// *************************************************************************** *
// *                                                                           *
// * Description:         CANDB File                                           *
// * Generated at:        2025-10-17 10:36                                     *
// * System:              SPA8410_Final2                                       *
// * Variant:             ConfigurationsSPA3d2                                 *
// * Network:             ASDM2CANFD                                           *
// *                                                                           *
// *************************************************************************** *
VERSION "ASDM2CANFD"

NS_ :

BS_ :

BU_ :  ASDM FSRL FSRR
VAL_TABLE_ ElevAlignment_States_FR 2 "MBASC_ELEV_MISALIGNED" 1 "MBASC_ELEV_ALIGNED" 0 "MBASC_ELEV_CALIBRATING" ;
VAL_TABLE_ ElevAlignment_States_FL 2 "MBASC_ELEV_MISALIGNED" 1 "MBASC_ELEV_ALIGNED" 0 "MBASC_ELEV_CALIBRATING" ;

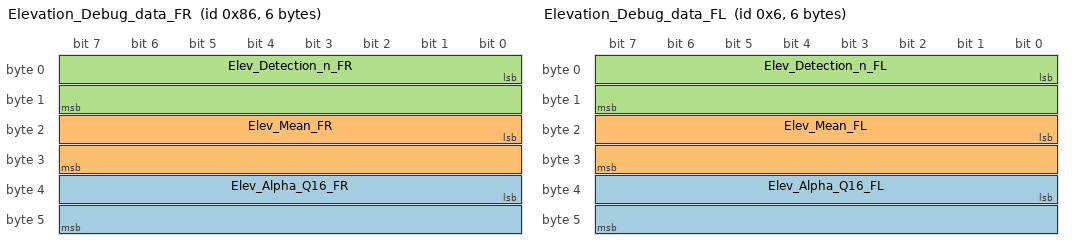
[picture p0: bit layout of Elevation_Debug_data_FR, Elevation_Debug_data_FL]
BO_ 134 Elevation_Debug_data_FR: 6 FSRR
 SG_ Elev_Alpha_Q16_FR : 32|16@1+ (1,0) [0|65535] ""  ASDM
 SG_ Elev_Mean_FR : 16|16@1- (1,0) [-32768|32767] ""  ASDM
 SG_ Elev_Detection_n_FR : 0|16@1+ (1,0) [0|65535] ""  ASDM

BO_ 6 Elevation_Debug_data_FL: 6 FSRL
 SG_ Elev_Alpha_Q16_FL : 32|16@1+ (1,0) [0|65535] ""  ASDM
 SG_ Elev_Mean_FL : 16|16@1- (1,0) [-32768|32767] ""  ASDM
 SG_ Elev_Detection_n_FL : 0|16@1+ (1,0) [0|65535] ""  ASDM

BO_ 917 MB79_PARAMETERS_FR: 24 FSRR
 SG_ Sensor_Serial_Number_FR : 0|192@1+ (1,0) [0|16777215] ""  ASDM

BO_ 789 MB79_PARAMETERS_FL: 24 FSRL
 SG_ Sensor_Serial_Number_FL : 0|192@1+ (1,0) [0|16777215] ""  ASDM

BO_ 898 MB79_SYSTEM_STATUS_FR: 8 FSRR
 SG_ Reserved_2bits_FR : 29|2@1+ (1,0) [0|3] "" Vector__XXX
 SG_ Sensor_Error_Synchronization_Err : 25|1@1+ (1,0) [0|1] "" Vector__XXX
 SG_ Sensor_Error_Supply_Error_FR : 24|1@1+ (1,0) [0|1] "" Vector__XXX
 SG_ Sensor_Error_Software_Incompatib : 27|1@1+ (1,0) [0|1] "" Vector__XXX
 SG_ Sensor_Error_Security_Breach_FR : 28|1@1+ (1,0) [0|1] "" Vector__XXX
 SG_ Sensor_Error_Position_Error_FR : 19|1@1+ (1,0) [0|1] "" Vector__XXX
 SG_ Sensor_Error_Misaligned_FR : 20|1@1+ (1,0) [0|1] "" Vector__XXX
 SG_ Sensor_Error_Internal_Failure_FR : 17|1@1+ (1,0) [0|1] "" Vector__XXX
 SG_ Sensor_Error_Interference_FR : 22|1@1+ (1,0) [0|1] "" Vector__XXX
 SG_ Sensor_Error_Initialization_FR : 23|1@1+ (1,0) [0|1] "" Vector__XXX
 SG_ Sensor_Error_HW_Error_FR : 26|1@1+ (1,0) [0|1] "" Vector__XXX
 SG_ Sensor_Error_Communication_FR : 16|1@1+ (1,0) [0|1] "" Vector__XXX
 SG_ Sensor_Error_Calibration_Error_F : 18|1@1+ (1,0) [0|1] "" Vector__XXX
 SG_ Sensor_Error_Blocked_FR : 21|1@1+ (1,0) [0|1] "" Vector__XXX
 SG_ Heater_Trigger_FR : 31|1@1+ (1,0) [0|1] "" Vector__XXX
 SG_ Sensor_Operation_Mode_FR : 12|4@1+ (1,0) [0|15] ""  ASDM
 SG_ Clock_SystemStatus_FR : 8|4@1+ (1,0) [0|15] ""  ASDM
 SG_ CRC_SystemStatus_FR : 0|8@1+ (1,0) [0|255] ""  ASDM

BO_ 770 MB79_SYSTEM_STATUS_FL: 8 FSRL
 SG_ Reserved_2bits_FL : 29|2@1+ (1,0) [0|3] "" Vector__XXX
 SG_ Sensor_Error_Synchronizatio_0000 : 25|1@1+ (1,0) [0|1] "" Vector__XXX
 SG_ Sensor_Error_Supply_Error_FL : 24|1@1+ (1,0) [0|1] "" Vector__XXX
 SG_ Sensor_Error_Software_Incom_0000 : 27|1@1+ (1,0) [0|1] "" Vector__XXX
 SG_ Sensor_Error_Security_Breach_FL : 28|1@1+ (1,0) [0|1] "" Vector__XXX
 SG_ Sensor_Error_Position_Error_FL : 19|1@1+ (1,0) [0|1] "" Vector__XXX
 SG_ Sensor_Error_Misaligned_FL : 20|1@1+ (1,0) [0|1] "" Vector__XXX
 SG_ Sensor_Error_Internal_Failure_FL : 17|1@1+ (1,0) [0|1] "" Vector__XXX
 SG_ Sensor_Error_Interference_FL : 22|1@1+ (1,0) [0|1] "" Vector__XXX
 SG_ Sensor_Error_Initialization_FL : 23|1@1+ (1,0) [0|1] "" Vector__XXX
 SG_ Sensor_Error_HW_Error_FL : 26|1@1+ (1,0) [0|1] "" Vector__XXX
 SG_ Sensor_Error_Communication_FL : 16|1@1+ (1,0) [0|1] "" Vector__XXX
 SG_ Sensor_Error_Calibration_Er_0000 : 18|1@1+ (1,0) [0|1] "" Vector__XXX
 SG_ Sensor_Error_Blocked_FL : 21|1@1+ (1,0) [0|1] "" Vector__XXX
 SG_ Heater_Trigger_FL : 31|1@1+ (1,0) [0|1] "" Vector__XXX
 SG_ Sensor_Operation_Mode_FL : 12|4@1+ (1,0) [0|15] ""  ASDM
 SG_ Clock_SystemStatus_FL : 8|4@1+ (1,0) [0|15] ""  ASDM
 SG_ CRC_SystemStatus_FL : 0|8@1+ (1,0) [0|255] ""  ASDM

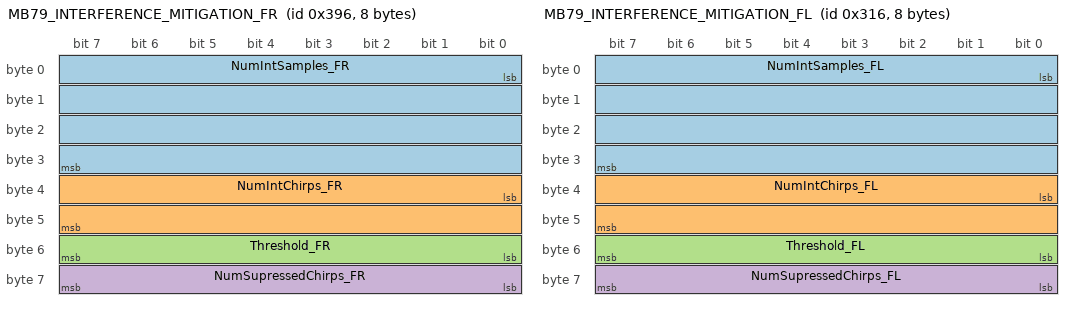
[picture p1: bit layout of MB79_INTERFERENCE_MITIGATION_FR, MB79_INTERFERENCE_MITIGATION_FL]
BO_ 918 MB79_INTERFERENCE_MITIGATION_FR: 8 FSRR
 SG_ NumIntSamples_FR : 0|32@1+ (1,0) [0|16777215] ""  ASDM
 SG_ NumIntChirps_FR : 32|16@1+ (1,0) [0|255] ""  ASDM
 SG_ Threshold_FR : 48|8@1+ (1,0) [0|65535] ""  ASDM
 SG_ NumSupressedChirps_FR : 56|8@1+ (1,0) [0|255] ""  ASDM

BO_ 790 MB79_INTERFERENCE_MITIGATION_FL: 8 FSRL
 SG_ NumIntSamples_FL : 0|32@1+ (1,0) [0|16777215] ""  ASDM
 SG_ NumIntChirps_FL : 32|16@1+ (1,0) [0|255] ""  ASDM
 SG_ Threshold_FL : 48|8@1+ (1,0) [0|65535] ""  ASDM
 SG_ NumSupressedChirps_FL : 56|8@1+ (1,0) [0|255] ""  ASDM

BO_ 2047 AsdmToAllFuncAsdm2CanDiagReqFrame : 64 ASDM
 SG_ AsdmToAllFuncAsdm2CanDiagReqNpdu : 7|512@0+ (1,0) [0|0] "" FSRL, FSRR

BO_ 1937 AsdmToFsrlAsdm2CanDiagReqFrame : 64 ASDM
 SG_ AsdmToFsrlAsdm2CanDiagReqNpdu : 7|512@0+ (1,0) [0|0] "" FSRL

BO_ 1938 AsdmToFsrrAsdm2CanDiagReqFrame : 64 ASDM
 SG_ AsdmToFsrrAsdm2CanDiagReqNpdu : 7|512@0+ (1,0) [0|0] "" FSRR

BO_ 1681 FsrlToAsdmAsdm2CanDiagResFrame : 64 FSRL
 SG_ FsrlToAsdmAsdm2CanDiagResNpdu : 7|512@0+ (1,0) [0|0] "" ASDM

BO_ 1682 FsrrToAsdmAsdm2CanDiagResFrame : 64 FSRR
 SG_ FsrrToAsdmAsdm2CanDiagResNpdu : 7|512@0+ (1,0) [0|0] "" ASDM

BO_ 288 ASDMtoRADAR: 20 ASDM
 SG_ Vehicle_Type : 123|8@0+ (1,0) [0|255] ""  FSRL,FSRR
 SG_ EmblmHeatrOutSts : 117|2@0+ (1,0) [0|0] ""  FSRL,FSRR
 SG_ WshngCycActv : 115|8@0+ (1,0) [0|1] ""  FSRL,FSRR
 SG_ isUsgModSts : 105|4@0+ (1,0) [0|15] ""  FSRL,FSRR
 SG_ PwrLvlElecSubtyp : 3|4@0+ (1,0) [0|15] ""  FSRL,FSRR
 SG_ PwrLvlElecMai : 7|4@0+ (1,0) [0|15] ""  FSRL,FSRR
 SG_ AmbTRawVal : 47|11@0+ (0.1,-70) [-70|134.7] "degC"  FSRL,FSRR
 SG_ AmbTRawQly : 52|2@0+ (1,0) [0|3] ""  FSRL,FSRR
 SG_ BkpOfDstTrvld : 50|21@0+ (1,0) [0|2000000] "km"  FSRL,FSRR
 SG_ CarTiGlb : 15|32@0+ (0.1,0) [0|429496729.5] "s"  FSRL,FSRR
 SG_ CarModSts1 : 81|3@0+ (1,0) [0|7] "N/A"  FSRL,FSRR
 SG_ DrvModReq : 85|4@0+ (1,0) [0|15] ""  FSRL,FSRR
 SG_ VehBattUSysU : 77|8@0+ (0.1,0) [0|25] "Volt"  FSRL,FSRR
 SG_ VehBattUSysUQf : 91|2@0+ (1,0) [0|3] ""  FSRL,FSRR
 SG_ WipgInfoWipgSpdInfo : 94|3@0+ (1,0) [0|7] ""  FSRL,FSRR
 SG_ WipgInfoWiprActv : 97|8@0+ (1,0) [0|255] ""  FSRL,FSRR
 SG_ WipgInfoWiprInWipgAr : 89|8@0+ (1,0) [0|255] ""  FSRL,FSRR

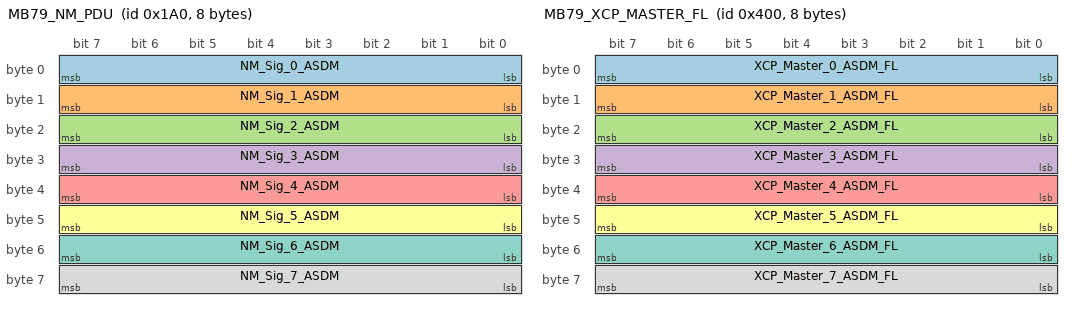
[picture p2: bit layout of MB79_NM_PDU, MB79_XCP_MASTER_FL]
BO_ 416 MB79_NM_PDU: 8 ASDM
 SG_ NM_Sig_0_ASDM : 7|8@0+ (1,0) [0|255] "N/A"  FSRL,FSRR
 SG_ NM_Sig_1_ASDM : 15|8@0+ (1,0) [0|255] "N/A"  FSRL,FSRR
 SG_ NM_Sig_2_ASDM : 23|8@0+ (1,0) [0|255] "N/A"  FSRL,FSRR
 SG_ NM_Sig_3_ASDM : 31|8@0+ (1,0) [0|255] "N/A"  FSRL,FSRR
 SG_ NM_Sig_4_ASDM : 39|8@0+ (1,0) [0|255] "N/A"  FSRL,FSRR
 SG_ NM_Sig_5_ASDM : 47|8@0+ (1,0) [0|255] "N/A"  FSRL,FSRR
 SG_ NM_Sig_6_ASDM : 55|8@0+ (1,0) [0|255] "N/A"  FSRL,FSRR
 SG_ NM_Sig_7_ASDM : 63|8@0+ (1,0) [0|255] "N/A"  FSRL,FSRR

BO_ 1024 MB79_XCP_MASTER_FL: 8 ASDM
 SG_ XCP_Master_0_ASDM_FL : 7|8@0+ (1,0) [0|255] "N/A"  FSRL
 SG_ XCP_Master_1_ASDM_FL : 15|8@0+ (1,0) [0|255] "N/A"  FSRL
 SG_ XCP_Master_2_ASDM_FL : 23|8@0+ (1,0) [0|255] "N/A"  FSRL
 SG_ XCP_Master_3_ASDM_FL : 31|8@0+ (1,0) [0|255] "N/A"  FSRL
 SG_ XCP_Master_4_ASDM_FL : 39|8@0+ (1,0) [0|255] "N/A"  FSRL
 SG_ XCP_Master_5_ASDM_FL : 47|8@0+ (1,0) [0|255] "N/A"  FSRL
 SG_ XCP_Master_6_ASDM_FL : 55|8@0+ (1,0) [0|255] "N/A"  FSRL
 SG_ XCP_Master_7_ASDM_FL : 63|8@0+ (1,0) [0|255] "N/A"  FSRL

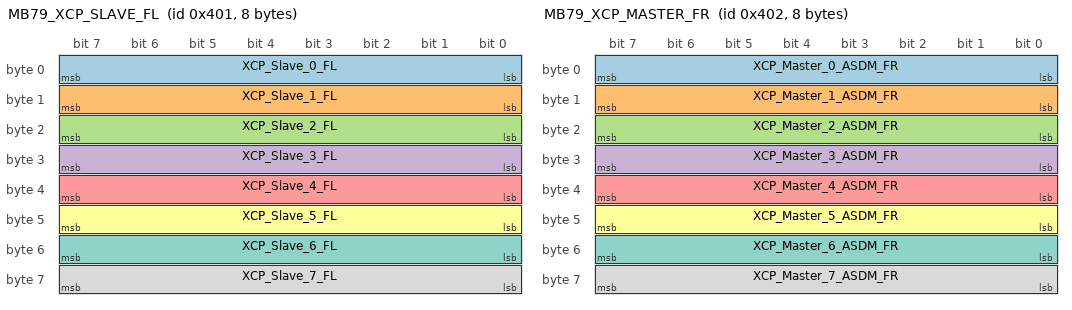
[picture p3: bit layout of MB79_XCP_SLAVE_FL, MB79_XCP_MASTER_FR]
BO_ 1025 MB79_XCP_SLAVE_FL: 8 FSRL
 SG_ XCP_Slave_0_FL : 7|8@0+ (1,0) [0|255] "N/A"  ASDM
 SG_ XCP_Slave_1_FL : 15|8@0+ (1,0) [0|255] "N/A"  ASDM
 SG_ XCP_Slave_2_FL : 23|8@0+ (1,0) [0|255] "N/A"  ASDM
 SG_ XCP_Slave_3_FL : 31|8@0+ (1,0) [0|255] "N/A"  ASDM
 SG_ XCP_Slave_4_FL : 39|8@0+ (1,0) [0|255] "N/A"  ASDM
 SG_ XCP_Slave_5_FL : 47|8@0+ (1,0) [0|255] "N/A"  ASDM
 SG_ XCP_Slave_6_FL : 55|8@0+ (1,0) [0|255] "N/A"  ASDM
 SG_ XCP_Slave_7_FL : 63|8@0+ (1,0) [0|255] "N/A"  ASDM

BO_ 1026 MB79_XCP_MASTER_FR: 8 ASDM
 SG_ XCP_Master_0_ASDM_FR : 7|8@0+ (1,0) [0|255] "N/A"  FSRR
 SG_ XCP_Master_1_ASDM_FR : 15|8@0+ (1,0) [0|255] "N/A"  FSRR
 SG_ XCP_Master_2_ASDM_FR : 23|8@0+ (1,0) [0|255] "N/A"  FSRR
 SG_ XCP_Master_3_ASDM_FR : 31|8@0+ (1,0) [0|255] "N/A"  FSRR
 SG_ XCP_Master_4_ASDM_FR : 39|8@0+ (1,0) [0|255] "N/A"  FSRR
 SG_ XCP_Master_5_ASDM_FR : 47|8@0+ (1,0) [0|255] "N/A"  FSRR
 SG_ XCP_Master_6_ASDM_FR : 55|8@0+ (1,0) [0|255] "N/A"  FSRR
 SG_ XCP_Master_7_ASDM_FR : 63|8@0+ (1,0) [0|255] "N/A"  FSRR

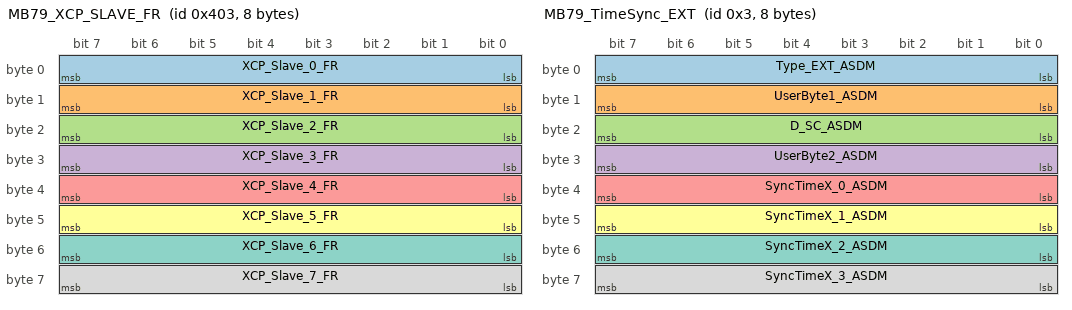
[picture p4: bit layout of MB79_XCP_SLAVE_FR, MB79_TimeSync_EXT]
BO_ 1027 MB79_XCP_SLAVE_FR: 8 FSRR
 SG_ XCP_Slave_0_FR : 7|8@0+ (1,0) [0|255] "N/A"  ASDM
 SG_ XCP_Slave_1_FR : 15|8@0+ (1,0) [0|255] "N/A"  ASDM
 SG_ XCP_Slave_2_FR : 23|8@0+ (1,0) [0|255] "N/A"  ASDM
 SG_ XCP_Slave_3_FR : 31|8@0+ (1,0) [0|255] "N/A"  ASDM
 SG_ XCP_Slave_4_FR : 39|8@0+ (1,0) [0|255] "N/A"  ASDM
 SG_ XCP_Slave_5_FR : 47|8@0+ (1,0) [0|255] "N/A"  ASDM
 SG_ XCP_Slave_6_FR : 55|8@0+ (1,0) [0|255] "N/A"  ASDM
 SG_ XCP_Slave_7_FR : 63|8@0+ (1,0) [0|255] "N/A"  ASDM

BO_ 3 MB79_TimeSync_EXT: 8 ASDM
 SG_ Type_EXT_ASDM : 7|8@0+ (1,0) [0|255] "N/A"  FSRL,FSRR
 SG_ UserByte1_ASDM : 15|8@0+ (1,0) [0|255] "N/A"  FSRL,FSRR
 SG_ D_SC_ASDM : 23|8@0+ (1,0) [0|255] "N/A"  FSRL,FSRR
 SG_ UserByte2_ASDM : 31|8@0+ (1,0) [0|255] "N/A"  FSRL,FSRR
 SG_ SyncTimeX_0_ASDM : 39|8@0+ (1,0) [0|255] "N/A"  FSRL,FSRR
 SG_ SyncTimeX_1_ASDM : 47|8@0+ (1,0) [0|255] "N/A"  FSRL,FSRR
 SG_ SyncTimeX_2_ASDM : 55|8@0+ (1,0) [0|255] "N/A"  FSRL,FSRR
 SG_ SyncTimeX_3_ASDM : 63|8@0+ (1,0) [0|255] "N/A"  FSRL,FSRR

BO_ 257 MB79_DETECTION_HEADER_FL: 64 FSRL
 SG_ CRC_DetectionList_FL : 0|32@1+ (1,0) [0|4294967295] "N/A"  ASDM
 SG_ CycleNumber_FL : 32|32@1+ (1,0) [0|4294967295] "cycle"  ASDM
 SG_ TimeStamp_FL : 64|32@1+ (1,0) [0|4294967295] "us"  ASDM
 SG_ HostVelEst_FL : 96|16@1- (1,0) [-2000|14000] "cm/s"  ASDM
 SG_ HostYawEst_FL : 112|16@1- (0.000977,0) [-2|2] "rad/s"  ASDM
 SG_ HostAccelLatEst_FL : 128|16@1- (1,0) [-2000|2000] "cm/s.s"  ASDM
 SG_ HostAccelLongEst_FL : 144|16@1- (1,0) [-2000|2000] "cm/s.s"  ASDM
 SG_ Sensor_Elev_Angle_corr_FL : 160|16@1- (0.1,0) [-180|655.35] "degree"  ASDM
 SG_ Alignment_update_cycle_FL : 176|8@1+ (1,0) [0|255] "N/A"  ASDM
 SG_ Velocity_Correction_FL : 184|16@1- (0.0196,0) [-5|5] "%"  ASDM
 SG_ Sensor_Pos_X_FL : 200|16@1- (0.001,0) [-20|65.535] "m"  ASDM
 SG_ Sensor_Pos_Y_FL : 216|16@1- (0.001,0) [-20|65.535] "m"  ASDM
 SG_ Orientation_Angle_FL : 232|16@1- (0.1,0) [-180|180] "degree"  ASDM
 SG_ Calibrated_Angle_Az_FL : 248|16@1- (0.01,0) [-180|180] "degree"  ASDM
 SG_ Sensor_Pos_Z_FL : 264|8@1+ (0.01,0) [0|2.55] "m"  ASDM
 SG_ Sensor_FoV_Max_FL : 272|8@1+ (1,0) [0|255] "degree"  ASDM
 SG_ Sensor_FoV_Min_FL : 280|8@1+ (1,0) [0|255] "degree"  ASDM
 SG_ BW100KHz1_FL : 288|16@1+ (100,0) [0|6553500] "N/A"  ASDM
 SG_ UnambiguousVelMeas1_FL : 304|8@1+ (1,0) [0|255] "N/A"  ASDM
 SG_ Radar_Sensor_type_FL : 312|8@1+ (1,0) [0|255] "N/A"  ASDM
 SG_ Sensor_Position_ID_FL : 320|4@1+ (1,0) [0|15] "N/A"  ASDM
 SG_ DetectionListVersion_FL : 324|4@1+ (1,0) [0|15] "N/A"  ASDM
 SG_ Detection_Header_Version_FL : 328|4@1+ (1,0) [0|15] "N/A"  ASDM
 SG_ numInfrastructureDetected_FL : 332|10@1+ (1,0) [0|1023] "detection"  ASDM
 SG_ numNonInfraDetected_FL : 342|10@1+ (1,0) [0|1023] "detection"  ASDM
 SG_ numFreespaceDetections_FL : 352|2@1+ (1,0) [0|3] "detection"  ASDM
 SG_ interferenceDetected_FL : 354|2@1+ (1,0) [0|3] "N/A"  ASDM
 SG_ Blockage_Confidence_FL : 356|8@1+ (0.5,0) [0|200] "%"  ASDM
 SG_ Blockage_Level_FL : 364|8@1+ (0.5,0) [0|200] "%"  ASDM
 SG_ Blockage_Status_FL : 372|3@1+ (1,0) [0|7] "N/A"  ASDM
 SG_ max_instrumented_range_2m_FL : 375|8@1+ (2,0) [0|510] "m"  ASDM
 SG_ Sensor_Operation_Mode_FL : 383|4@1+ (1,0) [0|15] "Mode"  ASDM
 SG_ AutoAlignment_Status_FL : 387|4@1+ (1,0) [0|15] "N/A"  ASDM
 SG_ Testing_Mode_FL : 391|4@1+ (1,0) [0|15] "N/A"  ASDM
 SG_ NearZoneDetectionsCount_FL : 395|10@1+ (1,0) [0|512] "detection" Vector__XXX
 SG_ HorizonZoneDetectionsCount_FL : 405|10@1+ (1,0) [0|512] "detection" Vector__XXX
 SG_ Reserved_1byte_FL : 415|8@1- (1,0) [0|0] "" Vector__XXX
 SG_ Detection_Data_Mode_FL : 423|1@1+ (1,0) [0|1] "" Vector__XXX
 SG_ Reserved_3bits_FL : 424|3@1- (1,0) [0|0] "" Vector__XXX
 SG_ AR_Counter_DetectionList_FL : 427|32@1+ (1,0) [0|4294967295] "N/A"  ASDM
 SG_ MAC_DetectionList_FL : 459|24@1+ (1,0) [0|16777215] "N/A"  ASDM
 SG_ Sensor_Topology_FL : 483|1@1+ (1,0) [0|1] "N/A"  ASDM
 SG_ AASC_Calibration_flag_FL : 484|1@1+ (1,0) [0|1] "N/A"  ASDM
 SG_ selected_chirp_config_FL : 485|3@1+ (1,0) [0|7] "N/A"  ASDM
 SG_ FC1MHz1_FL : 488|16@1+ (10,0) [0|65535] "MHz"  ASDM
 SG_ ElevAlignment_Status_FL : 504|2@1+ (1,0) [0|3] "" Vector__XXX

BO_ 304 MB79_DETECTIONS_0_FL: 64 FSRL
 SG_ zipy_serialized_data_0_FL : 0|32@1- (0.1,0) [-102.4|429496729.5] "degree"  ASDM
 SG_ zipy_serialized_data_1_FL : 32|32@1- (0.1,0) [-102.4|429496729.5] "degree"  ASDM
 SG_ zipy_serialized_data_2_FL : 64|32@1- (0.1,0) [-102.4|429496729.5] "degree"  ASDM
 SG_ zipy_serialized_data_3_FL : 96|32@1- (0.1,0) [-102.4|429496729.5] "degree"  ASDM
 SG_ zipy_serialized_data_4_FL : 128|32@1- (0.1,0) [-102.4|429496729.5] "degree"  ASDM
 SG_ zipy_serialized_data_5_FL : 160|32@1- (0.1,0) [-102.4|429496729.5] "degree"  ASDM
 SG_ zipy_serialized_data_6_FL : 192|32@1- (0.1,0) [-102.4|429496729.5] "degree"  ASDM
 SG_ zipy_serialized_data_7_FL : 224|32@1- (0.1,0) [-102.4|429496729.5] "degree"  ASDM
 SG_ zipy_serialized_data_8_FL : 256|32@1- (0.1,0) [-102.4|429496729.5] "degree"  ASDM
 SG_ zipy_serialized_data_9_FL : 288|32@1- (0.1,0) [-102.4|429496729.5] "degree"  ASDM
 SG_ zipy_serialized_data_10_FL : 320|32@1- (0.1,0) [-102.4|429496729.5] "degree"  ASDM
 SG_ zipy_serialized_data_11_FL : 352|32@1- (0.1,0) [-102.4|429496729.5] "degree"  ASDM
 SG_ zipy_serialized_data_12_FL : 384|32@1- (0.1,0) [-102.4|429496729.5] "degree"  ASDM
 SG_ zipy_serialized_data_13_FL : 416|32@1- (0.1,0) [-102.4|429496729.5] "degree"  ASDM
 SG_ zipy_serialized_data_14_FL : 448|32@1- (0.1,0) [-102.4|429496729.5] "degree"  ASDM
 SG_ zipy_serialized_data_15_FL : 480|32@1- (0.1,0) [-102.4|429496729.5] "degree"  ASDM

BO_ 305 MB79_DETECTIONS_1_FL: 64 FSRL
 SG_ zipy_serialized_data_16_FL : 0|32@1- (0.1,0) [-102.4|429496729.5] "degree"  ASDM
 SG_ zipy_serialized_data_17_FL : 32|32@1- (0.1,0) [-102.4|429496729.5] "degree"  ASDM
 SG_ zipy_serialized_data_18_FL : 64|32@1- (0.1,0) [-102.4|429496729.5] "degree"  ASDM
 SG_ zipy_serialized_data_19_FL : 96|32@1- (0.1,0) [-102.4|429496729.5] "degree"  ASDM
 SG_ zipy_serialized_data_20_FL : 128|32@1- (0.1,0) [-102.4|429496729.5] "degree"  ASDM
 SG_ zipy_serialized_data_21_FL : 160|32@1- (0.1,0) [-102.4|429496729.5] "degree"  ASDM
 SG_ zipy_serialized_data_22_FL : 192|32@1- (0.1,0) [-102.4|429496729.5] "degree"  ASDM
 SG_ zipy_serialized_data_23_FL : 224|32@1- (0.1,0) [-102.4|429496729.5] "degree"  ASDM
 SG_ zipy_serialized_data_24_FL : 256|32@1- (0.1,0) [-102.4|429496729.5] "degree"  ASDM
 SG_ zipy_serialized_data_25_FL : 288|32@1- (0.1,0) [-102.4|429496729.5] "degree"  ASDM
 SG_ zipy_serialized_data_26_FL : 320|32@1- (0.1,0) [-102.4|429496729.5] "degree"  ASDM
 SG_ zipy_serialized_data_27_FL : 352|32@1- (0.1,0) [-102.4|429496729.5] "degree"  ASDM
 SG_ zipy_serialized_data_28_FL : 384|32@1- (0.1,0) [-102.4|429496729.5] "degree"  ASDM
 SG_ zipy_serialized_data_29_FL : 416|32@1- (0.1,0) [-102.4|429496729.5] "degree"  ASDM
 SG_ zipy_serialized_data_30_FL : 448|32@1- (0.1,0) [-102.4|429496729.5] "degree"  ASDM
 SG_ zipy_serialized_data_31_FL : 480|32@1- (0.1,0) [-102.4|429496729.5] "degree"  ASDM

BO_ 306 MB79_DETECTIONS_2_FL: 64 FSRL
 SG_ zipy_serialized_data_32_FL : 0|32@1- (0.1,0) [-102.4|429496729.5] "degree"  ASDM
 SG_ zipy_serialized_data_33_FL : 32|32@1- (0.1,0) [-102.4|429496729.5] "degree"  ASDM
 SG_ zipy_serialized_data_34_FL : 64|32@1- (0.1,0) [-102.4|429496729.5] "degree"  ASDM
 SG_ zipy_serialized_data_35_FL : 96|32@1- (0.1,0) [-102.4|429496729.5] "degree"  ASDM
 SG_ zipy_serialized_data_36_FL : 128|32@1- (0.1,0) [-102.4|429496729.5] "degree"  ASDM
 SG_ zipy_serialized_data_37_FL : 160|32@1- (0.1,0) [-102.4|429496729.5] "degree"  ASDM
 SG_ zipy_serialized_data_38_FL : 192|32@1- (0.1,0) [-102.4|429496729.5] "degree"  ASDM
 SG_ zipy_serialized_data_39_FL : 224|32@1- (0.1,0) [-102.4|429496729.5] "degree"  ASDM
 SG_ zipy_serialized_data_40_FL : 256|32@1- (0.1,0) [-102.4|429496729.5] "degree"  ASDM
 SG_ zipy_serialized_data_41_FL : 288|32@1- (0.1,0) [-102.4|429496729.5] "degree"  ASDM
 SG_ zipy_serialized_data_42_FL : 320|32@1- (0.1,0) [-102.4|429496729.5] "degree"  ASDM
 SG_ zipy_serialized_data_43_FL : 352|32@1- (0.1,0) [-102.4|429496729.5] "degree"  ASDM
 SG_ zipy_serialized_data_44_FL : 384|32@1- (0.1,0) [-102.4|429496729.5] "degree"  ASDM
 SG_ zipy_serialized_data_45_FL : 416|32@1- (0.1,0) [-102.4|429496729.5] "degree"  ASDM
 SG_ zipy_serialized_data_46_FL : 448|32@1- (0.1,0) [-102.4|429496729.5] "degree"  ASDM
 SG_ zipy_serialized_data_47_FL : 480|32@1- (0.1,0) [-102.4|429496729.5] "degree"  ASDM

BO_ 307 MB79_DETECTIONS_3_FL: 64 FSRL
 SG_ zipy_serialized_data_48_FL : 0|32@1- (0.1,0) [-102.4|429496729.5] "degree"  ASDM
 SG_ zipy_serialized_data_49_FL : 32|32@1- (0.1,0) [-102.4|429496729.5] "degree"  ASDM
 SG_ zipy_serialized_data_50_FL : 64|32@1- (0.1,0) [-102.4|429496729.5] "degree"  ASDM
 SG_ zipy_serialized_data_51_FL : 96|32@1- (0.1,0) [-102.4|429496729.5] "degree"  ASDM
 SG_ zipy_serialized_data_52_FL : 128|32@1- (0.1,0) [-102.4|429496729.5] "degree"  ASDM
 SG_ zipy_serialized_data_53_FL : 160|32@1- (0.1,0) [-102.4|429496729.5] "degree"  ASDM
 SG_ zipy_serialized_data_54_FL : 192|32@1- (0.1,0) [-102.4|429496729.5] "degree"  ASDM
 SG_ zipy_serialized_data_55_FL : 224|32@1- (0.1,0) [-102.4|429496729.5] "degree"  ASDM
 SG_ zipy_serialized_data_56_FL : 256|32@1- (0.1,0) [-102.4|429496729.5] "degree"  ASDM
 SG_ zipy_serialized_data_57_FL : 288|32@1- (0.1,0) [-102.4|429496729.5] "degree"  ASDM
 SG_ zipy_serialized_data_58_FL : 320|32@1- (0.1,0) [-102.4|429496729.5] "degree"  ASDM
 SG_ zipy_serialized_data_59_FL : 352|32@1- (0.1,0) [-102.4|429496729.5] "degree"  ASDM
 SG_ zipy_serialized_data_60_FL : 384|32@1- (0.1,0) [-102.4|429496729.5] "degree"  ASDM
 SG_ zipy_serialized_data_61_FL : 416|32@1- (0.1,0) [-102.4|429496729.5] "degree"  ASDM
 SG_ zipy_serialized_data_62_FL : 448|32@1- (0.1,0) [-102.4|429496729.5] "degree"  ASDM
 SG_ zipy_serialized_data_63_FL : 480|32@1- (0.1,0) [-102.4|429496729.5] "degree"  ASDM

BO_ 308 MB79_DETECTIONS_4_FL: 64 FSRL
 SG_ zipy_serialized_data_64_FL : 0|32@1- (0.1,0) [-102.4|429496729.5] "degree"  ASDM
 SG_ zipy_serialized_data_65_FL : 32|32@1- (0.1,0) [-102.4|429496729.5] "degree"  ASDM
 SG_ zipy_serialized_data_66_FL : 64|32@1- (0.1,0) [-102.4|429496729.5] "degree"  ASDM
 SG_ zipy_serialized_data_67_FL : 96|32@1- (0.1,0) [-102.4|429496729.5] "degree"  ASDM
 SG_ zipy_serialized_data_68_FL : 128|32@1- (0.1,0) [-102.4|429496729.5] "degree"  ASDM
 SG_ zipy_serialized_data_69_FL : 160|32@1- (0.1,0) [-102.4|429496729.5] "degree"  ASDM
 SG_ zipy_serialized_data_70_FL : 192|32@1- (0.1,0) [-102.4|429496729.5] "degree"  ASDM
 SG_ zipy_serialized_data_71_FL : 224|32@1- (0.1,0) [-102.4|429496729.5] "degree"  ASDM
 SG_ zipy_serialized_data_72_FL : 256|32@1- (0.1,0) [-102.4|429496729.5] "degree"  ASDM
 SG_ zipy_serialized_data_73_FL : 288|32@1- (0.1,0) [-102.4|429496729.5] "degree"  ASDM
 SG_ zipy_serialized_data_74_FL : 320|32@1- (0.1,0) [-102.4|429496729.5] "degree"  ASDM
 SG_ zipy_serialized_data_75_FL : 352|32@1- (0.1,0) [-102.4|429496729.5] "degree"  ASDM
 SG_ zipy_serialized_data_76_FL : 384|32@1- (0.1,0) [-102.4|429496729.5] "degree"  ASDM
 SG_ zipy_serialized_data_77_FL : 416|32@1- (0.1,0) [-102.4|429496729.5] "degree"  ASDM
 SG_ zipy_serialized_data_78_FL : 448|32@1- (0.1,0) [-102.4|429496729.5] "degree"  ASDM
 SG_ zipy_serialized_data_79_FL : 480|32@1- (0.1,0) [-102.4|429496729.5] "degree"  ASDM

BO_ 309 MB79_DETECTIONS_5_FL: 64 FSRL
 SG_ zipy_serialized_data_80_FL : 0|32@1- (0.1,0) [-102.4|429496729.5] "degree"  ASDM
 SG_ zipy_serialized_data_81_FL : 32|32@1- (0.1,0) [-102.4|429496729.5] "degree"  ASDM
 SG_ zipy_serialized_data_82_FL : 64|32@1- (0.1,0) [-102.4|429496729.5] "degree"  ASDM
 SG_ zipy_serialized_data_83_FL : 96|32@1- (0.1,0) [-102.4|429496729.5] "degree"  ASDM
 SG_ zipy_serialized_data_84_FL : 128|32@1- (0.1,0) [-102.4|429496729.5] "degree"  ASDM
 SG_ zipy_serialized_data_85_FL : 160|32@1- (0.1,0) [-102.4|429496729.5] "degree"  ASDM
 SG_ zipy_serialized_data_86_FL : 192|32@1- (0.1,0) [-102.4|429496729.5] "degree"  ASDM
 SG_ zipy_serialized_data_87_FL : 224|32@1- (0.1,0) [-102.4|429496729.5] "degree"  ASDM
 SG_ zipy_serialized_data_88_FL : 256|32@1- (0.1,0) [-102.4|429496729.5] "degree"  ASDM
 SG_ zipy_serialized_data_89_FL : 288|32@1- (0.1,0) [-102.4|429496729.5] "degree"  ASDM
 SG_ zipy_serialized_data_90_FL : 320|32@1- (0.1,0) [-102.4|429496729.5] "degree"  ASDM
 SG_ zipy_serialized_data_91_FL : 352|32@1- (0.1,0) [-102.4|429496729.5] "degree"  ASDM
 SG_ zipy_serialized_data_92_FL : 384|32@1- (0.1,0) [-102.4|429496729.5] "degree"  ASDM
 SG_ zipy_serialized_data_93_FL : 416|32@1- (0.1,0) [-102.4|429496729.5] "degree"  ASDM
 SG_ zipy_serialized_data_94_FL : 448|32@1- (0.1,0) [-102.4|429496729.5] "degree"  ASDM
 SG_ zipy_serialized_data_95_FL : 480|32@1- (0.1,0) [-102.4|429496729.5] "degree"  ASDM

BO_ 310 MB79_DETECTIONS_6_FL: 64 FSRL
 SG_ zipy_serialized_data_96_FL : 0|32@1- (0.1,0) [-102.4|429496729.5] "degree"  ASDM
 SG_ zipy_serialized_data_97_FL : 32|32@1- (0.1,0) [-102.4|429496729.5] "degree"  ASDM
 SG_ zipy_serialized_data_98_FL : 64|32@1- (0.1,0) [-102.4|429496729.5] "degree"  ASDM
 SG_ zipy_serialized_data_99_FL : 96|32@1- (0.1,0) [-102.4|429496729.5] "degree"  ASDM
 SG_ zipy_serialized_data_100_FL : 128|32@1- (0.1,0) [-102.4|429496729.5] "degree"  ASDM
 SG_ zipy_serialized_data_101_FL : 160|32@1- (0.1,0) [-102.4|429496729.5] "degree"  ASDM
 SG_ zipy_serialized_data_102_FL : 192|32@1- (0.1,0) [-102.4|429496729.5] "degree"  ASDM
 SG_ zipy_serialized_data_103_FL : 224|32@1- (0.1,0) [-102.4|429496729.5] "degree"  ASDM
 SG_ zipy_serialized_data_104_FL : 256|32@1- (0.1,0) [-102.4|429496729.5] "degree"  ASDM
 SG_ zipy_serialized_data_105_FL : 288|32@1- (0.1,0) [-102.4|429496729.5] "degree"  ASDM
 SG_ zipy_serialized_data_106_FL : 320|32@1- (0.1,0) [-102.4|429496729.5] "degree"  ASDM
 SG_ zipy_serialized_data_107_FL : 352|32@1- (0.1,0) [-102.4|429496729.5] "degree"  ASDM
 SG_ zipy_serialized_data_108_FL : 384|32@1- (0.1,0) [-102.4|429496729.5] "degree"  ASDM
 SG_ zipy_serialized_data_109_FL : 416|32@1- (0.1,0) [-102.4|429496729.5] "degree"  ASDM
 SG_ zipy_serialized_data_110_FL : 448|32@1- (0.1,0) [-102.4|429496729.5] "degree"  ASDM
 SG_ zipy_serialized_data_111_FL : 480|32@1- (0.1,0) [-102.4|429496729.5] "degree"  ASDM

BO_ 311 MB79_DETECTIONS_7_FL: 64 FSRL
 SG_ zipy_serialized_data_112_FL : 0|32@1- (0.1,0) [-102.4|429496729.5] "degree"  ASDM
 SG_ zipy_serialized_data_113_FL : 32|32@1- (0.1,0) [-102.4|429496729.5] "degree"  ASDM
 SG_ zipy_serialized_data_114_FL : 64|32@1- (0.1,0) [-102.4|429496729.5] "degree"  ASDM
 SG_ zipy_serialized_data_115_FL : 96|32@1- (0.1,0) [-102.4|429496729.5] "degree"  ASDM
 SG_ zipy_serialized_data_116_FL : 128|32@1- (0.1,0) [-102.4|429496729.5] "degree"  ASDM
 SG_ zipy_serialized_data_117_FL : 160|32@1- (0.1,0) [-102.4|429496729.5] "degree"  ASDM
 SG_ zipy_serialized_data_118_FL : 192|32@1- (0.1,0) [-102.4|429496729.5] "degree"  ASDM
 SG_ zipy_serialized_data_119_FL : 224|32@1- (0.1,0) [-102.4|429496729.5] "degree"  ASDM
 SG_ zipy_serialized_data_120_FL : 256|32@1- (0.1,0) [-102.4|429496729.5] "degree"  ASDM
 SG_ zipy_serialized_data_121_FL : 288|32@1- (0.1,0) [-102.4|429496729.5] "degree"  ASDM
 SG_ zipy_serialized_data_122_FL : 320|32@1- (0.1,0) [-102.4|429496729.5] "degree"  ASDM
 SG_ zipy_serialized_data_123_FL : 352|32@1- (0.1,0) [-102.4|429496729.5] "degree"  ASDM
 SG_ zipy_serialized_data_124_FL : 384|32@1- (0.1,0) [-102.4|429496729.5] "degree"  ASDM
 SG_ zipy_serialized_data_125_FL : 416|32@1- (0.1,0) [-102.4|429496729.5] "degree"  ASDM
 SG_ zipy_serialized_data_126_FL : 448|32@1- (0.1,0) [-102.4|429496729.5] "degree"  ASDM
 SG_ zipy_serialized_data_127_FL : 480|32@1- (0.1,0) [-102.4|429496729.5] "degree"  ASDM

BO_ 312 MB79_DETECTIONS_8_FL: 64 FSRL
 SG_ zipy_serialized_data_128_FL : 0|32@1- (0.1,0) [-102.4|429496729.5] "degree"  ASDM
 SG_ zipy_serialized_data_129_FL : 32|32@1- (0.1,0) [-102.4|429496729.5] "degree"  ASDM
 SG_ zipy_serialized_data_130_FL : 64|32@1- (0.1,0) [-102.4|429496729.5] "degree"  ASDM
 SG_ zipy_serialized_data_131_FL : 96|32@1- (0.1,0) [-102.4|429496729.5] "degree"  ASDM
 SG_ zipy_serialized_data_132_FL : 128|32@1- (0.1,0) [-102.4|429496729.5] "degree"  ASDM
 SG_ zipy_serialized_data_133_FL : 160|32@1- (0.1,0) [-102.4|429496729.5] "degree"  ASDM
 SG_ zipy_serialized_data_134_FL : 192|32@1- (0.1,0) [-102.4|429496729.5] "degree"  ASDM
 SG_ zipy_serialized_data_135_FL : 224|32@1- (0.1,0) [-102.4|429496729.5] "degree"  ASDM
 SG_ zipy_serialized_data_136_FL : 256|32@1- (0.1,0) [-102.4|429496729.5] "degree"  ASDM
 SG_ zipy_serialized_data_137_FL : 288|32@1- (0.1,0) [-102.4|429496729.5] "degree"  ASDM
 SG_ zipy_serialized_data_138_FL : 320|32@1- (0.1,0) [-102.4|429496729.5] "degree"  ASDM
 SG_ zipy_serialized_data_139_FL : 352|32@1- (0.1,0) [-102.4|429496729.5] "degree"  ASDM
 SG_ zipy_serialized_data_140_FL : 384|32@1- (0.1,0) [-102.4|429496729.5] "degree"  ASDM
 SG_ zipy_serialized_data_141_FL : 416|32@1- (0.1,0) [-102.4|429496729.5] "degree"  ASDM
 SG_ zipy_serialized_data_142_FL : 448|32@1- (0.1,0) [-102.4|429496729.5] "degree"  ASDM
 SG_ zipy_serialized_data_143_FL : 480|32@1- (0.1,0) [-102.4|429496729.5] "degree"  ASDM

BO_ 313 MB79_DETECTIONS_9_FL: 64 FSRL
 SG_ zipy_serialized_data_144_FL : 0|32@1- (0.1,0) [-102.4|429496729.5] "degree"  ASDM
 SG_ zipy_serialized_data_145_FL : 32|32@1- (0.1,0) [-102.4|429496729.5] "degree"  ASDM
 SG_ zipy_serialized_data_146_FL : 64|32@1- (0.1,0) [-102.4|429496729.5] "degree"  ASDM
 SG_ zipy_serialized_data_147_FL : 96|32@1- (0.1,0) [-102.4|429496729.5] "degree"  ASDM
 SG_ zipy_serialized_data_148_FL : 128|32@1- (0.1,0) [-102.4|429496729.5] "degree"  ASDM
 SG_ zipy_serialized_data_149_FL : 160|32@1- (0.1,0) [-102.4|429496729.5] "degree"  ASDM
 SG_ zipy_serialized_data_150_FL : 192|32@1- (0.1,0) [-102.4|429496729.5] "degree"  ASDM
 SG_ zipy_serialized_data_151_FL : 224|32@1- (0.1,0) [-102.4|429496729.5] "degree"  ASDM
 SG_ zipy_serialized_data_152_FL : 256|32@1- (0.1,0) [-102.4|429496729.5] "degree"  ASDM
 SG_ zipy_serialized_data_153_FL : 288|32@1- (0.1,0) [-102.4|429496729.5] "degree"  ASDM
 SG_ zipy_serialized_data_154_FL : 320|32@1- (0.1,0) [-102.4|429496729.5] "degree"  ASDM
 SG_ zipy_serialized_data_155_FL : 352|32@1- (0.1,0) [-102.4|429496729.5] "degree"  ASDM
 SG_ zipy_serialized_data_156_FL : 384|32@1- (0.1,0) [-102.4|429496729.5] "degree"  ASDM
 SG_ zipy_serialized_data_157_FL : 416|32@1- (0.1,0) [-102.4|429496729.5] "degree"  ASDM
 SG_ zipy_serialized_data_158_FL : 448|32@1- (0.1,0) [-102.4|429496729.5] "degree"  ASDM
 SG_ zipy_serialized_data_159_FL : 480|32@1- (0.1,0) [-102.4|429496729.5] "degree"  ASDM

BO_ 314 MB79_DETECTIONS_10_FL: 64 FSRL
 SG_ zipy_serialized_data_160_FL : 0|32@1- (0.1,0) [-102.4|429496729.5] "degree"  ASDM
 SG_ zipy_serialized_data_161_FL : 32|32@1- (0.1,0) [-102.4|429496729.5] "degree"  ASDM
 SG_ zipy_serialized_data_162_FL : 64|32@1- (0.1,0) [-102.4|429496729.5] "degree"  ASDM
 SG_ zipy_serialized_data_163_FL : 96|32@1- (0.1,0) [-102.4|429496729.5] "degree"  ASDM
 SG_ zipy_serialized_data_164_FL : 128|32@1- (0.1,0) [-102.4|429496729.5] "degree"  ASDM
 SG_ zipy_serialized_data_165_FL : 160|32@1- (0.1,0) [-102.4|429496729.5] "degree"  ASDM
 SG_ zipy_serialized_data_166_FL : 192|32@1- (0.1,0) [-102.4|429496729.5] "degree"  ASDM
 SG_ zipy_serialized_data_167_FL : 224|32@1- (0.1,0) [-102.4|429496729.5] "degree"  ASDM
 SG_ zipy_serialized_data_168_FL : 256|32@1- (0.1,0) [-102.4|429496729.5] "degree"  ASDM
 SG_ zipy_serialized_data_169_FL : 288|32@1- (0.1,0) [-102.4|429496729.5] "degree"  ASDM
 SG_ zipy_serialized_data_170_FL : 320|32@1- (0.1,0) [-102.4|429496729.5] "degree"  ASDM
 SG_ zipy_serialized_data_171_FL : 352|32@1- (0.1,0) [-102.4|429496729.5] "degree"  ASDM
 SG_ zipy_serialized_data_172_FL : 384|32@1- (0.1,0) [-102.4|429496729.5] "degree"  ASDM
 SG_ zipy_serialized_data_173_FL : 416|32@1- (0.1,0) [-102.4|429496729.5] "degree"  ASDM
 SG_ zipy_serialized_data_174_FL : 448|32@1- (0.1,0) [-102.4|429496729.5] "degree"  ASDM
 SG_ zipy_serialized_data_175_FL : 480|32@1- (0.1,0) [-102.4|429496729.5] "degree"  ASDM

BO_ 315 MB79_DETECTIONS_11_FL: 64 FSRL
 SG_ zipy_serialized_data_176_FL : 0|32@1- (0.1,0) [-102.4|429496729.5] "degree"  ASDM
 SG_ zipy_serialized_data_177_FL : 32|32@1- (0.1,0) [-102.4|429496729.5] "degree"  ASDM
 SG_ zipy_serialized_data_178_FL : 64|32@1- (0.1,0) [-102.4|429496729.5] "degree"  ASDM
 SG_ zipy_serialized_data_179_FL : 96|32@1- (0.1,0) [-102.4|429496729.5] "degree"  ASDM
 SG_ zipy_serialized_data_180_FL : 128|32@1- (0.1,0) [-102.4|429496729.5] "degree"  ASDM
 SG_ zipy_serialized_data_181_FL : 160|32@1- (0.1,0) [-102.4|429496729.5] "degree"  ASDM
 SG_ zipy_serialized_data_182_FL : 192|32@1- (0.1,0) [-102.4|429496729.5] "degree"  ASDM
 SG_ zipy_serialized_data_183_FL : 224|32@1- (0.1,0) [-102.4|429496729.5] "degree"  ASDM
 SG_ zipy_serialized_data_184_FL : 256|32@1- (0.1,0) [-102.4|429496729.5] "degree"  ASDM
 SG_ zipy_serialized_data_185_FL : 288|32@1- (0.1,0) [-102.4|429496729.5] "degree"  ASDM
 SG_ zipy_serialized_data_186_FL : 320|32@1- (0.1,0) [-102.4|429496729.5] "degree"  ASDM
 SG_ zipy_serialized_data_187_FL : 352|32@1- (0.1,0) [-102.4|429496729.5] "degree"  ASDM
 SG_ zipy_serialized_data_188_FL : 384|32@1- (0.1,0) [-102.4|429496729.5] "degree"  ASDM
 SG_ zipy_serialized_data_189_FL : 416|32@1- (0.1,0) [-102.4|429496729.5] "degree"  ASDM
 SG_ zipy_serialized_data_190_FL : 448|32@1- (0.1,0) [-102.4|429496729.5] "degree"  ASDM
 SG_ zipy_serialized_data_191_FL : 480|32@1- (0.1,0) [-102.4|429496729.5] "degree"  ASDM

BO_ 316 MB79_DETECTIONS_12_FL: 64 FSRL
 SG_ zipy_serialized_data_192_FL : 0|32@1- (0.1,0) [-102.4|429496729.5] "degree"  ASDM
 SG_ zipy_serialized_data_193_FL : 32|32@1- (0.1,0) [-102.4|429496729.5] "degree"  ASDM
 SG_ zipy_serialized_data_194_FL : 64|32@1- (0.1,0) [-102.4|429496729.5] "degree"  ASDM
 SG_ zipy_serialized_data_195_FL : 96|32@1- (0.1,0) [-102.4|429496729.5] "degree"  ASDM
 SG_ zipy_serialized_data_196_FL : 128|32@1- (0.1,0) [-102.4|429496729.5] "degree"  ASDM
 SG_ zipy_serialized_data_197_FL : 160|32@1- (0.1,0) [-102.4|429496729.5] "degree"  ASDM
 SG_ zipy_serialized_data_198_FL : 192|32@1- (0.1,0) [-102.4|429496729.5] "degree"  ASDM
 SG_ zipy_serialized_data_199_FL : 224|32@1- (0.1,0) [-102.4|429496729.5] "degree"  ASDM
 SG_ zipy_serialized_data_200_FL : 256|32@1- (0.1,0) [-102.4|429496729.5] "degree"  ASDM
 SG_ zipy_serialized_data_201_FL : 288|32@1- (0.1,0) [-102.4|429496729.5] "degree"  ASDM
 SG_ zipy_serialized_data_202_FL : 320|32@1- (0.1,0) [-102.4|429496729.5] "degree"  ASDM
 SG_ zipy_serialized_data_203_FL : 352|32@1- (0.1,0) [-102.4|429496729.5] "degree"  ASDM
 SG_ zipy_serialized_data_204_FL : 384|32@1- (0.1,0) [-102.4|429496729.5] "degree"  ASDM
 SG_ zipy_serialized_data_205_FL : 416|32@1- (0.1,0) [-102.4|429496729.5] "degree"  ASDM
 SG_ zipy_serialized_data_206_FL : 448|32@1- (0.1,0) [-102.4|429496729.5] "degree"  ASDM
 SG_ zipy_serialized_data_207_FL : 480|32@1- (0.1,0) [-102.4|429496729.5] "degree"  ASDM

BO_ 317 MB79_DETECTIONS_13_FL: 64 FSRL
 SG_ zipy_serialized_data_208_FL : 0|32@1- (0.1,0) [-102.4|429496729.5] "degree"  ASDM
 SG_ zipy_serialized_data_209_FL : 32|32@1- (0.1,0) [-102.4|429496729.5] "degree"  ASDM
 SG_ zipy_serialized_data_210_FL : 64|32@1- (0.1,0) [-102.4|429496729.5] "degree"  ASDM
 SG_ zipy_serialized_data_211_FL : 96|32@1- (0.1,0) [-102.4|429496729.5] "degree"  ASDM
 SG_ zipy_serialized_data_212_FL : 128|32@1- (0.1,0) [-102.4|429496729.5] "degree"  ASDM
 SG_ zipy_serialized_data_213_FL : 160|32@1- (0.1,0) [-102.4|429496729.5] "degree"  ASDM
 SG_ zipy_serialized_data_214_FL : 192|32@1- (0.1,0) [-102.4|429496729.5] "degree"  ASDM
 SG_ zipy_serialized_data_215_FL : 224|32@1- (0.1,0) [-102.4|429496729.5] "degree"  ASDM
 SG_ zipy_serialized_data_216_FL : 256|32@1- (0.1,0) [-102.4|429496729.5] "degree"  ASDM
 SG_ zipy_serialized_data_217_FL : 288|32@1- (0.1,0) [-102.4|429496729.5] "degree"  ASDM
 SG_ zipy_serialized_data_218_FL : 320|32@1- (0.1,0) [-102.4|429496729.5] "degree"  ASDM
 SG_ zipy_serialized_data_219_FL : 352|32@1- (0.1,0) [-102.4|429496729.5] "degree"  ASDM
 SG_ zipy_serialized_data_220_FL : 384|32@1- (0.1,0) [-102.4|429496729.5] "degree"  ASDM
 SG_ zipy_serialized_data_221_FL : 416|32@1- (0.1,0) [-102.4|429496729.5] "degree"  ASDM
 SG_ zipy_serialized_data_222_FL : 448|32@1- (0.1,0) [-102.4|429496729.5] "degree"  ASDM
 SG_ zipy_serialized_data_223_FL : 480|32@1- (0.1,0) [-102.4|429496729.5] "degree"  ASDM

BO_ 318 MB79_DETECTIONS_14_FL: 64 FSRL
 SG_ zipy_serialized_data_224_FL : 0|32@1- (0.1,0) [-102.4|429496729.5] "degree"  ASDM
 SG_ zipy_serialized_data_225_FL : 32|32@1- (0.1,0) [-102.4|429496729.5] "degree"  ASDM
 SG_ zipy_serialized_data_226_FL : 64|32@1- (0.1,0) [-102.4|429496729.5] "degree"  ASDM
 SG_ zipy_serialized_data_227_FL : 96|32@1- (0.1,0) [-102.4|429496729.5] "degree"  ASDM
 SG_ zipy_serialized_data_228_FL : 128|32@1- (0.1,0) [-102.4|429496729.5] "degree"  ASDM
 SG_ zipy_serialized_data_229_FL : 160|32@1- (0.1,0) [-102.4|429496729.5] "degree"  ASDM
 SG_ zipy_serialized_data_230_FL : 192|32@1- (0.1,0) [-102.4|429496729.5] "degree"  ASDM
 SG_ zipy_serialized_data_231_FL : 224|32@1- (0.1,0) [-102.4|429496729.5] "degree"  ASDM
 SG_ zipy_serialized_data_232_FL : 256|32@1- (0.1,0) [-102.4|429496729.5] "degree"  ASDM
 SG_ zipy_serialized_data_233_FL : 288|32@1- (0.1,0) [-102.4|429496729.5] "degree"  ASDM
 SG_ zipy_serialized_data_234_FL : 320|32@1- (0.1,0) [-102.4|429496729.5] "degree"  ASDM
 SG_ zipy_serialized_data_235_FL : 352|32@1- (0.1,0) [-102.4|429496729.5] "degree"  ASDM
 SG_ zipy_serialized_data_236_FL : 384|32@1- (0.1,0) [-102.4|429496729.5] "degree"  ASDM
 SG_ zipy_serialized_data_237_FL : 416|32@1- (0.1,0) [-102.4|429496729.5] "degree"  ASDM
 SG_ zipy_serialized_data_238_FL : 448|32@1- (0.1,0) [-102.4|429496729.5] "degree"  ASDM
 SG_ zipy_serialized_data_239_FL : 480|32@1- (0.1,0) [-102.4|429496729.5] "degree"  ASDM

BO_ 319 MB79_DETECTIONS_15_FL: 64 FSRL
 SG_ zipy_serialized_data_240_FL : 0|32@1- (0.1,0) [-102.4|429496729.5] "degree"  ASDM
 SG_ zipy_serialized_data_241_FL : 32|32@1- (0.1,0) [-102.4|429496729.5] "degree"  ASDM
 SG_ zipy_serialized_data_242_FL : 64|32@1- (0.1,0) [-102.4|429496729.5] "degree"  ASDM
 SG_ zipy_serialized_data_243_FL : 96|32@1- (0.1,0) [-102.4|429496729.5] "degree"  ASDM
 SG_ zipy_serialized_data_244_FL : 128|32@1- (0.1,0) [-102.4|429496729.5] "degree"  ASDM
 SG_ zipy_serialized_data_245_FL : 160|32@1- (0.1,0) [-102.4|429496729.5] "degree"  ASDM
 SG_ zipy_serialized_data_246_FL : 192|32@1- (0.1,0) [-102.4|429496729.5] "degree"  ASDM
 SG_ zipy_serialized_data_247_FL : 224|32@1- (0.1,0) [-102.4|429496729.5] "degree"  ASDM
 SG_ zipy_serialized_data_248_FL : 256|32@1- (0.1,0) [-102.4|429496729.5] "degree"  ASDM
 SG_ zipy_serialized_data_249_FL : 288|32@1- (0.1,0) [-102.4|429496729.5] "degree"  ASDM
 SG_ zipy_serialized_data_250_FL : 320|32@1- (0.1,0) [-102.4|429496729.5] "degree"  ASDM
 SG_ zipy_serialized_data_251_FL : 352|32@1- (0.1,0) [-102.4|429496729.5] "degree"  ASDM
 SG_ zipy_serialized_data_252_FL : 384|32@1- (0.1,0) [-102.4|429496729.5] "degree"  ASDM
 SG_ zipy_serialized_data_253_FL : 416|32@1- (0.1,0) [-102.4|429496729.5] "degree"  ASDM
 SG_ zipy_serialized_data_254_FL : 448|32@1- (0.1,0) [-102.4|429496729.5] "degree"  ASDM
 SG_ zipy_serialized_data_255_FL : 480|32@1- (0.1,0) [-102.4|429496729.5] "degree"  ASDM

BO_ 320 MB79_DETECTIONS_16_FL: 64 FSRL
 SG_ zipy_serialized_data_256_FL : 0|32@1- (0.1,0) [-102.4|429496729.5] "degree"  ASDM
 SG_ zipy_serialized_data_257_FL : 32|32@1- (0.1,0) [-102.4|429496729.5] "degree"  ASDM
 SG_ zipy_serialized_data_258_FL : 64|32@1- (0.1,0) [-102.4|429496729.5] "degree"  ASDM
 SG_ zipy_serialized_data_259_FL : 96|32@1- (0.1,0) [-102.4|429496729.5] "degree"  ASDM
 SG_ zipy_serialized_data_260_FL : 128|32@1- (0.1,0) [-102.4|429496729.5] "degree"  ASDM
 SG_ zipy_serialized_data_261_FL : 160|32@1- (0.1,0) [-102.4|429496729.5] "degree"  ASDM
 SG_ zipy_serialized_data_262_FL : 192|32@1- (0.1,0) [-102.4|429496729.5] "degree"  ASDM
 SG_ zipy_serialized_data_263_FL : 224|32@1- (0.1,0) [-102.4|429496729.5] "degree"  ASDM
 SG_ zipy_serialized_data_264_FL : 256|32@1- (0.1,0) [-102.4|429496729.5] "degree"  ASDM
 SG_ zipy_serialized_data_265_FL : 288|32@1- (0.1,0) [-102.4|429496729.5] "degree"  ASDM
 SG_ zipy_serialized_data_266_FL : 320|32@1- (0.1,0) [-102.4|429496729.5] "degree"  ASDM
 SG_ zipy_serialized_data_267_FL : 352|32@1- (0.1,0) [-102.4|429496729.5] "degree"  ASDM
 SG_ zipy_serialized_data_268_FL : 384|32@1- (0.1,0) [-102.4|429496729.5] "degree"  ASDM
 SG_ zipy_serialized_data_269_FL : 416|32@1- (0.1,0) [-102.4|429496729.5] "degree"  ASDM
 SG_ zipy_serialized_data_270_FL : 448|32@1- (0.1,0) [-102.4|429496729.5] "degree"  ASDM
 SG_ zipy_serialized_data_271_FL : 480|32@1- (0.1,0) [-102.4|429496729.5] "degree"  ASDM

BO_ 321 MB79_DETECTIONS_17_FL: 64 FSRL
 SG_ zipy_serialized_data_272_FL : 0|32@1- (0.1,0) [-102.4|429496729.5] "degree"  ASDM
 SG_ zipy_serialized_data_273_FL : 32|32@1- (0.1,0) [-102.4|429496729.5] "degree"  ASDM
 SG_ zipy_serialized_data_274_FL : 64|32@1- (0.1,0) [-102.4|429496729.5] "degree"  ASDM
 SG_ zipy_serialized_data_275_FL : 96|32@1- (0.1,0) [-102.4|429496729.5] "degree"  ASDM
 SG_ zipy_serialized_data_276_FL : 128|32@1- (0.1,0) [-102.4|429496729.5] "degree"  ASDM
 SG_ zipy_serialized_data_277_FL : 160|32@1- (0.1,0) [-102.4|429496729.5] "degree"  ASDM
 SG_ zipy_serialized_data_278_FL : 192|32@1- (0.1,0) [-102.4|429496729.5] "degree"  ASDM
 SG_ zipy_serialized_data_279_FL : 224|32@1- (0.1,0) [-102.4|429496729.5] "degree"  ASDM
 SG_ zipy_serialized_data_280_FL : 256|32@1- (0.1,0) [-102.4|429496729.5] "degree"  ASDM
 SG_ zipy_serialized_data_281_FL : 288|32@1- (0.1,0) [-102.4|429496729.5] "degree"  ASDM
 SG_ zipy_serialized_data_282_FL : 320|32@1- (0.1,0) [-102.4|429496729.5] "degree"  ASDM
 SG_ zipy_serialized_data_283_FL : 352|32@1- (0.1,0) [-102.4|429496729.5] "degree"  ASDM
 SG_ zipy_serialized_data_284_FL : 384|32@1- (0.1,0) [-102.4|429496729.5] "degree"  ASDM
 SG_ zipy_serialized_data_285_FL : 416|32@1- (0.1,0) [-102.4|429496729.5] "degree"  ASDM
 SG_ zipy_serialized_data_286_FL : 448|32@1- (0.1,0) [-102.4|429496729.5] "degree"  ASDM
 SG_ zipy_serialized_data_287_FL : 480|32@1- (0.1,0) [-102.4|429496729.5] "degree"  ASDM

BO_ 322 MB79_DETECTIONS_18_FL: 64 FSRL
 SG_ zipy_serialized_data_288_FL : 0|32@1- (0.1,0) [-102.4|429496729.5] "degree"  ASDM
 SG_ zipy_serialized_data_289_FL : 32|32@1- (0.1,0) [-102.4|429496729.5] "degree"  ASDM
 SG_ zipy_serialized_data_290_FL : 64|32@1- (0.1,0) [-102.4|429496729.5] "degree"  ASDM
 SG_ zipy_serialized_data_291_FL : 96|32@1- (0.1,0) [-102.4|429496729.5] "degree"  ASDM
 SG_ zipy_serialized_data_292_FL : 128|32@1- (0.1,0) [-102.4|429496729.5] "degree"  ASDM
 SG_ zipy_serialized_data_293_FL : 160|32@1- (0.1,0) [-102.4|429496729.5] "degree"  ASDM
 SG_ zipy_serialized_data_294_FL : 192|32@1- (0.1,0) [-102.4|429496729.5] "degree"  ASDM
 SG_ zipy_serialized_data_295_FL : 224|32@1- (0.1,0) [-102.4|429496729.5] "degree"  ASDM
 SG_ zipy_serialized_data_296_FL : 256|32@1- (0.1,0) [-102.4|429496729.5] "degree"  ASDM
 SG_ zipy_serialized_data_297_FL : 288|32@1- (0.1,0) [-102.4|429496729.5] "degree"  ASDM
 SG_ zipy_serialized_data_298_FL : 320|32@1- (0.1,0) [-102.4|429496729.5] "degree"  ASDM
 SG_ zipy_serialized_data_299_FL : 352|32@1- (0.1,0) [-102.4|429496729.5] "degree"  ASDM
 SG_ zipy_serialized_data_300_FL : 384|32@1- (0.1,0) [-102.4|429496729.5] "degree"  ASDM
 SG_ zipy_serialized_data_301_FL : 416|32@1- (0.1,0) [-102.4|429496729.5] "degree"  ASDM
 SG_ zipy_serialized_data_302_FL : 448|32@1- (0.1,0) [-102.4|429496729.5] "degree"  ASDM
 SG_ zipy_serialized_data_303_FL : 480|32@1- (0.1,0) [-102.4|429496729.5] "degree"  ASDM

BO_ 323 MB79_DETECTIONS_19_FL: 64 FSRL
 SG_ zipy_serialized_data_304_FL : 0|32@1- (0.1,0) [-102.4|429496729.5] "degree"  ASDM
 SG_ zipy_serialized_data_305_FL : 32|32@1- (0.1,0) [-102.4|429496729.5] "degree"  ASDM
 SG_ zipy_serialized_data_306_FL : 64|32@1- (0.1,0) [-102.4|429496729.5] "degree"  ASDM
 SG_ zipy_serialized_data_307_FL : 96|32@1- (0.1,0) [-102.4|429496729.5] "degree"  ASDM
 SG_ zipy_serialized_data_308_FL : 128|32@1- (0.1,0) [-102.4|429496729.5] "degree"  ASDM
 SG_ zipy_serialized_data_309_FL : 160|32@1- (0.1,0) [-102.4|429496729.5] "degree"  ASDM
 SG_ zipy_serialized_data_310_FL : 192|32@1- (0.1,0) [-102.4|429496729.5] "degree"  ASDM
 SG_ zipy_serialized_data_311_FL : 224|32@1- (0.1,0) [-102.4|429496729.5] "degree"  ASDM
 SG_ zipy_serialized_data_312_FL : 256|32@1- (0.1,0) [-102.4|429496729.5] "degree"  ASDM
 SG_ zipy_serialized_data_313_FL : 288|32@1- (0.1,0) [-102.4|429496729.5] "degree"  ASDM
 SG_ zipy_serialized_data_314_FL : 320|32@1- (0.1,0) [-102.4|429496729.5] "degree"  ASDM
 SG_ zipy_serialized_data_315_FL : 352|32@1- (0.1,0) [-102.4|429496729.5] "degree"  ASDM
 SG_ zipy_serialized_data_316_FL : 384|32@1- (0.1,0) [-102.4|429496729.5] "degree"  ASDM
 SG_ zipy_serialized_data_317_FL : 416|32@1- (0.1,0) [-102.4|429496729.5] "degree"  ASDM
 SG_ zipy_serialized_data_318_FL : 448|32@1- (0.1,0) [-102.4|429496729.5] "degree"  ASDM
 SG_ zipy_serialized_data_319_FL : 480|32@1- (0.1,0) [-102.4|429496729.5] "degree"  ASDM

BO_ 324 MB79_DETECTIONS_20_FL: 64 FSRL
 SG_ zipy_serialized_data_320_FL : 0|32@1- (0.1,0) [-102.4|429496729.5] "degree"  ASDM
 SG_ zipy_serialized_data_321_FL : 32|32@1- (0.1,0) [-102.4|429496729.5] "degree"  ASDM
 SG_ zipy_serialized_data_322_FL : 64|32@1- (0.1,0) [-102.4|429496729.5] "degree"  ASDM
 SG_ zipy_serialized_data_323_FL : 96|32@1- (0.1,0) [-102.4|429496729.5] "degree"  ASDM
 SG_ zipy_serialized_data_324_FL : 128|32@1- (0.1,0) [-102.4|429496729.5] "degree"  ASDM
 SG_ zipy_serialized_data_325_FL : 160|32@1- (0.1,0) [-102.4|429496729.5] "degree"  ASDM
 SG_ zipy_serialized_data_326_FL : 192|32@1- (0.1,0) [-102.4|429496729.5] "degree"  ASDM
 SG_ zipy_serialized_data_327_FL : 224|32@1- (0.1,0) [-102.4|429496729.5] "degree"  ASDM
 SG_ zipy_serialized_data_328_FL : 256|32@1- (0.1,0) [-102.4|429496729.5] "degree"  ASDM
 SG_ zipy_serialized_data_329_FL : 288|32@1- (0.1,0) [-102.4|429496729.5] "degree"  ASDM
 SG_ zipy_serialized_data_330_FL : 320|32@1- (0.1,0) [-102.4|429496729.5] "degree"  ASDM
 SG_ zipy_serialized_data_331_FL : 352|32@1- (0.1,0) [-102.4|429496729.5] "degree"  ASDM
 SG_ zipy_serialized_data_332_FL : 384|32@1- (0.1,0) [-102.4|429496729.5] "degree"  ASDM
 SG_ zipy_serialized_data_333_FL : 416|32@1- (0.1,0) [-102.4|429496729.5] "degree"  ASDM
 SG_ zipy_serialized_data_334_FL : 448|32@1- (0.1,0) [-102.4|429496729.5] "degree"  ASDM
 SG_ zipy_serialized_data_335_FL : 480|32@1- (0.1,0) [-102.4|429496729.5] "degree"  ASDM

BO_ 325 MB79_DETECTIONS_21_FL: 64 FSRL
 SG_ zipy_serialized_data_336_FL : 0|32@1- (0.1,0) [-102.4|429496729.5] "degree"  ASDM
 SG_ zipy_serialized_data_337_FL : 32|32@1- (0.1,0) [-102.4|429496729.5] "degree"  ASDM
 SG_ zipy_serialized_data_338_FL : 64|32@1- (0.1,0) [-102.4|429496729.5] "degree"  ASDM
 SG_ zipy_serialized_data_339_FL : 96|32@1- (0.1,0) [-102.4|429496729.5] "degree"  ASDM
 SG_ zipy_serialized_data_340_FL : 128|32@1- (0.1,0) [-102.4|429496729.5] "degree"  ASDM
 SG_ zipy_serialized_data_341_FL : 160|32@1- (0.1,0) [-102.4|429496729.5] "degree"  ASDM
 SG_ zipy_serialized_data_342_FL : 192|32@1- (0.1,0) [-102.4|429496729.5] "degree"  ASDM
 SG_ zipy_serialized_data_343_FL : 224|32@1- (0.1,0) [-102.4|429496729.5] "degree"  ASDM
 SG_ zipy_serialized_data_344_FL : 256|32@1- (0.1,0) [-102.4|429496729.5] "degree"  ASDM
 SG_ zipy_serialized_data_345_FL : 288|32@1- (0.1,0) [-102.4|429496729.5] "degree"  ASDM
 SG_ zipy_serialized_data_346_FL : 320|32@1- (0.1,0) [-102.4|429496729.5] "degree"  ASDM
 SG_ zipy_serialized_data_347_FL : 352|32@1- (0.1,0) [-102.4|429496729.5] "degree"  ASDM
 SG_ zipy_serialized_data_348_FL : 384|32@1- (0.1,0) [-102.4|429496729.5] "degree"  ASDM
 SG_ zipy_serialized_data_349_FL : 416|32@1- (0.1,0) [-102.4|429496729.5] "degree"  ASDM
 SG_ zipy_serialized_data_350_FL : 448|32@1- (0.1,0) [-102.4|429496729.5] "degree"  ASDM
 SG_ zipy_serialized_data_351_FL : 480|32@1- (0.1,0) [-102.4|429496729.5] "degree"  ASDM

BO_ 326 MB79_DETECTIONS_22_FL: 64 FSRL
 SG_ zipy_serialized_data_352_FL : 0|32@1- (0.1,0) [-102.4|429496729.5] "degree"  ASDM
 SG_ zipy_serialized_data_353_FL : 32|32@1- (0.1,0) [-102.4|429496729.5] "degree"  ASDM
 SG_ zipy_serialized_data_354_FL : 64|32@1- (0.1,0) [-102.4|429496729.5] "degree"  ASDM
 SG_ zipy_serialized_data_355_FL : 96|32@1- (0.1,0) [-102.4|429496729.5] "degree"  ASDM
 SG_ zipy_serialized_data_356_FL : 128|32@1- (0.1,0) [-102.4|429496729.5] "degree"  ASDM
 SG_ zipy_serialized_data_357_FL : 160|32@1- (0.1,0) [-102.4|429496729.5] "degree"  ASDM
 SG_ zipy_serialized_data_358_FL : 192|32@1- (0.1,0) [-102.4|429496729.5] "degree"  ASDM
 SG_ zipy_serialized_data_359_FL : 224|32@1- (0.1,0) [-102.4|429496729.5] "degree"  ASDM
 SG_ zipy_serialized_data_360_FL : 256|32@1- (0.1,0) [-102.4|429496729.5] "degree"  ASDM
 SG_ zipy_serialized_data_361_FL : 288|32@1- (0.1,0) [-102.4|429496729.5] "degree"  ASDM
 SG_ zipy_serialized_data_362_FL : 320|32@1- (0.1,0) [-102.4|429496729.5] "degree"  ASDM
 SG_ zipy_serialized_data_363_FL : 352|32@1- (0.1,0) [-102.4|429496729.5] "degree"  ASDM
 SG_ zipy_serialized_data_364_FL : 384|32@1- (0.1,0) [-102.4|429496729.5] "degree"  ASDM
 SG_ zipy_serialized_data_365_FL : 416|32@1- (0.1,0) [-102.4|429496729.5] "degree"  ASDM
 SG_ zipy_serialized_data_366_FL : 448|32@1- (0.1,0) [-102.4|429496729.5] "degree"  ASDM
 SG_ zipy_serialized_data_367_FL : 480|32@1- (0.1,0) [-102.4|429496729.5] "degree"  ASDM

BO_ 327 MB79_DETECTIONS_23_FL: 64 FSRL
 SG_ zipy_serialized_data_368_FL : 0|32@1- (0.1,0) [-102.4|429496729.5] "degree"  ASDM
 SG_ zipy_serialized_data_369_FL : 32|32@1- (0.1,0) [-102.4|429496729.5] "degree"  ASDM
 SG_ zipy_serialized_data_370_FL : 64|32@1- (0.1,0) [-102.4|429496729.5] "degree"  ASDM
 SG_ zipy_serialized_data_371_FL : 96|32@1- (0.1,0) [-102.4|429496729.5] "degree"  ASDM
 SG_ zipy_serialized_data_372_FL : 128|32@1- (0.1,0) [-102.4|429496729.5] "degree"  ASDM
 SG_ zipy_serialized_data_373_FL : 160|32@1- (0.1,0) [-102.4|429496729.5] "degree"  ASDM
 SG_ zipy_serialized_data_374_FL : 192|32@1- (0.1,0) [-102.4|429496729.5] "degree"  ASDM
 SG_ zipy_serialized_data_375_FL : 224|32@1- (0.1,0) [-102.4|429496729.5] "degree"  ASDM
 SG_ zipy_serialized_data_376_FL : 256|32@1- (0.1,0) [-102.4|429496729.5] "degree"  ASDM
 SG_ zipy_serialized_data_377_FL : 288|32@1- (0.1,0) [-102.4|429496729.5] "degree"  ASDM
 SG_ zipy_serialized_data_378_FL : 320|32@1- (0.1,0) [-102.4|429496729.5] "degree"  ASDM
 SG_ zipy_serialized_data_379_FL : 352|32@1- (0.1,0) [-102.4|429496729.5] "degree"  ASDM
 SG_ zipy_serialized_data_380_FL : 384|32@1- (0.1,0) [-102.4|429496729.5] "degree"  ASDM
 SG_ zipy_serialized_data_381_FL : 416|32@1- (0.1,0) [-102.4|429496729.5] "degree"  ASDM
 SG_ zipy_serialized_data_382_FL : 448|32@1- (0.1,0) [-102.4|429496729.5] "degree"  ASDM
 SG_ zipy_serialized_data_383_FL : 480|32@1- (0.1,0) [-102.4|429496729.5] "degree"  ASDM

BO_ 328 MB79_DETECTIONS_24_FL: 64 FSRL
 SG_ zipy_serialized_data_384_FL : 0|32@1- (0.1,0) [-102.4|429496729.5] "degree"  ASDM
 SG_ zipy_serialized_data_385_FL : 32|32@1- (0.1,0) [-102.4|429496729.5] "degree"  ASDM
 SG_ zipy_serialized_data_386_FL : 64|32@1- (0.1,0) [-102.4|429496729.5] "degree"  ASDM
 SG_ zipy_serialized_data_387_FL : 96|32@1- (0.1,0) [-102.4|429496729.5] "degree"  ASDM
 SG_ zipy_serialized_data_388_FL : 128|32@1- (0.1,0) [-102.4|429496729.5] "degree"  ASDM
 SG_ zipy_serialized_data_389_FL : 160|32@1- (0.1,0) [-102.4|429496729.5] "degree"  ASDM
 SG_ zipy_serialized_data_390_FL : 192|32@1- (0.1,0) [-102.4|429496729.5] "degree"  ASDM
 SG_ zipy_serialized_data_391_FL : 224|32@1- (0.1,0) [-102.4|429496729.5] "degree"  ASDM
 SG_ zipy_serialized_data_392_FL : 256|32@1- (0.1,0) [-102.4|429496729.5] "degree"  ASDM
 SG_ zipy_serialized_data_393_FL : 288|32@1- (0.1,0) [-102.4|429496729.5] "degree"  ASDM
 SG_ zipy_serialized_data_394_FL : 320|32@1- (0.1,0) [-102.4|429496729.5] "degree"  ASDM
 SG_ zipy_serialized_data_395_FL : 352|32@1- (0.1,0) [-102.4|429496729.5] "degree"  ASDM
 SG_ zipy_serialized_data_396_FL : 384|32@1- (0.1,0) [-102.4|429496729.5] "degree"  ASDM
 SG_ zipy_serialized_data_397_FL : 416|32@1- (0.1,0) [-102.4|429496729.5] "degree"  ASDM
 SG_ zipy_serialized_data_398_FL : 448|32@1- (0.1,0) [-102.4|429496729.5] "degree"  ASDM
 SG_ zipy_serialized_data_399_FL : 480|32@1- (0.1,0) [-102.4|429496729.5] "degree"  ASDM

BO_ 329 MB79_DETECTIONS_25_FL: 64 FSRL
 SG_ zipy_serialized_data_400_FL : 0|32@1- (0.1,0) [-102.4|429496729.5] "degree"  ASDM
 SG_ zipy_serialized_data_401_FL : 32|32@1- (0.1,0) [-102.4|429496729.5] "degree"  ASDM
 SG_ zipy_serialized_data_402_FL : 64|32@1- (0.1,0) [-102.4|429496729.5] "degree"  ASDM
 SG_ zipy_serialized_data_403_FL : 96|32@1- (0.1,0) [-102.4|429496729.5] "degree"  ASDM
 SG_ zipy_serialized_data_404_FL : 128|32@1- (0.1,0) [-102.4|429496729.5] "degree"  ASDM
 SG_ zipy_serialized_data_405_FL : 160|32@1- (0.1,0) [-102.4|429496729.5] "degree"  ASDM
 SG_ zipy_serialized_data_406_FL : 192|32@1- (0.1,0) [-102.4|429496729.5] "degree"  ASDM
 SG_ zipy_serialized_data_407_FL : 224|32@1- (0.1,0) [-102.4|429496729.5] "degree"  ASDM
 SG_ zipy_serialized_data_408_FL : 256|32@1- (0.1,0) [-102.4|429496729.5] "degree"  ASDM
 SG_ zipy_serialized_data_409_FL : 288|32@1- (0.1,0) [-102.4|429496729.5] "degree"  ASDM
 SG_ zipy_serialized_data_410_FL : 320|32@1- (0.1,0) [-102.4|429496729.5] "degree"  ASDM
 SG_ zipy_serialized_data_411_FL : 352|32@1- (0.1,0) [-102.4|429496729.5] "degree"  ASDM
 SG_ zipy_serialized_data_412_FL : 384|32@1- (0.1,0) [-102.4|429496729.5] "degree"  ASDM
 SG_ zipy_serialized_data_413_FL : 416|32@1- (0.1,0) [-102.4|429496729.5] "degree"  ASDM
 SG_ zipy_serialized_data_414_FL : 448|32@1- (0.1,0) [-102.4|429496729.5] "degree"  ASDM
 SG_ zipy_serialized_data_415_FL : 480|32@1- (0.1,0) [-102.4|429496729.5] "degree"  ASDM

BO_ 330 MB79_DETECTIONS_26_FL: 64 FSRL
 SG_ zipy_serialized_data_416_FL : 0|32@1- (0.1,0) [-102.4|429496729.5] "degree"  ASDM
 SG_ zipy_serialized_data_417_FL : 32|32@1- (0.1,0) [-102.4|429496729.5] "degree"  ASDM
 SG_ zipy_serialized_data_418_FL : 64|32@1- (0.1,0) [-102.4|429496729.5] "degree"  ASDM
 SG_ zipy_serialized_data_419_FL : 96|32@1- (0.1,0) [-102.4|429496729.5] "degree"  ASDM
 SG_ zipy_serialized_data_420_FL : 128|32@1- (0.1,0) [-102.4|429496729.5] "degree"  ASDM
 SG_ zipy_serialized_data_421_FL : 160|32@1- (0.1,0) [-102.4|429496729.5] "degree"  ASDM
 SG_ zipy_serialized_data_422_FL : 192|32@1- (0.1,0) [-102.4|429496729.5] "degree"  ASDM
 SG_ zipy_serialized_data_423_FL : 224|32@1- (0.1,0) [-102.4|429496729.5] "degree"  ASDM
 SG_ zipy_serialized_data_424_FL : 256|32@1- (0.1,0) [-102.4|429496729.5] "degree"  ASDM
 SG_ zipy_serialized_data_425_FL : 288|32@1- (0.1,0) [-102.4|429496729.5] "degree"  ASDM
 SG_ zipy_serialized_data_426_FL : 320|32@1- (0.1,0) [-102.4|429496729.5] "degree"  ASDM
 SG_ zipy_serialized_data_427_FL : 352|32@1- (0.1,0) [-102.4|429496729.5] "degree"  ASDM
 SG_ zipy_serialized_data_428_FL : 384|32@1- (0.1,0) [-102.4|429496729.5] "degree"  ASDM
 SG_ zipy_serialized_data_429_FL : 416|32@1- (0.1,0) [-102.4|429496729.5] "degree"  ASDM
 SG_ zipy_serialized_data_430_FL : 448|32@1- (0.1,0) [-102.4|429496729.5] "degree"  ASDM
 SG_ zipy_serialized_data_431_FL : 480|32@1- (0.1,0) [-102.4|429496729.5] "degree"  ASDM

BO_ 331 MB79_DETECTIONS_27_FL: 64 FSRL
 SG_ zipy_serialized_data_432_FL : 0|32@1- (0.1,0) [-102.4|429496729.5] "degree"  ASDM
 SG_ zipy_serialized_data_433_FL : 32|32@1- (0.1,0) [-102.4|429496729.5] "degree"  ASDM
 SG_ zipy_serialized_data_434_FL : 64|32@1- (0.1,0) [-102.4|429496729.5] "degree"  ASDM
 SG_ zipy_serialized_data_435_FL : 96|32@1- (0.1,0) [-102.4|429496729.5] "degree"  ASDM
 SG_ zipy_serialized_data_436_FL : 128|32@1- (0.1,0) [-102.4|429496729.5] "degree"  ASDM
 SG_ zipy_serialized_data_437_FL : 160|32@1- (0.1,0) [-102.4|429496729.5] "degree"  ASDM
 SG_ zipy_serialized_data_438_FL : 192|32@1- (0.1,0) [-102.4|429496729.5] "degree"  ASDM
 SG_ zipy_serialized_data_439_FL : 224|32@1- (0.1,0) [-102.4|429496729.5] "degree"  ASDM
 SG_ zipy_serialized_data_440_FL : 256|32@1- (0.1,0) [-102.4|429496729.5] "degree"  ASDM
 SG_ zipy_serialized_data_441_FL : 288|32@1- (0.1,0) [-102.4|429496729.5] "degree"  ASDM
 SG_ zipy_serialized_data_442_FL : 320|32@1- (0.1,0) [-102.4|429496729.5] "degree"  ASDM
 SG_ zipy_serialized_data_443_FL : 352|32@1- (0.1,0) [-102.4|429496729.5] "degree"  ASDM
 SG_ zipy_serialized_data_444_FL : 384|32@1- (0.1,0) [-102.4|429496729.5] "degree"  ASDM
 SG_ zipy_serialized_data_445_FL : 416|32@1- (0.1,0) [-102.4|429496729.5] "degree"  ASDM
 SG_ zipy_serialized_data_446_FL : 448|32@1- (0.1,0) [-102.4|429496729.5] "degree"  ASDM
 SG_ zipy_serialized_data_447_FL : 480|32@1- (0.1,0) [-102.4|429496729.5] "degree"  ASDM

BO_ 332 MB79_DETECTIONS_28_FL: 64 FSRL
 SG_ zipy_serialized_data_448_FL : 0|32@1- (0.1,0) [-102.4|429496729.5] "degree"  ASDM
 SG_ zipy_serialized_data_449_FL : 32|32@1- (0.1,0) [-102.4|429496729.5] "degree"  ASDM
 SG_ zipy_serialized_data_450_FL : 64|32@1- (0.1,0) [-102.4|429496729.5] "degree"  ASDM
 SG_ zipy_serialized_data_451_FL : 96|32@1- (0.1,0) [-102.4|429496729.5] "degree"  ASDM
 SG_ zipy_serialized_data_452_FL : 128|32@1- (0.1,0) [-102.4|429496729.5] "degree"  ASDM
 SG_ zipy_serialized_data_453_FL : 160|32@1- (0.1,0) [-102.4|429496729.5] "degree"  ASDM
 SG_ zipy_serialized_data_454_FL : 192|32@1- (0.1,0) [-102.4|429496729.5] "degree"  ASDM
 SG_ zipy_serialized_data_455_FL : 224|32@1- (0.1,0) [-102.4|429496729.5] "degree"  ASDM
 SG_ zipy_serialized_data_456_FL : 256|32@1- (0.1,0) [-102.4|429496729.5] "degree"  ASDM
 SG_ zipy_serialized_data_457_FL : 288|32@1- (0.1,0) [-102.4|429496729.5] "degree"  ASDM
 SG_ zipy_serialized_data_458_FL : 320|32@1- (0.1,0) [-102.4|429496729.5] "degree"  ASDM
 SG_ zipy_serialized_data_459_FL : 352|32@1- (0.1,0) [-102.4|429496729.5] "degree"  ASDM
 SG_ zipy_serialized_data_460_FL : 384|32@1- (0.1,0) [-102.4|429496729.5] "degree"  ASDM
 SG_ zipy_serialized_data_461_FL : 416|32@1- (0.1,0) [-102.4|429496729.5] "degree"  ASDM
 SG_ zipy_serialized_data_462_FL : 448|32@1- (0.1,0) [-102.4|429496729.5] "degree"  ASDM
 SG_ zipy_serialized_data_463_FL : 480|32@1- (0.1,0) [-102.4|429496729.5] "degree"  ASDM

BO_ 333 MB79_DETECTIONS_29_FL: 64 FSRL
 SG_ zipy_serialized_data_464_FL : 0|32@1- (0.1,0) [-102.4|429496729.5] "degree"  ASDM
 SG_ zipy_serialized_data_465_FL : 32|32@1- (0.1,0) [-102.4|429496729.5] "degree"  ASDM
 SG_ zipy_serialized_data_466_FL : 64|32@1- (0.1,0) [-102.4|429496729.5] "degree"  ASDM
 SG_ zipy_serialized_data_467_FL : 96|32@1- (0.1,0) [-102.4|429496729.5] "degree"  ASDM
 SG_ zipy_serialized_data_468_FL : 128|32@1- (0.1,0) [-102.4|429496729.5] "degree"  ASDM
 SG_ zipy_serialized_data_469_FL : 160|32@1- (0.1,0) [-102.4|429496729.5] "degree"  ASDM
 SG_ zipy_serialized_data_470_FL : 192|32@1- (0.1,0) [-102.4|429496729.5] "degree"  ASDM
 SG_ zipy_serialized_data_471_FL : 224|32@1- (0.1,0) [-102.4|429496729.5] "degree"  ASDM
 SG_ zipy_serialized_data_472_FL : 256|32@1- (0.1,0) [-102.4|429496729.5] "degree"  ASDM
 SG_ zipy_serialized_data_473_FL : 288|32@1- (0.1,0) [-102.4|429496729.5] "degree"  ASDM
 SG_ zipy_serialized_data_474_FL : 320|32@1- (0.1,0) [-102.4|429496729.5] "degree"  ASDM
 SG_ zipy_serialized_data_475_FL : 352|32@1- (0.1,0) [-102.4|429496729.5] "degree"  ASDM
 SG_ zipy_serialized_data_476_FL : 384|32@1- (0.1,0) [-102.4|429496729.5] "degree"  ASDM
 SG_ zipy_serialized_data_477_FL : 416|32@1- (0.1,0) [-102.4|429496729.5] "degree"  ASDM
 SG_ zipy_serialized_data_478_FL : 448|32@1- (0.1,0) [-102.4|429496729.5] "degree"  ASDM
 SG_ zipy_serialized_data_479_FL : 480|32@1- (0.1,0) [-102.4|429496729.5] "degree"  ASDM

BO_ 334 MB79_DETECTIONS_30_FL: 64 FSRL
 SG_ zipy_serialized_data_480_FL : 0|32@1- (0.1,0) [-102.4|429496729.5] "degree"  ASDM
 SG_ zipy_serialized_data_481_FL : 32|32@1- (0.1,0) [-102.4|429496729.5] "degree"  ASDM
 SG_ zipy_serialized_data_482_FL : 64|32@1- (0.1,0) [-102.4|429496729.5] "degree"  ASDM
 SG_ zipy_serialized_data_483_FL : 96|32@1- (0.1,0) [-102.4|429496729.5] "degree"  ASDM
 SG_ zipy_serialized_data_484_FL : 128|32@1- (0.1,0) [-102.4|429496729.5] "degree"  ASDM
 SG_ zipy_serialized_data_485_FL : 160|32@1- (0.1,0) [-102.4|429496729.5] "degree"  ASDM
 SG_ zipy_serialized_data_486_FL : 192|32@1- (0.1,0) [-102.4|429496729.5] "degree"  ASDM
 SG_ zipy_serialized_data_487_FL : 224|32@1- (0.1,0) [-102.4|429496729.5] "degree"  ASDM
 SG_ zipy_serialized_data_488_FL : 256|32@1- (0.1,0) [-102.4|429496729.5] "degree"  ASDM
 SG_ zipy_serialized_data_489_FL : 288|32@1- (0.1,0) [-102.4|429496729.5] "degree"  ASDM
 SG_ zipy_serialized_data_490_FL : 320|32@1- (0.1,0) [-102.4|429496729.5] "degree"  ASDM
 SG_ zipy_serialized_data_491_FL : 352|32@1- (0.1,0) [-102.4|429496729.5] "degree"  ASDM
 SG_ zipy_serialized_data_492_FL : 384|32@1- (0.1,0) [-102.4|429496729.5] "degree"  ASDM
 SG_ zipy_serialized_data_493_FL : 416|32@1- (0.1,0) [-102.4|429496729.5] "degree"  ASDM
 SG_ zipy_serialized_data_494_FL : 448|32@1- (0.1,0) [-102.4|429496729.5] "degree"  ASDM
 SG_ zipy_serialized_data_495_FL : 480|32@1- (0.1,0) [-102.4|429496729.5] "degree"  ASDM

BO_ 335 MB79_DETECTIONS_31_FL: 64 FSRL
 SG_ zipy_serialized_data_496_FL : 0|32@1- (0.1,0) [-102.4|429496729.5] "degree"  ASDM
 SG_ zipy_serialized_data_497_FL : 32|32@1- (0.1,0) [-102.4|429496729.5] "degree"  ASDM
 SG_ zipy_serialized_data_498_FL : 64|32@1- (0.1,0) [-102.4|429496729.5] "degree"  ASDM
 SG_ zipy_serialized_data_499_FL : 96|32@1- (0.1,0) [-102.4|429496729.5] "degree"  ASDM
 SG_ zipy_serialized_data_500_FL : 128|32@1- (0.1,0) [-102.4|429496729.5] "degree"  ASDM
 SG_ zipy_serialized_data_501_FL : 160|32@1- (0.1,0) [-102.4|429496729.5] "degree"  ASDM
 SG_ zipy_serialized_data_502_FL : 192|32@1- (0.1,0) [-102.4|429496729.5] "degree"  ASDM
 SG_ zipy_serialized_data_503_FL : 224|32@1- (0.1,0) [-102.4|429496729.5] "degree"  ASDM
 SG_ zipy_serialized_data_504_FL : 256|32@1- (0.1,0) [-102.4|429496729.5] "degree"  ASDM
 SG_ zipy_serialized_data_505_FL : 288|32@1- (0.1,0) [-102.4|429496729.5] "degree"  ASDM
 SG_ zipy_serialized_data_506_FL : 320|32@1- (0.1,0) [-102.4|429496729.5] "degree"  ASDM
 SG_ zipy_serialized_data_507_FL : 352|32@1- (0.1,0) [-102.4|429496729.5] "degree"  ASDM
 SG_ zipy_serialized_data_508_FL : 384|32@1- (0.1,0) [-102.4|429496729.5] "degree"  ASDM
 SG_ zipy_serialized_data_509_FL : 416|32@1- (0.1,0) [-102.4|429496729.5] "degree"  ASDM
 SG_ zipy_serialized_data_510_FL : 448|32@1- (0.1,0) [-102.4|429496729.5] "degree"  ASDM
 SG_ zipy_serialized_data_511_FL : 480|32@1- (0.1,0) [-102.4|429496729.5] "degree"  ASDM

BO_ 336 MB79_DETECTIONS_32_FL: 64 FSRL
 SG_ zipy_serialized_data_512_FL : 0|32@1- (0.1,0) [-102.4|429496729.5] "degree"  ASDM
 SG_ zipy_serialized_data_513_FL : 32|32@1- (0.1,0) [-102.4|429496729.5] "degree"  ASDM
 SG_ zipy_serialized_data_514_FL : 64|32@1- (0.1,0) [-102.4|429496729.5] "degree"  ASDM
 SG_ zipy_serialized_data_515_FL : 96|32@1- (0.1,0) [-102.4|429496729.5] "degree"  ASDM
 SG_ zipy_serialized_data_516_FL : 128|32@1- (0.1,0) [-102.4|429496729.5] "degree"  ASDM
 SG_ zipy_serialized_data_517_FL : 160|32@1- (0.1,0) [-102.4|429496729.5] "degree"  ASDM
 SG_ zipy_serialized_data_518_FL : 192|32@1- (0.1,0) [-102.4|429496729.5] "degree"  ASDM
 SG_ zipy_serialized_data_519_FL : 224|32@1- (0.1,0) [-102.4|429496729.5] "degree"  ASDM
 SG_ zipy_serialized_data_520_FL : 256|32@1- (0.1,0) [-102.4|429496729.5] "degree"  ASDM
 SG_ zipy_serialized_data_521_FL : 288|32@1- (0.1,0) [-102.4|429496729.5] "degree"  ASDM
 SG_ zipy_serialized_data_522_FL : 320|32@1- (0.1,0) [-102.4|429496729.5] "degree"  ASDM
 SG_ zipy_serialized_data_523_FL : 352|32@1- (0.1,0) [-102.4|429496729.5] "degree"  ASDM
 SG_ zipy_serialized_data_524_FL : 384|32@1- (0.1,0) [-102.4|429496729.5] "degree"  ASDM
 SG_ zipy_serialized_data_525_FL : 416|32@1- (0.1,0) [-102.4|429496729.5] "degree"  ASDM
 SG_ zipy_serialized_data_526_FL : 448|32@1- (0.1,0) [-102.4|429496729.5] "degree"  ASDM
 SG_ zipy_serialized_data_527_FL : 480|32@1- (0.1,0) [-102.4|429496729.5] "degree"  ASDM

BO_ 337 MB79_DETECTIONS_33_FL: 64 FSRL
 SG_ zipy_serialized_data_528_FL : 0|32@1- (0.1,0) [-102.4|429496729.5] "degree"  ASDM
 SG_ zipy_serialized_data_529_FL : 32|32@1- (0.1,0) [-102.4|429496729.5] "degree"  ASDM
 SG_ zipy_serialized_data_530_FL : 64|32@1- (0.1,0) [-102.4|429496729.5] "degree"  ASDM
 SG_ zipy_serialized_data_531_FL : 96|32@1- (0.1,0) [-102.4|429496729.5] "degree"  ASDM
 SG_ zipy_serialized_data_532_FL : 128|32@1- (0.1,0) [-102.4|429496729.5] "degree"  ASDM
 SG_ zipy_serialized_data_533_FL : 160|32@1- (0.1,0) [-102.4|429496729.5] "degree"  ASDM
 SG_ zipy_serialized_data_534_FL : 192|32@1- (0.1,0) [-102.4|429496729.5] "degree"  ASDM
 SG_ zipy_serialized_data_535_FL : 224|32@1- (0.1,0) [-102.4|429496729.5] "degree"  ASDM
 SG_ zipy_serialized_data_536_FL : 256|32@1- (0.1,0) [-102.4|429496729.5] "degree"  ASDM
 SG_ zipy_serialized_data_537_FL : 288|32@1- (0.1,0) [-102.4|429496729.5] "degree"  ASDM
 SG_ zipy_serialized_data_538_FL : 320|32@1- (0.1,0) [-102.4|429496729.5] "degree"  ASDM
 SG_ zipy_serialized_data_539_FL : 352|32@1- (0.1,0) [-102.4|429496729.5] "degree"  ASDM
 SG_ zipy_serialized_data_540_FL : 384|32@1- (0.1,0) [-102.4|429496729.5] "degree"  ASDM
 SG_ zipy_serialized_data_541_FL : 416|32@1- (0.1,0) [-102.4|429496729.5] "degree"  ASDM
 SG_ zipy_serialized_data_542_FL : 448|32@1- (0.1,0) [-102.4|429496729.5] "degree"  ASDM
 SG_ zipy_serialized_data_543_FL : 480|32@1- (0.1,0) [-102.4|429496729.5] "degree"  ASDM

BO_ 338 MB79_DETECTIONS_34_FL: 64 FSRL
 SG_ zipy_serialized_data_544_FL : 0|32@1- (0.1,0) [-102.4|429496729.5] "degree"  ASDM
 SG_ zipy_serialized_data_545_FL : 32|32@1- (0.1,0) [-102.4|429496729.5] "degree"  ASDM
 SG_ zipy_serialized_data_546_FL : 64|32@1- (0.1,0) [-102.4|429496729.5] "degree"  ASDM
 SG_ zipy_serialized_data_547_FL : 96|32@1- (0.1,0) [-102.4|429496729.5] "degree"  ASDM
 SG_ zipy_serialized_data_548_FL : 128|32@1- (0.1,0) [-102.4|429496729.5] "degree"  ASDM
 SG_ zipy_serialized_data_549_FL : 160|32@1- (0.1,0) [-102.4|429496729.5] "degree"  ASDM
 SG_ zipy_serialized_data_550_FL : 192|32@1- (0.1,0) [-102.4|429496729.5] "degree"  ASDM
 SG_ zipy_serialized_data_551_FL : 224|32@1- (0.1,0) [-102.4|429496729.5] "degree"  ASDM
 SG_ zipy_serialized_data_552_FL : 256|32@1- (0.1,0) [-102.4|429496729.5] "degree"  ASDM
 SG_ zipy_serialized_data_553_FL : 288|32@1- (0.1,0) [-102.4|429496729.5] "degree"  ASDM
 SG_ zipy_serialized_data_554_FL : 320|32@1- (0.1,0) [-102.4|429496729.5] "degree"  ASDM
 SG_ zipy_serialized_data_555_FL : 352|32@1- (0.1,0) [-102.4|429496729.5] "degree"  ASDM
 SG_ zipy_serialized_data_556_FL : 384|32@1- (0.1,0) [-102.4|429496729.5] "degree"  ASDM
 SG_ zipy_serialized_data_557_FL : 416|32@1- (0.1,0) [-102.4|429496729.5] "degree"  ASDM
 SG_ zipy_serialized_data_558_FL : 448|32@1- (0.1,0) [-102.4|429496729.5] "degree"  ASDM
 SG_ zipy_serialized_data_559_FL : 480|32@1- (0.1,0) [-102.4|429496729.5] "degree"  ASDM

BO_ 339 MB79_DETECTIONS_35_FL: 64 FSRL
 SG_ zipy_serialized_data_560_FL : 0|32@1- (0.1,0) [-102.4|429496729.5] "degree"  ASDM
 SG_ zipy_serialized_data_561_FL : 32|32@1- (0.1,0) [-102.4|429496729.5] "degree"  ASDM
 SG_ zipy_serialized_data_562_FL : 64|32@1- (0.1,0) [-102.4|429496729.5] "degree"  ASDM
 SG_ zipy_serialized_data_563_FL : 96|32@1- (0.1,0) [-102.4|429496729.5] "degree"  ASDM
 SG_ zipy_serialized_data_564_FL : 128|32@1- (0.1,0) [-102.4|429496729.5] "degree"  ASDM
 SG_ zipy_serialized_data_565_FL : 160|32@1- (0.1,0) [-102.4|429496729.5] "degree"  ASDM
 SG_ zipy_serialized_data_566_FL : 192|32@1- (0.1,0) [-102.4|429496729.5] "degree"  ASDM
 SG_ zipy_serialized_data_567_FL : 224|32@1- (0.1,0) [-102.4|429496729.5] "degree"  ASDM
 SG_ zipy_serialized_data_568_FL : 256|32@1- (0.1,0) [-102.4|429496729.5] "degree"  ASDM
 SG_ zipy_serialized_data_569_FL : 288|32@1- (0.1,0) [-102.4|429496729.5] "degree"  ASDM
 SG_ zipy_serialized_data_570_FL : 320|32@1- (0.1,0) [-102.4|429496729.5] "degree"  ASDM
 SG_ zipy_serialized_data_571_FL : 352|32@1- (0.1,0) [-102.4|429496729.5] "degree"  ASDM
 SG_ zipy_serialized_data_572_FL : 384|32@1- (0.1,0) [-102.4|429496729.5] "degree"  ASDM
 SG_ zipy_serialized_data_573_FL : 416|32@1- (0.1,0) [-102.4|429496729.5] "degree"  ASDM
 SG_ zipy_serialized_data_574_FL : 448|32@1- (0.1,0) [-102.4|429496729.5] "degree"  ASDM
 SG_ zipy_serialized_data_575_FL : 480|32@1- (0.1,0) [-102.4|429496729.5] "degree"  ASDM

BO_ 340 MB79_DETECTIONS_36_FL: 64 FSRL
 SG_ zipy_serialized_data_576_FL : 0|32@1- (0.1,0) [-102.4|429496729.5] "degree"  ASDM
 SG_ zipy_serialized_data_577_FL : 32|32@1- (0.1,0) [-102.4|429496729.5] "degree"  ASDM
 SG_ zipy_serialized_data_578_FL : 64|32@1- (0.1,0) [-102.4|429496729.5] "degree"  ASDM
 SG_ zipy_serialized_data_579_FL : 96|32@1- (0.1,0) [-102.4|429496729.5] "degree"  ASDM
 SG_ zipy_serialized_data_580_FL : 128|32@1- (0.1,0) [-102.4|429496729.5] "degree"  ASDM
 SG_ zipy_serialized_data_581_FL : 160|32@1- (0.1,0) [-102.4|429496729.5] "degree"  ASDM
 SG_ zipy_serialized_data_582_FL : 192|32@1- (0.1,0) [-102.4|429496729.5] "degree"  ASDM
 SG_ zipy_serialized_data_583_FL : 224|32@1- (0.1,0) [-102.4|429496729.5] "degree"  ASDM
 SG_ zipy_serialized_data_584_FL : 256|32@1- (0.1,0) [-102.4|429496729.5] "degree"  ASDM
 SG_ zipy_serialized_data_585_FL : 288|32@1- (0.1,0) [-102.4|429496729.5] "degree"  ASDM
 SG_ zipy_serialized_data_586_FL : 320|32@1- (0.1,0) [-102.4|429496729.5] "degree"  ASDM
 SG_ zipy_serialized_data_587_FL : 352|32@1- (0.1,0) [-102.4|429496729.5] "degree"  ASDM
 SG_ zipy_serialized_data_588_FL : 384|32@1- (0.1,0) [-102.4|429496729.5] "degree"  ASDM
 SG_ zipy_serialized_data_589_FL : 416|32@1- (0.1,0) [-102.4|429496729.5] "degree"  ASDM
 SG_ zipy_serialized_data_590_FL : 448|32@1- (0.1,0) [-102.4|429496729.5] "degree"  ASDM
 SG_ zipy_serialized_data_591_FL : 480|32@1- (0.1,0) [-102.4|429496729.5] "degree"  ASDM

BO_ 341 MB79_DETECTIONS_37_FL: 64 FSRL
 SG_ zipy_serialized_data_592_FL : 0|32@1- (0.1,0) [-102.4|429496729.5] "degree"  ASDM
 SG_ zipy_serialized_data_593_FL : 32|32@1- (0.1,0) [-102.4|429496729.5] "degree"  ASDM
 SG_ zipy_serialized_data_594_FL : 64|32@1- (0.1,0) [-102.4|429496729.5] "degree"  ASDM
 SG_ zipy_serialized_data_595_FL : 96|32@1- (0.1,0) [-102.4|429496729.5] "degree"  ASDM
 SG_ zipy_serialized_data_596_FL : 128|32@1- (0.1,0) [-102.4|429496729.5] "degree"  ASDM
 SG_ zipy_serialized_data_597_FL : 160|32@1- (0.1,0) [-102.4|429496729.5] "degree"  ASDM
 SG_ zipy_serialized_data_598_FL : 192|32@1- (0.1,0) [-102.4|429496729.5] "degree"  ASDM
 SG_ zipy_serialized_data_599_FL : 224|32@1- (0.1,0) [-102.4|429496729.5] "degree"  ASDM
 SG_ zipy_serialized_data_600_FL : 256|32@1- (0.1,0) [-102.4|429496729.5] "degree"  ASDM
 SG_ zipy_serialized_data_601_FL : 288|32@1- (0.1,0) [-102.4|429496729.5] "degree"  ASDM
 SG_ zipy_serialized_data_602_FL : 320|32@1- (0.1,0) [-102.4|429496729.5] "degree"  ASDM
 SG_ zipy_serialized_data_603_FL : 352|32@1- (0.1,0) [-102.4|429496729.5] "degree"  ASDM
 SG_ zipy_serialized_data_604_FL : 384|32@1- (0.1,0) [-102.4|429496729.5] "degree"  ASDM
 SG_ zipy_serialized_data_605_FL : 416|32@1- (0.1,0) [-102.4|429496729.5] "degree"  ASDM
 SG_ zipy_serialized_data_606_FL : 448|32@1- (0.1,0) [-102.4|429496729.5] "degree"  ASDM
 SG_ zipy_serialized_data_607_FL : 480|32@1- (0.1,0) [-102.4|429496729.5] "degree"  ASDM

BO_ 342 MB79_DETECTIONS_38_FL: 64 FSRL
 SG_ zipy_serialized_data_608_FL : 0|32@1- (0.1,0) [-102.4|429496729.5] "degree"  ASDM
 SG_ zipy_serialized_data_609_FL : 32|32@1- (0.1,0) [-102.4|429496729.5] "degree"  ASDM
 SG_ zipy_serialized_data_610_FL : 64|32@1- (0.1,0) [-102.4|429496729.5] "degree"  ASDM
 SG_ zipy_serialized_data_611_FL : 96|32@1- (0.1,0) [-102.4|429496729.5] "degree"  ASDM
 SG_ zipy_serialized_data_612_FL : 128|32@1- (0.1,0) [-102.4|429496729.5] "degree"  ASDM
 SG_ zipy_serialized_data_613_FL : 160|32@1- (0.1,0) [-102.4|429496729.5] "degree"  ASDM
 SG_ zipy_serialized_data_614_FL : 192|32@1- (0.1,0) [-102.4|429496729.5] "degree"  ASDM
 SG_ zipy_serialized_data_615_FL : 224|32@1- (0.1,0) [-102.4|429496729.5] "degree"  ASDM
 SG_ zipy_serialized_data_616_FL : 256|32@1- (0.1,0) [-102.4|429496729.5] "degree"  ASDM
 SG_ zipy_serialized_data_617_FL : 288|32@1- (0.1,0) [-102.4|429496729.5] "degree"  ASDM
 SG_ zipy_serialized_data_618_FL : 320|32@1- (0.1,0) [-102.4|429496729.5] "degree"  ASDM
 SG_ zipy_serialized_data_619_FL : 352|32@1- (0.1,0) [-102.4|429496729.5] "degree"  ASDM
 SG_ zipy_serialized_data_620_FL : 384|32@1- (0.1,0) [-102.4|429496729.5] "degree"  ASDM
 SG_ zipy_serialized_data_621_FL : 416|32@1- (0.1,0) [-102.4|429496729.5] "degree"  ASDM
 SG_ zipy_serialized_data_622_FL : 448|32@1- (0.1,0) [-102.4|429496729.5] "degree"  ASDM
 SG_ zipy_serialized_data_623_FL : 480|32@1- (0.1,0) [-102.4|429496729.5] "degree"  ASDM

BO_ 343 MB79_DETECTIONS_39_FL: 64 FSRL
 SG_ zipy_serialized_data_624_FL : 0|32@1- (0.1,0) [-102.4|429496729.5] "degree"  ASDM
 SG_ zipy_serialized_data_625_FL : 32|32@1- (0.1,0) [-102.4|429496729.5] "degree"  ASDM
 SG_ zipy_serialized_data_626_FL : 64|32@1- (0.1,0) [-102.4|429496729.5] "degree"  ASDM
 SG_ zipy_serialized_data_627_FL : 96|32@1- (0.1,0) [-102.4|429496729.5] "degree"  ASDM
 SG_ zipy_serialized_data_628_FL : 128|32@1- (0.1,0) [-102.4|429496729.5] "degree"  ASDM
 SG_ zipy_serialized_data_629_FL : 160|32@1- (0.1,0) [-102.4|429496729.5] "degree"  ASDM
 SG_ zipy_serialized_data_630_FL : 192|32@1- (0.1,0) [-102.4|429496729.5] "degree"  ASDM
 SG_ zipy_serialized_data_631_FL : 224|32@1- (0.1,0) [-102.4|429496729.5] "degree"  ASDM
 SG_ zipy_serialized_data_632_FL : 256|32@1- (0.1,0) [-102.4|429496729.5] "degree"  ASDM
 SG_ zipy_serialized_data_633_FL : 288|32@1- (0.1,0) [-102.4|429496729.5] "degree"  ASDM
 SG_ zipy_serialized_data_634_FL : 320|32@1- (0.1,0) [-102.4|429496729.5] "degree"  ASDM
 SG_ zipy_serialized_data_635_FL : 352|32@1- (0.1,0) [-102.4|429496729.5] "degree"  ASDM
 SG_ zipy_serialized_data_636_FL : 384|32@1- (0.1,0) [-102.4|429496729.5] "degree"  ASDM
 SG_ zipy_serialized_data_637_FL : 416|32@1- (0.1,0) [-102.4|429496729.5] "degree"  ASDM
 SG_ zipy_serialized_data_638_FL : 448|32@1- (0.1,0) [-102.4|429496729.5] "degree"  ASDM
 SG_ zipy_serialized_data_639_FL : 480|32@1- (0.1,0) [-102.4|429496729.5] "degree"  ASDM

BO_ 344 MB79_DETECTIONS_40_FL: 64 FSRL
 SG_ zipy_serialized_data_640_FL : 0|32@1- (0.1,0) [-102.4|429496729.5] "degree"  ASDM
 SG_ zipy_serialized_data_641_FL : 32|32@1- (0.1,0) [-102.4|429496729.5] "degree"  ASDM
 SG_ zipy_serialized_data_642_FL : 64|32@1- (0.1,0) [-102.4|429496729.5] "degree"  ASDM
 SG_ zipy_serialized_data_643_FL : 96|32@1- (0.1,0) [-102.4|429496729.5] "degree"  ASDM
 SG_ zipy_serialized_data_644_FL : 128|32@1- (0.1,0) [-102.4|429496729.5] "degree"  ASDM
 SG_ zipy_serialized_data_645_FL : 160|32@1- (0.1,0) [-102.4|429496729.5] "degree"  ASDM
 SG_ zipy_serialized_data_646_FL : 192|32@1- (0.1,0) [-102.4|429496729.5] "degree"  ASDM
 SG_ zipy_serialized_data_647_FL : 224|32@1- (0.1,0) [-102.4|429496729.5] "degree"  ASDM
 SG_ zipy_serialized_data_648_FL : 256|32@1- (0.1,0) [-102.4|429496729.5] "degree"  ASDM
 SG_ zipy_serialized_data_649_FL : 288|32@1- (0.1,0) [-102.4|429496729.5] "degree"  ASDM
 SG_ zipy_serialized_data_650_FL : 320|32@1- (0.1,0) [-102.4|429496729.5] "degree"  ASDM
 SG_ zipy_serialized_data_651_FL : 352|32@1- (0.1,0) [-102.4|429496729.5] "degree"  ASDM
 SG_ zipy_serialized_data_652_FL : 384|32@1- (0.1,0) [-102.4|429496729.5] "degree"  ASDM
 SG_ zipy_serialized_data_653_FL : 416|32@1- (0.1,0) [-102.4|429496729.5] "degree"  ASDM
 SG_ zipy_serialized_data_654_FL : 448|32@1- (0.1,0) [-102.4|429496729.5] "degree"  ASDM
 SG_ zipy_serialized_data_655_FL : 480|32@1- (0.1,0) [-102.4|429496729.5] "degree"  ASDM

BO_ 345 MB79_DETECTIONS_41_FL: 64 FSRL
 SG_ zipy_serialized_data_656_FL : 0|32@1- (0.1,0) [-102.4|429496729.5] "degree"  ASDM
 SG_ zipy_serialized_data_657_FL : 32|32@1- (0.1,0) [-102.4|429496729.5] "degree"  ASDM
 SG_ zipy_serialized_data_658_FL : 64|32@1- (0.1,0) [-102.4|429496729.5] "degree"  ASDM
 SG_ zipy_serialized_data_659_FL : 96|32@1- (0.1,0) [-102.4|429496729.5] "degree"  ASDM
 SG_ zipy_serialized_data_660_FL : 128|32@1- (0.1,0) [-102.4|429496729.5] "degree"  ASDM
 SG_ zipy_serialized_data_661_FL : 160|32@1- (0.1,0) [-102.4|429496729.5] "degree"  ASDM
 SG_ zipy_serialized_data_662_FL : 192|32@1- (0.1,0) [-102.4|429496729.5] "degree"  ASDM
 SG_ zipy_serialized_data_663_FL : 224|32@1- (0.1,0) [-102.4|429496729.5] "degree"  ASDM
 SG_ zipy_serialized_data_664_FL : 256|32@1- (0.1,0) [-102.4|429496729.5] "degree"  ASDM
 SG_ zipy_serialized_data_665_FL : 288|32@1- (0.1,0) [-102.4|429496729.5] "degree"  ASDM
 SG_ zipy_serialized_data_666_FL : 320|32@1- (0.1,0) [-102.4|429496729.5] "degree"  ASDM
 SG_ zipy_serialized_data_667_FL : 352|32@1- (0.1,0) [-102.4|429496729.5] "degree"  ASDM
 SG_ zipy_serialized_data_668_FL : 384|32@1- (0.1,0) [-102.4|429496729.5] "degree"  ASDM
 SG_ zipy_serialized_data_669_FL : 416|32@1- (0.1,0) [-102.4|429496729.5] "degree"  ASDM
 SG_ zipy_serialized_data_670_FL : 448|32@1- (0.1,0) [-102.4|429496729.5] "degree"  ASDM
 SG_ zipy_serialized_data_671_FL : 480|32@1- (0.1,0) [-102.4|429496729.5] "degree"  ASDM

BO_ 346 MB79_DETECTIONS_42_FL: 64 FSRL
 SG_ zipy_serialized_data_672_FL : 0|32@1- (0.1,0) [-102.4|429496729.5] "degree"  ASDM
 SG_ zipy_serialized_data_673_FL : 32|32@1- (0.1,0) [-102.4|429496729.5] "degree"  ASDM
 SG_ zipy_serialized_data_674_FL : 64|32@1- (0.1,0) [-102.4|429496729.5] "degree"  ASDM
 SG_ zipy_serialized_data_675_FL : 96|32@1- (0.1,0) [-102.4|429496729.5] "degree"  ASDM
 SG_ zipy_serialized_data_676_FL : 128|32@1- (0.1,0) [-102.4|429496729.5] "degree"  ASDM
 SG_ zipy_serialized_data_677_FL : 160|32@1- (0.1,0) [-102.4|429496729.5] "degree"  ASDM
 SG_ zipy_serialized_data_678_FL : 192|32@1- (0.1,0) [-102.4|429496729.5] "degree"  ASDM
 SG_ zipy_serialized_data_679_FL : 224|32@1- (0.1,0) [-102.4|429496729.5] "degree"  ASDM
 SG_ zipy_serialized_data_680_FL : 256|32@1- (0.1,0) [-102.4|429496729.5] "degree"  ASDM
 SG_ zipy_serialized_data_681_FL : 288|32@1- (0.1,0) [-102.4|429496729.5] "degree"  ASDM
 SG_ zipy_serialized_data_682_FL : 320|32@1- (0.1,0) [-102.4|429496729.5] "degree"  ASDM
 SG_ zipy_serialized_data_683_FL : 352|32@1- (0.1,0) [-102.4|429496729.5] "degree"  ASDM
 SG_ zipy_serialized_data_684_FL : 384|32@1- (0.1,0) [-102.4|429496729.5] "degree"  ASDM
 SG_ zipy_serialized_data_685_FL : 416|32@1- (0.1,0) [-102.4|429496729.5] "degree"  ASDM
 SG_ zipy_serialized_data_686_FL : 448|32@1- (0.1,0) [-102.4|429496729.5] "degree"  ASDM
 SG_ zipy_serialized_data_687_FL : 480|32@1- (0.1,0) [-102.4|429496729.5] "degree"  ASDM

BO_ 347 MB79_DETECTIONS_43_FL: 64 FSRL
 SG_ zipy_serialized_data_688_FL : 0|32@1- (0.1,0) [-102.4|429496729.5] "degree"  ASDM
 SG_ zipy_serialized_data_689_FL : 32|32@1- (0.1,0) [-102.4|429496729.5] "degree"  ASDM
 SG_ zipy_serialized_data_690_FL : 64|32@1- (0.1,0) [-102.4|429496729.5] "degree"  ASDM
 SG_ zipy_serialized_data_691_FL : 96|32@1- (0.1,0) [-102.4|429496729.5] "degree"  ASDM
 SG_ zipy_serialized_data_692_FL : 128|32@1- (0.1,0) [-102.4|429496729.5] "degree"  ASDM
 SG_ zipy_serialized_data_693_FL : 160|32@1- (0.1,0) [-102.4|429496729.5] "degree"  ASDM
 SG_ zipy_serialized_data_694_FL : 192|32@1- (0.1,0) [-102.4|429496729.5] "degree"  ASDM
 SG_ zipy_serialized_data_695_FL : 224|32@1- (0.1,0) [-102.4|429496729.5] "degree"  ASDM
 SG_ zipy_serialized_data_696_FL : 256|32@1- (0.1,0) [-102.4|429496729.5] "degree"  ASDM
 SG_ zipy_serialized_data_697_FL : 288|32@1- (0.1,0) [-102.4|429496729.5] "degree"  ASDM
 SG_ zipy_serialized_data_698_FL : 320|32@1- (0.1,0) [-102.4|429496729.5] "degree"  ASDM
 SG_ zipy_serialized_data_699_FL : 352|32@1- (0.1,0) [-102.4|429496729.5] "degree"  ASDM
 SG_ zipy_serialized_data_700_FL : 384|32@1- (0.1,0) [-102.4|429496729.5] "degree"  ASDM
 SG_ zipy_serialized_data_701_FL : 416|32@1- (0.1,0) [-102.4|429496729.5] "degree"  ASDM
 SG_ zipy_serialized_data_702_FL : 448|32@1- (0.1,0) [-102.4|429496729.5] "degree"  ASDM
 SG_ zipy_serialized_data_703_FL : 480|32@1- (0.1,0) [-102.4|429496729.5] "degree"  ASDM

BO_ 348 MB79_DETECTIONS_44_FL: 64 FSRL
 SG_ zipy_serialized_data_704_FL : 0|32@1- (0.1,0) [-102.4|429496729.5] "degree"  ASDM
 SG_ zipy_serialized_data_705_FL : 32|32@1- (0.1,0) [-102.4|429496729.5] "degree"  ASDM
 SG_ zipy_serialized_data_706_FL : 64|32@1- (0.1,0) [-102.4|429496729.5] "degree"  ASDM
 SG_ zipy_serialized_data_707_FL : 96|32@1- (0.1,0) [-102.4|429496729.5] "degree"  ASDM
 SG_ zipy_serialized_data_708_FL : 128|32@1- (0.1,0) [-102.4|429496729.5] "degree"  ASDM
 SG_ zipy_serialized_data_709_FL : 160|32@1- (0.1,0) [-102.4|429496729.5] "degree"  ASDM
 SG_ zipy_serialized_data_710_FL : 192|32@1- (0.1,0) [-102.4|429496729.5] "degree"  ASDM
 SG_ zipy_serialized_data_711_FL : 224|32@1- (0.1,0) [-102.4|429496729.5] "degree"  ASDM
 SG_ zipy_serialized_data_712_FL : 256|32@1- (0.1,0) [-102.4|429496729.5] "degree"  ASDM
 SG_ zipy_serialized_data_713_FL : 288|32@1- (0.1,0) [-102.4|429496729.5] "degree"  ASDM
 SG_ zipy_serialized_data_714_FL : 320|32@1- (0.1,0) [-102.4|429496729.5] "degree"  ASDM
 SG_ zipy_serialized_data_715_FL : 352|32@1- (0.1,0) [-102.4|429496729.5] "degree"  ASDM
 SG_ zipy_serialized_data_716_FL : 384|32@1- (0.1,0) [-102.4|429496729.5] "degree"  ASDM
 SG_ zipy_serialized_data_717_FL : 416|32@1- (0.1,0) [-102.4|429496729.5] "degree"  ASDM
 SG_ zipy_serialized_data_718_FL : 448|32@1- (0.1,0) [-102.4|429496729.5] "degree"  ASDM
 SG_ zipy_serialized_data_719_FL : 480|32@1- (0.1,0) [-102.4|429496729.5] "degree"  ASDM

BO_ 349 MB79_DETECTIONS_45_FL: 64 FSRL
 SG_ zipy_serialized_data_720_FL : 0|32@1- (0.1,0) [-102.4|429496729.5] "degree"  ASDM
 SG_ zipy_serialized_data_721_FL : 32|32@1- (0.1,0) [-102.4|429496729.5] "degree"  ASDM
 SG_ zipy_serialized_data_722_FL : 64|32@1- (0.1,0) [-102.4|429496729.5] "degree"  ASDM
 SG_ zipy_serialized_data_723_FL : 96|32@1- (0.1,0) [-102.4|429496729.5] "degree"  ASDM
 SG_ zipy_serialized_data_724_FL : 128|32@1- (0.1,0) [-102.4|429496729.5] "degree"  ASDM
 SG_ zipy_serialized_data_725_FL : 160|32@1- (0.1,0) [-102.4|429496729.5] "degree"  ASDM
 SG_ zipy_serialized_data_726_FL : 192|32@1- (0.1,0) [-102.4|429496729.5] "degree"  ASDM
 SG_ zipy_serialized_data_727_FL : 224|32@1- (0.1,0) [-102.4|429496729.5] "degree"  ASDM
 SG_ zipy_serialized_data_728_FL : 256|32@1- (0.1,0) [-102.4|429496729.5] "degree"  ASDM
 SG_ zipy_serialized_data_729_FL : 288|32@1- (0.1,0) [-102.4|429496729.5] "degree"  ASDM
 SG_ zipy_serialized_data_730_FL : 320|32@1- (0.1,0) [-102.4|429496729.5] "degree"  ASDM
 SG_ zipy_serialized_data_731_FL : 352|32@1- (0.1,0) [-102.4|429496729.5] "degree"  ASDM
 SG_ zipy_serialized_data_732_FL : 384|32@1- (0.1,0) [-102.4|429496729.5] "degree"  ASDM
 SG_ zipy_serialized_data_733_FL : 416|32@1- (0.1,0) [-102.4|429496729.5] "degree"  ASDM
 SG_ zipy_serialized_data_734_FL : 448|32@1- (0.1,0) [-102.4|429496729.5] "degree"  ASDM
 SG_ zipy_serialized_data_735_FL : 480|32@1- (0.1,0) [-102.4|429496729.5] "degree"  ASDM

BO_ 350 MB79_DETECTIONS_46_FL: 64 FSRL
 SG_ zipy_serialized_data_736_FL : 0|32@1- (0.1,0) [-102.4|429496729.5] "degree"  ASDM
 SG_ zipy_serialized_data_737_FL : 32|32@1- (0.1,0) [-102.4|429496729.5] "degree"  ASDM
 SG_ zipy_serialized_data_738_FL : 64|32@1- (0.1,0) [-102.4|429496729.5] "degree"  ASDM
 SG_ zipy_serialized_data_739_FL : 96|32@1- (0.1,0) [-102.4|429496729.5] "degree"  ASDM
 SG_ zipy_serialized_data_740_FL : 128|32@1- (0.1,0) [-102.4|429496729.5] "degree"  ASDM
 SG_ zipy_serialized_data_741_FL : 160|32@1- (0.1,0) [-102.4|429496729.5] "degree"  ASDM
 SG_ zipy_serialized_data_742_FL : 192|32@1- (0.1,0) [-102.4|429496729.5] "degree"  ASDM
 SG_ zipy_serialized_data_743_FL : 224|32@1- (0.1,0) [-102.4|429496729.5] "degree"  ASDM
 SG_ zipy_serialized_data_744_FL : 256|32@1- (0.1,0) [-102.4|429496729.5] "degree"  ASDM
 SG_ zipy_serialized_data_745_FL : 288|32@1- (0.1,0) [-102.4|429496729.5] "degree"  ASDM
 SG_ zipy_serialized_data_746_FL : 320|32@1- (0.1,0) [-102.4|429496729.5] "degree"  ASDM
 SG_ zipy_serialized_data_747_FL : 352|32@1- (0.1,0) [-102.4|429496729.5] "degree"  ASDM
 SG_ zipy_serialized_data_748_FL : 384|32@1- (0.1,0) [-102.4|429496729.5] "degree"  ASDM
 SG_ zipy_serialized_data_749_FL : 416|32@1- (0.1,0) [-102.4|429496729.5] "degree"  ASDM
 SG_ zipy_serialized_data_750_FL : 448|32@1- (0.1,0) [-102.4|429496729.5] "degree"  ASDM
 SG_ zipy_serialized_data_751_FL : 480|32@1- (0.1,0) [-102.4|429496729.5] "degree"  ASDM

BO_ 351 MB79_DETECTIONS_47_FL: 64 FSRL
 SG_ zipy_serialized_data_752_FL : 0|32@1- (0.1,0) [-102.4|429496729.5] "degree"  ASDM
 SG_ zipy_serialized_data_753_FL : 32|32@1- (0.1,0) [-102.4|429496729.5] "degree"  ASDM
 SG_ zipy_serialized_data_754_FL : 64|32@1- (0.1,0) [-102.4|429496729.5] "degree"  ASDM
 SG_ zipy_serialized_data_755_FL : 96|32@1- (0.1,0) [-102.4|429496729.5] "degree"  ASDM
 SG_ zipy_serialized_data_756_FL : 128|32@1- (0.1,0) [-102.4|429496729.5] "degree"  ASDM
 SG_ zipy_serialized_data_757_FL : 160|32@1- (0.1,0) [-102.4|429496729.5] "degree"  ASDM
 SG_ zipy_serialized_data_758_FL : 192|32@1- (0.1,0) [-102.4|429496729.5] "degree"  ASDM
 SG_ zipy_serialized_data_759_FL : 224|32@1- (0.1,0) [-102.4|429496729.5] "degree"  ASDM
 SG_ zipy_serialized_data_760_FL : 256|32@1- (0.1,0) [-102.4|429496729.5] "degree"  ASDM
 SG_ zipy_serialized_data_761_FL : 288|32@1- (0.1,0) [-102.4|429496729.5] "degree"  ASDM
 SG_ zipy_serialized_data_762_FL : 320|32@1- (0.1,0) [-102.4|429496729.5] "degree"  ASDM
 SG_ zipy_serialized_data_763_FL : 352|32@1- (0.1,0) [-102.4|429496729.5] "degree"  ASDM
 SG_ zipy_serialized_data_764_FL : 384|32@1- (0.1,0) [-102.4|429496729.5] "degree"  ASDM
 SG_ zipy_serialized_data_765_FL : 416|32@1- (0.1,0) [-102.4|429496729.5] "degree"  ASDM
 SG_ zipy_serialized_data_766_FL : 448|32@1- (0.1,0) [-102.4|429496729.5] "degree"  ASDM
 SG_ zipy_serialized_data_767_FL : 480|32@1- (0.1,0) [-102.4|429496729.5] "degree"  ASDM

BO_ 352 MB79_DETECTIONS_48_FL: 64 FSRL
 SG_ zipy_serialized_data_768_FL : 0|32@1- (0.1,0) [-102.4|429496729.5] "degree"  ASDM
 SG_ zipy_serialized_data_769_FL : 32|32@1- (0.1,0) [-102.4|429496729.5] "degree"  ASDM
 SG_ zipy_serialized_data_770_FL : 64|32@1- (0.1,0) [-102.4|429496729.5] "degree"  ASDM
 SG_ zipy_serialized_data_771_FL : 96|32@1- (0.1,0) [-102.4|429496729.5] "degree"  ASDM
 SG_ zipy_serialized_data_772_FL : 128|32@1- (0.1,0) [-102.4|429496729.5] "degree"  ASDM
 SG_ zipy_serialized_data_773_FL : 160|32@1- (0.1,0) [-102.4|429496729.5] "degree"  ASDM
 SG_ zipy_serialized_data_774_FL : 192|32@1- (0.1,0) [-102.4|429496729.5] "degree"  ASDM
 SG_ zipy_serialized_data_775_FL : 224|32@1- (0.1,0) [-102.4|429496729.5] "degree"  ASDM
 SG_ zipy_serialized_data_776_FL : 256|32@1- (0.1,0) [-102.4|429496729.5] "degree"  ASDM
 SG_ zipy_serialized_data_777_FL : 288|32@1- (0.1,0) [-102.4|429496729.5] "degree"  ASDM
 SG_ zipy_serialized_data_778_FL : 320|32@1- (0.1,0) [-102.4|429496729.5] "degree"  ASDM
 SG_ zipy_serialized_data_779_FL : 352|32@1- (0.1,0) [-102.4|429496729.5] "degree"  ASDM
 SG_ zipy_serialized_data_780_FL : 384|32@1- (0.1,0) [-102.4|429496729.5] "degree"  ASDM
 SG_ zipy_serialized_data_781_FL : 416|32@1- (0.1,0) [-102.4|429496729.5] "degree"  ASDM
 SG_ zipy_serialized_data_782_FL : 448|32@1- (0.1,0) [-102.4|429496729.5] "degree"  ASDM
 SG_ zipy_serialized_data_783_FL : 480|32@1- (0.1,0) [-102.4|429496729.5] "degree"  ASDM

BO_ 353 MB79_DETECTIONS_49_FL: 64 FSRL
 SG_ zipy_serialized_data_784_FL : 0|32@1- (0.1,0) [-102.4|429496729.5] "degree"  ASDM
 SG_ zipy_serialized_data_785_FL : 32|32@1- (0.1,0) [-102.4|429496729.5] "degree"  ASDM
 SG_ zipy_serialized_data_786_FL : 64|32@1- (0.1,0) [-102.4|429496729.5] "degree"  ASDM
 SG_ zipy_serialized_data_787_FL : 96|32@1- (0.1,0) [-102.4|429496729.5] "degree"  ASDM
 SG_ zipy_serialized_data_788_FL : 128|32@1- (0.1,0) [-102.4|429496729.5] "degree"  ASDM
 SG_ zipy_serialized_data_789_FL : 160|32@1- (0.1,0) [-102.4|429496729.5] "degree"  ASDM
 SG_ zipy_serialized_data_790_FL : 192|32@1- (0.1,0) [-102.4|429496729.5] "degree"  ASDM
 SG_ zipy_serialized_data_791_FL : 224|32@1- (0.1,0) [-102.4|429496729.5] "degree"  ASDM
 SG_ zipy_serialized_data_792_FL : 256|32@1- (0.1,0) [-102.4|429496729.5] "degree"  ASDM
 SG_ zipy_serialized_data_793_FL : 288|32@1- (0.1,0) [-102.4|429496729.5] "degree"  ASDM
 SG_ zipy_serialized_data_794_FL : 320|32@1- (0.1,0) [-102.4|429496729.5] "degree"  ASDM
 SG_ zipy_serialized_data_795_FL : 352|32@1- (0.1,0) [-102.4|429496729.5] "degree"  ASDM
 SG_ zipy_serialized_data_796_FL : 384|32@1- (0.1,0) [-102.4|429496729.5] "degree"  ASDM
 SG_ zipy_serialized_data_797_FL : 416|32@1- (0.1,0) [-102.4|429496729.5] "degree"  ASDM
 SG_ zipy_serialized_data_798_FL : 448|32@1- (0.1,0) [-102.4|429496729.5] "degree"  ASDM
 SG_ zipy_serialized_data_799_FL : 480|32@1- (0.1,0) [-102.4|429496729.5] "degree"  ASDM

BO_ 354 MB79_DETECTIONS_50_FL: 64 FSRL
 SG_ zipy_serialized_data_800_FL : 0|32@1- (0.1,0) [-102.4|429496729.5] "degree"  ASDM
 SG_ zipy_serialized_data_801_FL : 32|32@1- (0.1,0) [-102.4|429496729.5] "degree"  ASDM
 SG_ zipy_serialized_data_802_FL : 64|32@1- (0.1,0) [-102.4|429496729.5] "degree"  ASDM
 SG_ zipy_serialized_data_803_FL : 96|32@1- (0.1,0) [-102.4|429496729.5] "degree"  ASDM
 SG_ zipy_serialized_data_804_FL : 128|32@1- (0.1,0) [-102.4|429496729.5] "degree"  ASDM
 SG_ zipy_serialized_data_805_FL : 160|32@1- (0.1,0) [-102.4|429496729.5] "degree"  ASDM
 SG_ zipy_serialized_data_806_FL : 192|32@1- (0.1,0) [-102.4|429496729.5] "degree"  ASDM
 SG_ zipy_serialized_data_807_FL : 224|32@1- (0.1,0) [-102.4|429496729.5] "degree"  ASDM
 SG_ zipy_serialized_data_808_FL : 256|32@1- (0.1,0) [-102.4|429496729.5] "degree"  ASDM
 SG_ zipy_serialized_data_809_FL : 288|32@1- (0.1,0) [-102.4|429496729.5] "degree"  ASDM
 SG_ zipy_serialized_data_810_FL : 320|32@1- (0.1,0) [-102.4|429496729.5] "degree"  ASDM
 SG_ zipy_serialized_data_811_FL : 352|32@1- (0.1,0) [-102.4|429496729.5] "degree"  ASDM
 SG_ zipy_serialized_data_812_FL : 384|32@1- (0.1,0) [-102.4|429496729.5] "degree"  ASDM
 SG_ zipy_serialized_data_813_FL : 416|32@1- (0.1,0) [-102.4|429496729.5] "degree"  ASDM
 SG_ zipy_serialized_data_814_FL : 448|32@1- (0.1,0) [-102.4|429496729.5] "degree"  ASDM
 SG_ zipy_serialized_data_815_FL : 480|32@1- (0.1,0) [-102.4|429496729.5] "degree"  ASDM

BO_ 355 MB79_DETECTIONS_51_FL: 64 FSRL
 SG_ zipy_serialized_data_816_FL : 0|32@1- (0.1,0) [-102.4|429496729.5] "degree"  ASDM
 SG_ zipy_serialized_data_817_FL : 32|32@1- (0.1,0) [-102.4|429496729.5] "degree"  ASDM
 SG_ zipy_serialized_data_818_FL : 64|32@1- (0.1,0) [-102.4|429496729.5] "degree"  ASDM
 SG_ zipy_serialized_data_819_FL : 96|32@1- (0.1,0) [-102.4|429496729.5] "degree"  ASDM
 SG_ zipy_serialized_data_820_FL : 128|32@1- (0.1,0) [-102.4|429496729.5] "degree"  ASDM
 SG_ zipy_serialized_data_821_FL : 160|32@1- (0.1,0) [-102.4|429496729.5] "degree"  ASDM
 SG_ zipy_serialized_data_822_FL : 192|32@1- (0.1,0) [-102.4|429496729.5] "degree"  ASDM
 SG_ zipy_serialized_data_823_FL : 224|32@1- (0.1,0) [-102.4|429496729.5] "degree"  ASDM
 SG_ zipy_serialized_data_824_FL : 256|32@1- (0.1,0) [-102.4|429496729.5] "degree"  ASDM
 SG_ zipy_serialized_data_825_FL : 288|32@1- (0.1,0) [-102.4|429496729.5] "degree"  ASDM
 SG_ zipy_serialized_data_826_FL : 320|32@1- (0.1,0) [-102.4|429496729.5] "degree"  ASDM
 SG_ zipy_serialized_data_827_FL : 352|32@1- (0.1,0) [-102.4|429496729.5] "degree"  ASDM
 SG_ zipy_serialized_data_828_FL : 384|32@1- (0.1,0) [-102.4|429496729.5] "degree"  ASDM
 SG_ zipy_serialized_data_829_FL : 416|32@1- (0.1,0) [-102.4|429496729.5] "degree"  ASDM
 SG_ zipy_serialized_data_830_FL : 448|32@1- (0.1,0) [-102.4|429496729.5] "degree"  ASDM
 SG_ zipy_serialized_data_831_FL : 480|32@1- (0.1,0) [-102.4|429496729.5] "degree"  ASDM

BO_ 356 MB79_DETECTIONS_52_FL: 64 FSRL
 SG_ zipy_serialized_data_832_FL : 0|32@1- (0.1,0) [-102.4|429496729.5] "degree"  ASDM
 SG_ zipy_serialized_data_833_FL : 32|32@1- (0.1,0) [-102.4|429496729.5] "degree"  ASDM
 SG_ zipy_serialized_data_834_FL : 64|32@1- (0.1,0) [-102.4|429496729.5] "degree"  ASDM
 SG_ zipy_serialized_data_835_FL : 96|32@1- (0.1,0) [-102.4|429496729.5] "degree"  ASDM
 SG_ zipy_serialized_data_836_FL : 128|32@1- (0.1,0) [-102.4|429496729.5] "degree"  ASDM
 SG_ zipy_serialized_data_837_FL : 160|32@1- (0.1,0) [-102.4|429496729.5] "degree"  ASDM
 SG_ zipy_serialized_data_838_FL : 192|32@1- (0.1,0) [-102.4|429496729.5] "degree"  ASDM
 SG_ zipy_serialized_data_839_FL : 224|32@1- (0.1,0) [-102.4|429496729.5] "degree"  ASDM
 SG_ zipy_serialized_data_840_FL : 256|32@1- (0.1,0) [-102.4|429496729.5] "degree"  ASDM
 SG_ zipy_serialized_data_841_FL : 288|32@1- (0.1,0) [-102.4|429496729.5] "degree"  ASDM
 SG_ zipy_serialized_data_842_FL : 320|32@1- (0.1,0) [-102.4|429496729.5] "degree"  ASDM
 SG_ zipy_serialized_data_843_FL : 352|32@1- (0.1,0) [-102.4|429496729.5] "degree"  ASDM
 SG_ zipy_serialized_data_844_FL : 384|32@1- (0.1,0) [-102.4|429496729.5] "degree"  ASDM
 SG_ zipy_serialized_data_845_FL : 416|32@1- (0.1,0) [-102.4|429496729.5] "degree"  ASDM
 SG_ zipy_serialized_data_846_FL : 448|32@1- (0.1,0) [-102.4|429496729.5] "degree"  ASDM
 SG_ zipy_serialized_data_847_FL : 480|32@1- (0.1,0) [-102.4|429496729.5] "degree"  ASDM

BO_ 357 MB79_DETECTIONS_53_FL: 64 FSRL
 SG_ zipy_serialized_data_848_FL : 0|32@1- (0.1,0) [-102.4|429496729.5] "degree"  ASDM
 SG_ zipy_serialized_data_849_FL : 32|32@1- (0.1,0) [-102.4|429496729.5] "degree"  ASDM
 SG_ zipy_serialized_data_850_FL : 64|32@1- (0.1,0) [-102.4|429496729.5] "degree"  ASDM
 SG_ zipy_serialized_data_851_FL : 96|32@1- (0.1,0) [-102.4|429496729.5] "degree"  ASDM
 SG_ zipy_serialized_data_852_FL : 128|32@1- (0.1,0) [-102.4|429496729.5] "degree"  ASDM
 SG_ zipy_serialized_data_853_FL : 160|32@1- (0.1,0) [-102.4|429496729.5] "degree"  ASDM
 SG_ zipy_serialized_data_854_FL : 192|32@1- (0.1,0) [-102.4|429496729.5] "degree"  ASDM
 SG_ zipy_serialized_data_855_FL : 224|32@1- (0.1,0) [-102.4|429496729.5] "degree"  ASDM
 SG_ zipy_serialized_data_856_FL : 256|32@1- (0.1,0) [-102.4|429496729.5] "degree"  ASDM
 SG_ zipy_serialized_data_857_FL : 288|32@1- (0.1,0) [-102.4|429496729.5] "degree"  ASDM
 SG_ zipy_serialized_data_858_FL : 320|32@1- (0.1,0) [-102.4|429496729.5] "degree"  ASDM
 SG_ zipy_serialized_data_859_FL : 352|32@1- (0.1,0) [-102.4|429496729.5] "degree"  ASDM
 SG_ zipy_serialized_data_860_FL : 384|32@1- (0.1,0) [-102.4|429496729.5] "degree"  ASDM
 SG_ zipy_serialized_data_861_FL : 416|32@1- (0.1,0) [-102.4|429496729.5] "degree"  ASDM
 SG_ zipy_serialized_data_862_FL : 448|32@1- (0.1,0) [-102.4|429496729.5] "degree"  ASDM
 SG_ zipy_serialized_data_863_FL : 480|32@1- (0.1,0) [-102.4|429496729.5] "degree"  ASDM

BO_ 358 MB79_DETECTIONS_54_FL: 64 FSRL
 SG_ zipy_serialized_data_864_FL : 0|32@1- (0.1,0) [-102.4|429496729.5] "degree"  ASDM
 SG_ zipy_serialized_data_865_FL : 32|32@1- (0.1,0) [-102.4|429496729.5] "degree"  ASDM
 SG_ zipy_serialized_data_866_FL : 64|32@1- (0.1,0) [-102.4|429496729.5] "degree"  ASDM
 SG_ zipy_serialized_data_867_FL : 96|32@1- (0.1,0) [-102.4|429496729.5] "degree"  ASDM
 SG_ zipy_serialized_data_868_FL : 128|32@1- (0.1,0) [-102.4|429496729.5] "degree"  ASDM
 SG_ zipy_serialized_data_869_FL : 160|32@1- (0.1,0) [-102.4|429496729.5] "degree"  ASDM
 SG_ zipy_serialized_data_870_FL : 192|32@1- (0.1,0) [-102.4|429496729.5] "degree"  ASDM
 SG_ zipy_serialized_data_871_FL : 224|32@1- (0.1,0) [-102.4|429496729.5] "degree"  ASDM
 SG_ zipy_serialized_data_872_FL : 256|32@1- (0.1,0) [-102.4|429496729.5] "degree"  ASDM
 SG_ zipy_serialized_data_873_FL : 288|32@1- (0.1,0) [-102.4|429496729.5] "degree"  ASDM
 SG_ zipy_serialized_data_874_FL : 320|32@1- (0.1,0) [-102.4|429496729.5] "degree"  ASDM
 SG_ zipy_serialized_data_875_FL : 352|32@1- (0.1,0) [-102.4|429496729.5] "degree"  ASDM
 SG_ zipy_serialized_data_876_FL : 384|32@1- (0.1,0) [-102.4|429496729.5] "degree"  ASDM
 SG_ zipy_serialized_data_877_FL : 416|32@1- (0.1,0) [-102.4|429496729.5] "degree"  ASDM
 SG_ zipy_serialized_data_878_FL : 448|32@1- (0.1,0) [-102.4|429496729.5] "degree"  ASDM
 SG_ zipy_serialized_data_879_FL : 480|32@1- (0.1,0) [-102.4|429496729.5] "degree"  ASDM

BO_ 359 MB79_DETECTIONS_55_FL: 64 FSRL
 SG_ zipy_serialized_data_880_FL : 0|32@1- (0.1,0) [-102.4|429496729.5] "degree"  ASDM
 SG_ zipy_serialized_data_881_FL : 32|32@1- (0.1,0) [-102.4|429496729.5] "degree"  ASDM
 SG_ zipy_serialized_data_882_FL : 64|32@1- (0.1,0) [-102.4|429496729.5] "degree"  ASDM
 SG_ zipy_serialized_data_883_FL : 96|32@1- (0.1,0) [-102.4|429496729.5] "degree"  ASDM
 SG_ zipy_serialized_data_884_FL : 128|32@1- (0.1,0) [-102.4|429496729.5] "degree"  ASDM
 SG_ zipy_serialized_data_885_FL : 160|32@1- (0.1,0) [-102.4|429496729.5] "degree"  ASDM
 SG_ zipy_serialized_data_886_FL : 192|32@1- (0.1,0) [-102.4|429496729.5] "degree"  ASDM
 SG_ zipy_serialized_data_887_FL : 224|32@1- (0.1,0) [-102.4|429496729.5] "degree"  ASDM
 SG_ zipy_serialized_data_888_FL : 256|32@1- (0.1,0) [-102.4|429496729.5] "degree"  ASDM
 SG_ zipy_serialized_data_889_FL : 288|32@1- (0.1,0) [-102.4|429496729.5] "degree"  ASDM
 SG_ zipy_serialized_data_890_FL : 320|32@1- (0.1,0) [-102.4|429496729.5] "degree"  ASDM
 SG_ zipy_serialized_data_891_FL : 352|32@1- (0.1,0) [-102.4|429496729.5] "degree"  ASDM
 SG_ zipy_serialized_data_892_FL : 384|32@1- (0.1,0) [-102.4|429496729.5] "degree"  ASDM
 SG_ zipy_serialized_data_893_FL : 416|32@1- (0.1,0) [-102.4|429496729.5] "degree"  ASDM
 SG_ zipy_serialized_data_894_FL : 448|32@1- (0.1,0) [-102.4|429496729.5] "degree"  ASDM
 SG_ zipy_serialized_data_895_FL : 480|32@1- (0.1,0) [-102.4|429496729.5] "degree"  ASDM

BO_ 769 MB79_VEHICLE_DATA: 12 ASDM
 SG_ VehiclePower_Gear_ASDM : 40|4@1+ (1,0) [0|15] "" Vector__XXX
 SG_ HostVel_ASDM : 7|16@0- (1,0) [-2000|14000] "cm/s"  FSRL,FSRR
 SG_ SteeringAngle_ASDM : 23|16@0- (1,0) [-800|800] "1/10 degree"  FSRL,FSRR
 SG_ Reserved_2_bytes_ASDM : 39|12@0+ (1,0) [0|65535] "N/A"  FSRL,FSRR
 SG_ HostYaw_ASDM : 55|16@0- (1,0) [-2048|2047] "1/1024 rad/sec"  FSRL,FSRR
 SG_ VehicleType_ASDM : 71|8@0+ (1,0) [0|255] "N/A"  FSRL,FSRR
 SG_ Clock_VehicleData_ASDM : 79|4@0+ (1,0) [0|15] "N/A"  FSRL,FSRR
 SG_ Reserved_2bit_ASDM : 75|2@0+ (1,0) [0|3] "N/A"  FSRL,FSRR
 SG_ HostTrailerAttached_ASDM : 73|1@0+ (1,0) [0|1] "N/A"  FSRL,FSRR
 SG_ HostDrivingForward_ASDM : 72|1@0+ (1,0) [0|1] "N/A"  FSRL,FSRR
 SG_ CRC_VehicleData_ASDM : 87|8@0+ (1,0) [0|255] "N/A"  FSRL,FSRR
 SG_ HostGear_ASDM : 95|8@0+ (1,0) [0|15] "N/A"  FSRL,FSRR

BO_ 784 MB79_PROCESSING_PROFIL_FL: 64 FSRL
 SG_ Function_ID_0_FL : 7|8@0+ (1,0) [0|255] ""  ASDM
 SG_ MaxExecTime_0_FL : 15|16@0+ (1,0) [0|65535] ""  ASDM
 SG_ MinExecTime_0_FL : 31|16@0+ (1,0) [0|65535] ""  ASDM
 SG_ AvgExecTime_0_FL : 47|16@0+ (1,0) [0|65535] ""  ASDM
 SG_ LatestStartTimeOffset_0_FL : 63|16@0+ (1,0) [0|65535] ""  ASDM
 SG_ EarliestStartTimeOffset_0_FL : 79|16@0+ (1,0) [0|65535] ""  ASDM
 SG_ AvgStartTimeOffset_0_FL : 95|16@0+ (1,0) [0|65535] ""  ASDM
 SG_ Function_ID_1_FL : 111|8@0+ (1,0) [0|255] ""  ASDM
 SG_ MaxExecTime_1_FL : 119|16@0+ (1,0) [0|65535] ""  ASDM
 SG_ MinExecTime_1_FL : 135|16@0+ (1,0) [0|65535] ""  ASDM
 SG_ AvgExecTime_1_FL : 151|16@0+ (1,0) [0|65535] ""  ASDM
 SG_ LatestStartTimeOffset_1_FL : 167|16@0+ (1,0) [0|65535] ""  ASDM
 SG_ EarliestStartTimeOffset_1_FL : 183|16@0+ (1,0) [0|65535] ""  ASDM
 SG_ AvgStartTimeOffset_1_FL : 199|16@0+ (1,0) [0|65535] ""  ASDM
 SG_ Function_ID_2_FL : 215|8@0+ (1,0) [0|255] ""  ASDM
 SG_ MaxExecTime_2_FL : 223|16@0+ (1,0) [0|65535] ""  ASDM
 SG_ MinExecTime_2_FL : 239|16@0+ (1,0) [0|65535] ""  ASDM
 SG_ AvgExecTime_2_FL : 255|16@0+ (1,0) [0|65535] ""  ASDM
 SG_ LatestStartTimeOffset_2_FL : 271|16@0+ (1,0) [0|65535] ""  ASDM
 SG_ EarliestStartTimeOffset_2_FL : 287|16@0+ (1,0) [0|65535] ""  ASDM
 SG_ AvgStartTimeOffset_2_FL : 303|16@0+ (1,0) [0|65535] ""  ASDM
 SG_ Function_ID_3_FL : 319|8@0+ (1,0) [0|255] ""  ASDM
 SG_ MaxExecTime_3_FL : 327|16@0+ (1,0) [0|65535] ""  ASDM
 SG_ MinExecTime_3_FL : 343|16@0+ (1,0) [0|65535] ""  ASDM
 SG_ AvgExecTime_3_FL : 359|16@0+ (1,0) [0|65535] ""  ASDM
 SG_ LatestStartTimeOffset_3_FL : 375|16@0+ (1,0) [0|65535] ""  ASDM
 SG_ EarliestStartTimeOffset_3_FL : 391|16@0+ (1,0) [0|65535] ""  ASDM
 SG_ AvgStartTimeOffset_3_FL : 407|16@0+ (1,0) [0|65535] ""  ASDM

BO_ 785 MB79_AUTOALIGN_RESULT_FL: 4 FSRL
 SG_ AutoAlignment_ErrorType_FL : 7|4@0+ (1,0) [0|15] "N/A"  ASDM
 SG_ AutoCalib_Status_FL : 3|4@0+ (1,0) [0|15] "N/A"  ASDM

BO_ 786 MB79_VOLT_MONITORING_FL: 24 FSRL
 SG_ voltage_VBAT_mv_FL : 7|16@0+ (1,0) [0|65535] "mv"  ASDM
 SG_ Reserved_2bytes_1_FL : 23|16@0+ (1,0) [0|65535] "mv"  ASDM
 SG_ Reserved_2bytes_2_FL : 39|16@0+ (1,0) [0|65535] "mv"  ASDM
 SG_ Reserved_2bytes_3_FL : 55|16@0+ (1,0) [0|65535] "mv"  ASDM
 SG_ Reserved_2bytes_4_FL : 71|16@0+ (1,0) [0|65535] "mv"  ASDM
 SG_ Reserved_2bytes_5_FL : 87|16@0+ (1,0) [0|65535] "mv"  ASDM
 SG_ Reserved_2bytes_6_FL : 103|16@0+ (1,0) [0|65535] "mv"  ASDM
 SG_ Reserved_2bytes_7_FL : 119|16@0+ (1,0) [0|65535] "mv"  ASDM
 SG_ voltage_SPOS1_mv_FL : 135|16@0+ (1,0) [0|65535] "mv"  ASDM
 SG_ voltage_SPOS2_mv_FL : 151|16@0+ (1,0) [0|65535] "mv"  ASDM
 SG_ Reserved_2bytes_8_FL : 167|16@0+ (1,0) [0|65535] "mv"  ASDM

BO_ 787 MB79_TEMP_MONITORING_FL: 32 FSRL
 SG_ Reserved_2_bytes_FL : 7|16@0- (1,0) [0|65535] "N/A"  ASDM
 SG_ TEMP_RX2_SENS_FL : 23|16@0- (1,0) [-256|255] "Celsius"  ASDM
 SG_ TSENSE2_FL : 39|16@0- (1,0) [-256|255] "Celsius"  ASDM
 SG_ TEMP_RX3_SENS_FL : 55|16@0- (1,0) [-256|255] "Celsius"  ASDM
 SG_ TEMP_RX1_SENS_FL : 71|16@0- (1,0) [-256|255] "Celsius"  ASDM
 SG_ TEMP_RX0_SENS_FL : 87|16@0- (1,0) [-256|255] "Celsius"  ASDM
 SG_ TSENSE1_FL : 103|16@0- (1,0) [-256|255] "Celsius"  ASDM
 SG_ TSENSE0_FL : 119|16@0- (1,0) [-256|255] "Celsius"  ASDM
 SG_ TEMP_TX2_SENS_FL : 135|16@0- (1,0) [-256|255] "Celsius"  ASDM
 SG_ TEMP_TX1_SENS_FL : 151|16@0- (1,0) [-256|255] "Celsius"  ASDM
 SG_ TEMP_TX0_SENS_FL : 167|16@0- (1,0) [-256|255] "Celsius"  ASDM
 SG_ TEMP_DIG1_TX3_SENS_FL : 183|16@0- (1,0) [-256|255] "Celsius"  ASDM
 SG_ MCU_Temp_Status_FL : 199|4@0- (1,0) [0|15] "N/A"  ASDM
 SG_ reserved_FL : 195|4@0- (1,0) [0|15] "N/A"  ASDM
 SG_ TEMP_PM_SENS_FL : 207|16@0- (1,0) [-256|255] "Celsius"  ASDM

BO_ 788 MB79_VERSIONS_FL: 64 FSRL
 SG_ PCANFD_Ver_App_FL : 7|8@0+ (1,0) [0|255] "N/A"  ASDM
 SG_ PCANFD_Ver_Major_FL : 15|8@0+ (1,0) [0|255] "N/A"  ASDM
 SG_ PCANFD_Ver_Minor_FL : 23|8@0+ (1,0) [0|255] "N/A"  ASDM
 SG_ SW_PIPP_Ver_App_FL : 31|16@0+ (1,0) [0|65535] "N/A"  ASDM
 SG_ SW_PIPP_Ver_Major_FL : 47|16@0+ (1,0) [0|65535] "N/A"  ASDM
 SG_ SW_PIPP_Ver_Minor_FL : 63|16@0+ (1,0) [0|65535] "N/A"  ASDM
 SG_ SW_RSP_Ver_App_FL : 79|16@0+ (1,0) [0|65535] "N/A"  ASDM
 SG_ SW_RSP_Ver_Major_FL : 95|16@0+ (1,0) [0|65535] "N/A"  ASDM
 SG_ SW_RSP_Ver_Minor_FL : 111|16@0+ (1,0) [0|65535] "N/A"  ASDM
 SG_ SW_CAFS_Ver_App_FL : 127|16@0+ (1,0) [0|65535] "N/A"  ASDM
 SG_ SW_CAFS_Ver_Major_FL : 143|16@0+ (1,0) [0|65535] "N/A"  ASDM
 SG_ SW_CAFS_Ver_Minor_FL : 159|16@0+ (1,0) [0|65535] "N/A"  ASDM
 SG_ CoresComProtcol_Ver_Major_FL : 175|16@0+ (1,0) [0|65535] "N/A"  ASDM
 SG_ CoresComProtcol_Ver_Minor_FL : 191|16@0+ (1,0) [0|65535] "N/A"  ASDM
 SG_ SW_Bootloader_Ver_App_FL : 207|16@0+ (1,0) [0|65535] "N/A"  ASDM
 SG_ SW_Bootloader_Ver_Major_FL : 223|16@0+ (1,0) [0|65535] "N/A"  ASDM
 SG_ SW_Bootloader_Ver_Minor_FL : 239|16@0+ (1,0) [0|65535] "N/A"  ASDM
 SG_ LCP2_Data_Ver_Major_FL : 255|8@0+ (1,0) [0|255] "N/A"  ASDM
 SG_ LCP2_Data_Ver_Minor_FL : 263|8@0+ (1,0) [0|255] "N/A"  ASDM
 SG_ LCP2_Design_Ver_Major_FL : 271|8@0+ (1,0) [0|255] "N/A"  ASDM
 SG_ LCP2_Design_Ver_Minor_FL : 279|8@0+ (1,0) [0|255] "N/A"  ASDM
 SG_ LCP3_SR_Ver_Major_FL : 287|16@0+ (1,0) [0|65535] "N/A"  ASDM
 SG_ LCP3_SR_Ver_Minor_FL : 303|16@0+ (1,0) [0|65535] "N/A"  ASDM
 SG_ LCP3_SR_Ver_Build_FL : 319|16@0+ (1,0) [0|65535] "N/A"  ASDM
 SG_ LCP3_LR_Ver_Major_FL : 335|16@0+ (1,0) [0|65535] "N/A"  ASDM
 SG_ LCP3_LR_Ver_Minor_FL : 351|16@0+ (1,0) [0|65535] "N/A"  ASDM
 SG_ LCP3_LR_Ver_Build_FL : 367|16@0+ (1,0) [0|65535] "N/A"  ASDM
 SG_ MCU_Cut_Ver_Major_FL : 383|16@0+ (1,0) [0|65535] "N/A"  ASDM
 SG_ MCU_Cut_Ver_Minor_FL : 399|16@0+ (1,0) [0|65535] "N/A"  ASDM
 SG_ RF_chip_Ver_FL : 415|16@0+ (1,0) [0|65535] "N/A"  ASDM
 SG_ Antenna_Ver_Major_FL : 431|8@0+ (1,0) [0|255] "N/A"  ASDM
 SG_ Antenna_Ver_Minor_FL : 439|8@0+ (1,0) [0|255] "N/A"  ASDM

BO_ 1280 MB79_LLHT_CONFIG_ERROR_FL: 64 FSRL
 SG_ Testing_Mode_ID_FL : 7|16@0+ (1,0) [0|65535] "N/A"  ASDM
 SG_ Testing_Mode_SubID_FL : 23|8@0+ (1,0) [0|255] "N/A"  ASDM
 SG_ Testing_Mode_Param_0_FL : 31|8@0+ (1,0) [0|255] "N/A"  ASDM
 SG_ Testing_Mode_Param_1_FL : 39|8@0+ (1,0) [0|255] "N/A"  ASDM
 SG_ Testing_Mode_Param_2_FL : 47|8@0+ (1,0) [0|255] "N/A"  ASDM
 SG_ Testing_Mode_Param_3_FL : 55|8@0+ (1,0) [0|255] "N/A"  ASDM
 SG_ Testing_Mode_Param_4_FL : 63|8@0+ (1,0) [0|255] "N/A"  ASDM
 SG_ Testing_Mode_Param_5_FL : 71|8@0+ (1,0) [0|255] "N/A"  ASDM
 SG_ Testing_Mode_Param_6_FL : 79|8@0+ (1,0) [0|255] "N/A"  ASDM
 SG_ Testing_Mode_Param_7_FL : 87|8@0+ (1,0) [0|255] "N/A"  ASDM
 SG_ Testing_Mode_Param_8_FL : 95|8@0+ (1,0) [0|255] "N/A"  ASDM
 SG_ Testing_Mode_Param_9_FL : 103|8@0+ (1,0) [0|255] "N/A"  ASDM
 SG_ Testing_Mode_Param_10_FL : 111|8@0+ (1,0) [0|255] "N/A"  ASDM
 SG_ Testing_Mode_Param_11_FL : 119|8@0+ (1,0) [0|255] "N/A"  ASDM
 SG_ Testing_Mode_Param_12_FL : 127|8@0+ (1,0) [0|255] "N/A"  ASDM
 SG_ Testing_Mode_Param_13_FL : 135|8@0+ (1,0) [0|255] "N/A"  ASDM
 SG_ Testing_Mode_Param_14_FL : 143|8@0+ (1,0) [0|255] "N/A"  ASDM
 SG_ Testing_Mode_Param_15_FL : 151|8@0+ (1,0) [0|255] "N/A"  ASDM
 SG_ Testing_Mode_Param_16_FL : 159|8@0+ (1,0) [0|255] "N/A"  ASDM
 SG_ Testing_Mode_Param_17_FL : 167|8@0+ (1,0) [0|255] "N/A"  ASDM
 SG_ Testing_Mode_Param_18_FL : 175|8@0+ (1,0) [0|255] "N/A"  ASDM
 SG_ Testing_Mode_Param_19_FL : 183|8@0+ (1,0) [0|255] "N/A"  ASDM
 SG_ Testing_Mode_Param_20_FL : 191|8@0+ (1,0) [0|255] "N/A"  ASDM
 SG_ Testing_Mode_Param_21_FL : 199|8@0+ (1,0) [0|255] "N/A"  ASDM
 SG_ Testing_Mode_Param_22_FL : 207|8@0+ (1,0) [0|255] "N/A"  ASDM
 SG_ Testing_Mode_Param_23_FL : 215|8@0+ (1,0) [0|255] "N/A"  ASDM
 SG_ Testing_Mode_Param_24_FL : 223|8@0+ (1,0) [0|255] "N/A"  ASDM
 SG_ Testing_Mode_Param_25_FL : 231|8@0+ (1,0) [0|255] "N/A"  ASDM
 SG_ Testing_Mode_Param_26_FL : 239|8@0+ (1,0) [0|255] "N/A"  ASDM
 SG_ Testing_Mode_Param_27_FL : 247|8@0+ (1,0) [0|255] "N/A"  ASDM
 SG_ Testing_Mode_Param_28_FL : 255|8@0+ (1,0) [0|255] "N/A"  ASDM
 SG_ Testing_Mode_Param_29_FL : 263|8@0+ (1,0) [0|255] "N/A"  ASDM
 SG_ Testing_Mode_Param_30_FL : 271|8@0+ (1,0) [0|255] "N/A"  ASDM
 SG_ Testing_Mode_Param_31_FL : 279|8@0+ (1,0) [0|255] "N/A"  ASDM
 SG_ Testing_Mode_Param_32_FL : 287|8@0+ (1,0) [0|255] "N/A"  ASDM
 SG_ Testing_Mode_Param_33_FL : 295|8@0+ (1,0) [0|255] "N/A"  ASDM
 SG_ Testing_Mode_Param_34_FL : 303|8@0+ (1,0) [0|255] "N/A"  ASDM
 SG_ Testing_Mode_Param_35_FL : 311|8@0+ (1,0) [0|255] "N/A"  ASDM
 SG_ Testing_Mode_Param_36_FL : 319|8@0+ (1,0) [0|255] "N/A"  ASDM
 SG_ Testing_Mode_Param_37_FL : 327|8@0+ (1,0) [0|255] "N/A"  ASDM
 SG_ Testing_Mode_Param_38_FL : 335|8@0+ (1,0) [0|255] "N/A"  ASDM
 SG_ Testing_Mode_Param_39_FL : 343|8@0+ (1,0) [0|255] "N/A"  ASDM
 SG_ Testing_Mode_Param_40_FL : 351|8@0+ (1,0) [0|255] "N/A"  ASDM
 SG_ Testing_Mode_Param_41_FL : 359|8@0+ (1,0) [0|255] "N/A"  ASDM
 SG_ Testing_Mode_Param_42_FL : 367|8@0+ (1,0) [0|255] "N/A"  ASDM
 SG_ Testing_Mode_Param_43_FL : 375|8@0+ (1,0) [0|255] "N/A"  ASDM
 SG_ Testing_Mode_Param_44_FL : 383|8@0+ (1,0) [0|255] "N/A"  ASDM
 SG_ Testing_Mode_Param_45_FL : 391|8@0+ (1,0) [0|255] "N/A"  ASDM
 SG_ Testing_Mode_Param_46_FL : 399|8@0+ (1,0) [0|255] "N/A"  ASDM
 SG_ Testing_Mode_Param_47_FL : 407|8@0+ (1,0) [0|255] "N/A"  ASDM
 SG_ Testing_Mode_Param_48_FL : 415|8@0+ (1,0) [0|255] "N/A"  ASDM
 SG_ Testing_Mode_Param_49_FL : 423|8@0+ (1,0) [0|255] "N/A"  ASDM
 SG_ Testing_Mode_Param_50_FL : 431|8@0+ (1,0) [0|255] "N/A"  ASDM
 SG_ Testing_Mode_Param_51_FL : 439|8@0+ (1,0) [0|255] "N/A"  ASDM
 SG_ Testing_Mode_Param_52_FL : 447|8@0+ (1,0) [0|255] "N/A"  ASDM
 SG_ Testing_Mode_Param_53_FL : 455|8@0+ (1,0) [0|255] "N/A"  ASDM
 SG_ Testing_Mode_Param_54_FL : 463|8@0+ (1,0) [0|255] "N/A"  ASDM
 SG_ Testing_Mode_Param_55_FL : 471|8@0+ (1,0) [0|255] "N/A"  ASDM
 SG_ Testing_Mode_Param_56_FL : 479|8@0+ (1,0) [0|255] "N/A"  ASDM
 SG_ Testing_Mode_Param_57_FL : 487|8@0+ (1,0) [0|255] "N/A"  ASDM
 SG_ Testing_Mode_Param_58_FL : 495|8@0+ (1,0) [0|255] "N/A"  ASDM
 SG_ Testing_Mode_Param_59_FL : 503|8@0+ (1,0) [0|255] "N/A"  ASDM
 SG_ Testing_Mode_Param_60_FL : 511|8@0+ (1,0) [0|255] "N/A"  ASDM

BO_ 1290 MB79_LLHT_HEADER_FL: 64 FSRL
 SG_ LLHT_Data_Header_Mode_ID_FL : 7|16@0+ (1,0) [0|65535] "N/A"  ASDM
 SG_ LLHT_Data_Header_SubID_FL : 23|8@0+ (1,0) [0|255] "N/A"  ASDM
 SG_ LLHT_Data_Header_MCC_FL : 31|32@0+ (1,0) [0|4294967295] "N/A"  ASDM
 SG_ LLHT_Data_Header_BlkLength_FL : 63|16@0+ (1,0) [0|65535] "N/A"  ASDM
 SG_ LLHT_Data_Header_BlockCnt_FL : 79|8@0+ (1,0) [0|255] "N/A"  ASDM
 SG_ LLHT_Data_Header_NumBlocks_FL : 87|8@0+ (1,0) [0|255] "N/A"  ASDM
 SG_ LLHT_Data_Header_FrmCnt_FL : 95|8@0+ (1,0) [0|255] "N/A"  ASDM
 SG_ LLHT_Data_Header_Reserved_FL : 103|16@0+ (1,0) [0|65535] "N/A"  ASDM
 SG_ LLHT_Data_Header_Config_0_FL : 119|8@0+ (1,0) [0|255] "N/A"  ASDM
 SG_ LLHT_Data_Header_Config_1_FL : 127|8@0+ (1,0) [0|255] "N/A"  ASDM
 SG_ LLHT_Data_Header_Config_2_FL : 135|8@0+ (1,0) [0|255] "N/A"  ASDM
 SG_ LLHT_Data_Header_Config_3_FL : 143|8@0+ (1,0) [0|255] "N/A"  ASDM
 SG_ LLHT_Data_Header_Config_4_FL : 151|8@0+ (1,0) [0|255] "N/A"  ASDM
 SG_ LLHT_Data_Header_Config_5_FL : 159|8@0+ (1,0) [0|255] "N/A"  ASDM
 SG_ LLHT_Data_Header_Config_6_FL : 167|8@0+ (1,0) [0|255] "N/A"  ASDM
 SG_ LLHT_Data_Header_Config_7_FL : 175|8@0+ (1,0) [0|255] "N/A"  ASDM
 SG_ LLHT_Data_Header_Config_8_FL : 183|8@0+ (1,0) [0|255] "N/A"  ASDM
 SG_ LLHT_Data_Header_Config_9_FL : 191|8@0+ (1,0) [0|255] "N/A"  ASDM
 SG_ LLHT_Data_Header_Config_10_FL : 199|8@0+ (1,0) [0|255] "N/A"  ASDM
 SG_ LLHT_Data_Header_Config_11_FL : 207|8@0+ (1,0) [0|255] "N/A"  ASDM
 SG_ LLHT_Data_Header_Config_12_FL : 215|8@0+ (1,0) [0|255] "N/A"  ASDM
 SG_ LLHT_Data_Header_Config_13_FL : 223|8@0+ (1,0) [0|255] "N/A"  ASDM
 SG_ LLHT_Data_Header_Config_14_FL : 231|8@0+ (1,0) [0|255] "N/A"  ASDM
 SG_ LLHT_Data_Header_Config_15_FL : 239|8@0+ (1,0) [0|255] "N/A"  ASDM
 SG_ LLHT_Data_Header_Config_16_FL : 247|8@0+ (1,0) [0|255] "N/A"  ASDM
 SG_ LLHT_Data_Header_Config_17_FL : 255|8@0+ (1,0) [0|255] "N/A"  ASDM
 SG_ LLHT_Data_Header_Config_18_FL : 263|8@0+ (1,0) [0|255] "N/A"  ASDM
 SG_ LLHT_Data_Header_Config_19_FL : 271|8@0+ (1,0) [0|255] "N/A"  ASDM
 SG_ LLHT_Data_Header_Config_20_FL : 279|8@0+ (1,0) [0|255] "N/A"  ASDM
 SG_ LLHT_Data_Header_Config_21_FL : 287|8@0+ (1,0) [0|255] "N/A"  ASDM
 SG_ LLHT_Data_Header_Config_22_FL : 295|8@0+ (1,0) [0|255] "N/A"  ASDM
 SG_ LLHT_Data_Header_Config_23_FL : 303|8@0+ (1,0) [0|255] "N/A"  ASDM
 SG_ LLHT_Data_Header_Config_24_FL : 311|8@0+ (1,0) [0|255] "N/A"  ASDM
 SG_ LLHT_Data_Header_Config_25_FL : 319|8@0+ (1,0) [0|255] "N/A"  ASDM
 SG_ LLHT_Data_Header_Config_26_FL : 327|8@0+ (1,0) [0|255] "N/A"  ASDM
 SG_ LLHT_Data_Header_Config_27_FL : 335|8@0+ (1,0) [0|255] "N/A"  ASDM
 SG_ LLHT_Data_Header_Config_28_FL : 343|8@0+ (1,0) [0|255] "N/A"  ASDM
 SG_ LLHT_Data_Header_Config_29_FL : 351|8@0+ (1,0) [0|255] "N/A"  ASDM
 SG_ LLHT_Data_Header_Config_30_FL : 359|8@0+ (1,0) [0|255] "N/A"  ASDM
 SG_ LLHT_Data_Header_Config_31_FL : 367|8@0+ (1,0) [0|255] "N/A"  ASDM
 SG_ LLHT_Data_Header_Config_32_FL : 375|8@0+ (1,0) [0|255] "N/A"  ASDM
 SG_ LLHT_Data_Header_Config_33_FL : 383|8@0+ (1,0) [0|255] "N/A"  ASDM
 SG_ LLHT_Data_Header_Config_34_FL : 391|8@0+ (1,0) [0|255] "N/A"  ASDM
 SG_ LLHT_Data_Header_Config_35_FL : 399|8@0+ (1,0) [0|255] "N/A"  ASDM
 SG_ LLHT_Data_Header_Config_36_FL : 407|8@0+ (1,0) [0|255] "N/A"  ASDM
 SG_ LLHT_Data_Header_Config_37_FL : 415|8@0+ (1,0) [0|255] "N/A"  ASDM
 SG_ LLHT_Data_Header_Config_38_FL : 423|8@0+ (1,0) [0|255] "N/A"  ASDM
 SG_ LLHT_Data_Header_Config_39_FL : 431|8@0+ (1,0) [0|255] "N/A"  ASDM
 SG_ LLHT_Data_Header_Config_40_FL : 439|8@0+ (1,0) [0|255] "N/A"  ASDM
 SG_ LLHT_Data_Header_Config_41_FL : 447|8@0+ (1,0) [0|255] "N/A"  ASDM
 SG_ LLHT_Data_Header_Config_42_FL : 455|8@0+ (1,0) [0|255] "N/A"  ASDM
 SG_ LLHT_Data_Header_Config_43_FL : 463|8@0+ (1,0) [0|255] "N/A"  ASDM
 SG_ LLHT_Data_Header_Config_44_FL : 471|8@0+ (1,0) [0|255] "N/A"  ASDM
 SG_ LLHT_Data_Header_Config_45_FL : 479|8@0+ (1,0) [0|255] "N/A"  ASDM
 SG_ LLHT_Data_Header_Config_46_FL : 487|8@0+ (1,0) [0|255] "N/A"  ASDM
 SG_ LLHT_Data_Header_Config_47_FL : 495|8@0+ (1,0) [0|255] "N/A"  ASDM
 SG_ LLHT_Data_Header_Config_48_FL : 503|8@0+ (1,0) [0|255] "N/A"  ASDM
 SG_ LLHT_Data_Header_Config_49_FL : 511|8@0+ (1,0) [0|255] "N/A"  ASDM

BO_ 1291 MB79_LLHT_0_FL: 64 FSRL
 SG_ LLHT_Data_0_payload_0_FL : 7|16@0+ (1,0) [0|65535] "N/A"  ASDM
 SG_ LLHT_Data_0_payload_1_FL : 23|16@0+ (1,0) [0|65535] "N/A"  ASDM
 SG_ LLHT_Data_0_payload_2_FL : 39|16@0+ (1,0) [0|65535] "N/A"  ASDM
 SG_ LLHT_Data_0_payload_3_FL : 55|16@0+ (1,0) [0|65535] "N/A"  ASDM
 SG_ LLHT_Data_0_payload_4_FL : 71|16@0+ (1,0) [0|65535] "N/A"  ASDM
 SG_ LLHT_Data_0_payload_5_FL : 87|16@0+ (1,0) [0|65535] "N/A"  ASDM
 SG_ LLHT_Data_0_payload_6_FL : 103|16@0+ (1,0) [0|65535] "N/A"  ASDM
 SG_ LLHT_Data_0_payload_7_FL : 119|16@0+ (1,0) [0|65535] "N/A"  ASDM
 SG_ LLHT_Data_0_payload_8_FL : 135|16@0+ (1,0) [0|65535] "N/A"  ASDM
 SG_ LLHT_Data_0_payload_9_FL : 151|16@0+ (1,0) [0|65535] "N/A"  ASDM
 SG_ LLHT_Data_0_payload_10_FL : 167|16@0+ (1,0) [0|65535] "N/A"  ASDM
 SG_ LLHT_Data_0_payload_11_FL : 183|16@0+ (1,0) [0|65535] "N/A"  ASDM
 SG_ LLHT_Data_0_payload_12_FL : 199|16@0+ (1,0) [0|65535] "N/A"  ASDM
 SG_ LLHT_Data_0_payload_13_FL : 215|16@0+ (1,0) [0|65535] "N/A"  ASDM
 SG_ LLHT_Data_0_payload_14_FL : 231|16@0+ (1,0) [0|65535] "N/A"  ASDM
 SG_ LLHT_Data_0_payload_15_FL : 247|16@0+ (1,0) [0|65535] "N/A"  ASDM
 SG_ LLHT_Data_0_payload_16_FL : 263|16@0+ (1,0) [0|65535] "N/A"  ASDM
 SG_ LLHT_Data_0_payload_17_FL : 279|16@0+ (1,0) [0|65535] "N/A"  ASDM
 SG_ LLHT_Data_0_payload_18_FL : 295|16@0+ (1,0) [0|65535] "N/A"  ASDM
 SG_ LLHT_Data_0_payload_19_FL : 311|16@0+ (1,0) [0|65535] "N/A"  ASDM
 SG_ LLHT_Data_0_payload_20_FL : 327|16@0+ (1,0) [0|65535] "N/A"  ASDM
 SG_ LLHT_Data_0_payload_21_FL : 343|16@0+ (1,0) [0|65535] "N/A"  ASDM
 SG_ LLHT_Data_0_payload_22_FL : 359|16@0+ (1,0) [0|65535] "N/A"  ASDM
 SG_ LLHT_Data_0_payload_23_FL : 375|16@0+ (1,0) [0|65535] "N/A"  ASDM
 SG_ LLHT_Data_0_payload_24_FL : 391|16@0+ (1,0) [0|65535] "N/A"  ASDM
 SG_ LLHT_Data_0_payload_25_FL : 407|16@0+ (1,0) [0|65535] "N/A"  ASDM
 SG_ LLHT_Data_0_payload_26_FL : 423|16@0+ (1,0) [0|65535] "N/A"  ASDM
 SG_ LLHT_Data_0_payload_27_FL : 439|16@0+ (1,0) [0|65535] "N/A"  ASDM
 SG_ LLHT_Data_0_payload_28_FL : 455|16@0+ (1,0) [0|65535] "N/A"  ASDM
 SG_ LLHT_Data_0_payload_29_FL : 471|16@0+ (1,0) [0|65535] "N/A"  ASDM
 SG_ LLHT_Data_0_payload_30_FL : 487|16@0+ (1,0) [0|65535] "N/A"  ASDM
 SG_ LLHT_Data_0_payload_31_FL : 503|16@0+ (1,0) [0|65535] "N/A"  ASDM

BO_ 1292 MB79_LLHT_1_FL: 64 FSRL
 SG_ LLHT_Data_1_payload_32_FL : 7|16@0+ (1,0) [0|65535] "N/A"  ASDM
 SG_ LLHT_Data_1_payload_33_FL : 23|16@0+ (1,0) [0|65535] "N/A"  ASDM
 SG_ LLHT_Data_1_payload_34_FL : 39|16@0+ (1,0) [0|65535] "N/A"  ASDM
 SG_ LLHT_Data_1_payload_35_FL : 55|16@0+ (1,0) [0|65535] "N/A"  ASDM
 SG_ LLHT_Data_1_payload_36_FL : 71|16@0+ (1,0) [0|65535] "N/A"  ASDM
 SG_ LLHT_Data_1_payload_37_FL : 87|16@0+ (1,0) [0|65535] "N/A"  ASDM
 SG_ LLHT_Data_1_payload_38_FL : 103|16@0+ (1,0) [0|65535] "N/A"  ASDM
 SG_ LLHT_Data_1_payload_39_FL : 119|16@0+ (1,0) [0|65535] "N/A"  ASDM
 SG_ LLHT_Data_1_payload_40_FL : 135|16@0+ (1,0) [0|65535] "N/A"  ASDM
 SG_ LLHT_Data_1_payload_41_FL : 151|16@0+ (1,0) [0|65535] "N/A"  ASDM
 SG_ LLHT_Data_1_payload_42_FL : 167|16@0+ (1,0) [0|65535] "N/A"  ASDM
 SG_ LLHT_Data_1_payload_43_FL : 183|16@0+ (1,0) [0|65535] "N/A"  ASDM
 SG_ LLHT_Data_1_payload_44_FL : 199|16@0+ (1,0) [0|65535] "N/A"  ASDM
 SG_ LLHT_Data_1_payload_45_FL : 215|16@0+ (1,0) [0|65535] "N/A"  ASDM
 SG_ LLHT_Data_1_payload_46_FL : 231|16@0+ (1,0) [0|65535] "N/A"  ASDM
 SG_ LLHT_Data_1_payload_47_FL : 247|16@0+ (1,0) [0|65535] "N/A"  ASDM
 SG_ LLHT_Data_1_payload_48_FL : 263|16@0+ (1,0) [0|65535] "N/A"  ASDM
 SG_ LLHT_Data_1_payload_49_FL : 279|16@0+ (1,0) [0|65535] "N/A"  ASDM
 SG_ LLHT_Data_1_payload_50_FL : 295|16@0+ (1,0) [0|65535] "N/A"  ASDM
 SG_ LLHT_Data_1_payload_51_FL : 311|16@0+ (1,0) [0|65535] "N/A"  ASDM
 SG_ LLHT_Data_1_payload_52_FL : 327|16@0+ (1,0) [0|65535] "N/A"  ASDM
 SG_ LLHT_Data_1_payload_53_FL : 343|16@0+ (1,0) [0|65535] "N/A"  ASDM
 SG_ LLHT_Data_1_payload_54_FL : 359|16@0+ (1,0) [0|65535] "N/A"  ASDM
 SG_ LLHT_Data_1_payload_55_FL : 375|16@0+ (1,0) [0|65535] "N/A"  ASDM
 SG_ LLHT_Data_1_payload_56_FL : 391|16@0+ (1,0) [0|65535] "N/A"  ASDM
 SG_ LLHT_Data_1_payload_57_FL : 407|16@0+ (1,0) [0|65535] "N/A"  ASDM
 SG_ LLHT_Data_1_payload_58_FL : 423|16@0+ (1,0) [0|65535] "N/A"  ASDM
 SG_ LLHT_Data_1_payload_59_FL : 439|16@0+ (1,0) [0|65535] "N/A"  ASDM
 SG_ LLHT_Data_1_payload_60_FL : 455|16@0+ (1,0) [0|65535] "N/A"  ASDM
 SG_ LLHT_Data_1_payload_61_FL : 471|16@0+ (1,0) [0|65535] "N/A"  ASDM
 SG_ LLHT_Data_1_payload_62_FL : 487|16@0+ (1,0) [0|65535] "N/A"  ASDM
 SG_ LLHT_Data_1_payload_63_FL : 503|16@0+ (1,0) [0|65535] "N/A"  ASDM

BO_ 1293 MB79_LLHT_2_FL: 64 FSRL
 SG_ LLHT_Data_2_payload_64_FL : 7|16@0+ (1,0) [0|65535] "N/A"  ASDM
 SG_ LLHT_Data_2_payload_65_FL : 23|16@0+ (1,0) [0|65535] "N/A"  ASDM
 SG_ LLHT_Data_2_payload_66_FL : 39|16@0+ (1,0) [0|65535] "N/A"  ASDM
 SG_ LLHT_Data_2_payload_67_FL : 55|16@0+ (1,0) [0|65535] "N/A"  ASDM
 SG_ LLHT_Data_2_payload_68_FL : 71|16@0+ (1,0) [0|65535] "N/A"  ASDM
 SG_ LLHT_Data_2_payload_69_FL : 87|16@0+ (1,0) [0|65535] "N/A"  ASDM
 SG_ LLHT_Data_2_payload_70_FL : 103|16@0+ (1,0) [0|65535] "N/A"  ASDM
 SG_ LLHT_Data_2_payload_71_FL : 119|16@0+ (1,0) [0|65535] "N/A"  ASDM
 SG_ LLHT_Data_2_payload_72_FL : 135|16@0+ (1,0) [0|65535] "N/A"  ASDM
 SG_ LLHT_Data_2_payload_73_FL : 151|16@0+ (1,0) [0|65535] "N/A"  ASDM
 SG_ LLHT_Data_2_payload_74_FL : 167|16@0+ (1,0) [0|65535] "N/A"  ASDM
 SG_ LLHT_Data_2_payload_75_FL : 183|16@0+ (1,0) [0|65535] "N/A"  ASDM
 SG_ LLHT_Data_2_payload_76_FL : 199|16@0+ (1,0) [0|65535] "N/A"  ASDM
 SG_ LLHT_Data_2_payload_77_FL : 215|16@0+ (1,0) [0|65535] "N/A"  ASDM
 SG_ LLHT_Data_2_payload_78_FL : 231|16@0+ (1,0) [0|65535] "N/A"  ASDM
 SG_ LLHT_Data_2_payload_79_FL : 247|16@0+ (1,0) [0|65535] "N/A"  ASDM
 SG_ LLHT_Data_2_payload_80_FL : 263|16@0+ (1,0) [0|65535] "N/A"  ASDM
 SG_ LLHT_Data_2_payload_81_FL : 279|16@0+ (1,0) [0|65535] "N/A"  ASDM
 SG_ LLHT_Data_2_payload_82_FL : 295|16@0+ (1,0) [0|65535] "N/A"  ASDM
 SG_ LLHT_Data_2_payload_83_FL : 311|16@0+ (1,0) [0|65535] "N/A"  ASDM
 SG_ LLHT_Data_2_payload_84_FL : 327|16@0+ (1,0) [0|65535] "N/A"  ASDM
 SG_ LLHT_Data_2_payload_85_FL : 343|16@0+ (1,0) [0|65535] "N/A"  ASDM
 SG_ LLHT_Data_2_payload_86_FL : 359|16@0+ (1,0) [0|65535] "N/A"  ASDM
 SG_ LLHT_Data_2_payload_87_FL : 375|16@0+ (1,0) [0|65535] "N/A"  ASDM
 SG_ LLHT_Data_2_payload_88_FL : 391|16@0+ (1,0) [0|65535] "N/A"  ASDM
 SG_ LLHT_Data_2_payload_89_FL : 407|16@0+ (1,0) [0|65535] "N/A"  ASDM
 SG_ LLHT_Data_2_payload_90_FL : 423|16@0+ (1,0) [0|65535] "N/A"  ASDM
 SG_ LLHT_Data_2_payload_91_FL : 439|16@0+ (1,0) [0|65535] "N/A"  ASDM
 SG_ LLHT_Data_2_payload_92_FL : 455|16@0+ (1,0) [0|65535] "N/A"  ASDM
 SG_ LLHT_Data_2_payload_93_FL : 471|16@0+ (1,0) [0|65535] "N/A"  ASDM
 SG_ LLHT_Data_2_payload_94_FL : 487|16@0+ (1,0) [0|65535] "N/A"  ASDM
 SG_ LLHT_Data_2_payload_95_FL : 503|16@0+ (1,0) [0|65535] "N/A"  ASDM

BO_ 1294 MB79_LLHT_3_FL: 64 FSRL
 SG_ LLHT_Data_3_payload_96_FL : 7|16@0+ (1,0) [0|65535] "N/A"  ASDM
 SG_ LLHT_Data_3_payload_97_FL : 23|16@0+ (1,0) [0|65535] "N/A"  ASDM
 SG_ LLHT_Data_3_payload_98_FL : 39|16@0+ (1,0) [0|65535] "N/A"  ASDM
 SG_ LLHT_Data_3_payload_99_FL : 55|16@0+ (1,0) [0|65535] "N/A"  ASDM
 SG_ LLHT_Data_3_payload_100_FL : 71|16@0+ (1,0) [0|65535] "N/A"  ASDM
 SG_ LLHT_Data_3_payload_101_FL : 87|16@0+ (1,0) [0|65535] "N/A"  ASDM
 SG_ LLHT_Data_3_payload_102_FL : 103|16@0+ (1,0) [0|65535] "N/A"  ASDM
 SG_ LLHT_Data_3_payload_103_FL : 119|16@0+ (1,0) [0|65535] "N/A"  ASDM
 SG_ LLHT_Data_3_payload_104_FL : 135|16@0+ (1,0) [0|65535] "N/A"  ASDM
 SG_ LLHT_Data_3_payload_105_FL : 151|16@0+ (1,0) [0|65535] "N/A"  ASDM
 SG_ LLHT_Data_3_payload_106_FL : 167|16@0+ (1,0) [0|65535] "N/A"  ASDM
 SG_ LLHT_Data_3_payload_107_FL : 183|16@0+ (1,0) [0|65535] "N/A"  ASDM
 SG_ LLHT_Data_3_payload_108_FL : 199|16@0+ (1,0) [0|65535] "N/A"  ASDM
 SG_ LLHT_Data_3_payload_109_FL : 215|16@0+ (1,0) [0|65535] "N/A"  ASDM
 SG_ LLHT_Data_3_payload_110_FL : 231|16@0+ (1,0) [0|65535] "N/A"  ASDM
 SG_ LLHT_Data_3_payload_111_FL : 247|16@0+ (1,0) [0|65535] "N/A"  ASDM
 SG_ LLHT_Data_3_payload_112_FL : 263|16@0+ (1,0) [0|65535] "N/A"  ASDM
 SG_ LLHT_Data_3_payload_113_FL : 279|16@0+ (1,0) [0|65535] "N/A"  ASDM
 SG_ LLHT_Data_3_payload_114_FL : 295|16@0+ (1,0) [0|65535] "N/A"  ASDM
 SG_ LLHT_Data_3_payload_115_FL : 311|16@0+ (1,0) [0|65535] "N/A"  ASDM
 SG_ LLHT_Data_3_payload_116_FL : 327|16@0+ (1,0) [0|65535] "N/A"  ASDM
 SG_ LLHT_Data_3_payload_117_FL : 343|16@0+ (1,0) [0|65535] "N/A"  ASDM
 SG_ LLHT_Data_3_payload_118_FL : 359|16@0+ (1,0) [0|65535] "N/A"  ASDM
 SG_ LLHT_Data_3_payload_119_FL : 375|16@0+ (1,0) [0|65535] "N/A"  ASDM
 SG_ LLHT_Data_3_payload_120_FL : 391|16@0+ (1,0) [0|65535] "N/A"  ASDM
 SG_ LLHT_Data_3_payload_121_FL : 407|16@0+ (1,0) [0|65535] "N/A"  ASDM
 SG_ LLHT_Data_3_payload_122_FL : 423|16@0+ (1,0) [0|65535] "N/A"  ASDM
 SG_ LLHT_Data_3_payload_123_FL : 439|16@0+ (1,0) [0|65535] "N/A"  ASDM
 SG_ LLHT_Data_3_payload_124_FL : 455|16@0+ (1,0) [0|65535] "N/A"  ASDM
 SG_ LLHT_Data_3_payload_125_FL : 471|16@0+ (1,0) [0|65535] "N/A"  ASDM
 SG_ LLHT_Data_3_payload_126_FL : 487|16@0+ (1,0) [0|65535] "N/A"  ASDM
 SG_ LLHT_Data_3_payload_127_FL : 503|16@0+ (1,0) [0|65535] "N/A"  ASDM

BO_ 1295 MB79_LLHT_4_FL: 64 FSRL
 SG_ LLHT_Data_4_payload_128_FL : 7|16@0+ (1,0) [0|65535] "N/A"  ASDM
 SG_ LLHT_Data_4_payload_129_FL : 23|16@0+ (1,0) [0|65535] "N/A"  ASDM
 SG_ LLHT_Data_4_payload_130_FL : 39|16@0+ (1,0) [0|65535] "N/A"  ASDM
 SG_ LLHT_Data_4_payload_131_FL : 55|16@0+ (1,0) [0|65535] "N/A"  ASDM
 SG_ LLHT_Data_4_payload_132_FL : 71|16@0+ (1,0) [0|65535] "N/A"  ASDM
 SG_ LLHT_Data_4_payload_133_FL : 87|16@0+ (1,0) [0|65535] "N/A"  ASDM
 SG_ LLHT_Data_4_payload_134_FL : 103|16@0+ (1,0) [0|65535] "N/A"  ASDM
 SG_ LLHT_Data_4_payload_135_FL : 119|16@0+ (1,0) [0|65535] "N/A"  ASDM
 SG_ LLHT_Data_4_payload_136_FL : 135|16@0+ (1,0) [0|65535] "N/A"  ASDM
 SG_ LLHT_Data_4_payload_137_FL : 151|16@0+ (1,0) [0|65535] "N/A"  ASDM
 SG_ LLHT_Data_4_payload_138_FL : 167|16@0+ (1,0) [0|65535] "N/A"  ASDM
 SG_ LLHT_Data_4_payload_139_FL : 183|16@0+ (1,0) [0|65535] "N/A"  ASDM
 SG_ LLHT_Data_4_payload_140_FL : 199|16@0+ (1,0) [0|65535] "N/A"  ASDM
 SG_ LLHT_Data_4_payload_141_FL : 215|16@0+ (1,0) [0|65535] "N/A"  ASDM
 SG_ LLHT_Data_4_payload_142_FL : 231|16@0+ (1,0) [0|65535] "N/A"  ASDM
 SG_ LLHT_Data_4_payload_143_FL : 247|16@0+ (1,0) [0|65535] "N/A"  ASDM
 SG_ LLHT_Data_4_payload_144_FL : 263|16@0+ (1,0) [0|65535] "N/A"  ASDM
 SG_ LLHT_Data_4_payload_145_FL : 279|16@0+ (1,0) [0|65535] "N/A"  ASDM
 SG_ LLHT_Data_4_payload_146_FL : 295|16@0+ (1,0) [0|65535] "N/A"  ASDM
 SG_ LLHT_Data_4_payload_147_FL : 311|16@0+ (1,0) [0|65535] "N/A"  ASDM
 SG_ LLHT_Data_4_payload_148_FL : 327|16@0+ (1,0) [0|65535] "N/A"  ASDM
 SG_ LLHT_Data_4_payload_149_FL : 343|16@0+ (1,0) [0|65535] "N/A"  ASDM
 SG_ LLHT_Data_4_payload_150_FL : 359|16@0+ (1,0) [0|65535] "N/A"  ASDM
 SG_ LLHT_Data_4_payload_151_FL : 375|16@0+ (1,0) [0|65535] "N/A"  ASDM
 SG_ LLHT_Data_4_payload_152_FL : 391|16@0+ (1,0) [0|65535] "N/A"  ASDM
 SG_ LLHT_Data_4_payload_153_FL : 407|16@0+ (1,0) [0|65535] "N/A"  ASDM
 SG_ LLHT_Data_4_payload_154_FL : 423|16@0+ (1,0) [0|65535] "N/A"  ASDM
 SG_ LLHT_Data_4_payload_155_FL : 439|16@0+ (1,0) [0|65535] "N/A"  ASDM
 SG_ LLHT_Data_4_payload_156_FL : 455|16@0+ (1,0) [0|65535] "N/A"  ASDM
 SG_ LLHT_Data_4_payload_157_FL : 471|16@0+ (1,0) [0|65535] "N/A"  ASDM
 SG_ LLHT_Data_4_payload_158_FL : 487|16@0+ (1,0) [0|65535] "N/A"  ASDM
 SG_ LLHT_Data_4_payload_159_FL : 503|16@0+ (1,0) [0|65535] "N/A"  ASDM

BO_ 1296 MB79_LLHT_5_FL: 64 FSRL
 SG_ LLHT_Data_5_payload_160_FL : 7|16@0+ (1,0) [0|65535] "N/A"  ASDM
 SG_ LLHT_Data_5_payload_161_FL : 23|16@0+ (1,0) [0|65535] "N/A"  ASDM
 SG_ LLHT_Data_5_payload_162_FL : 39|16@0+ (1,0) [0|65535] "N/A"  ASDM
 SG_ LLHT_Data_5_payload_163_FL : 55|16@0+ (1,0) [0|65535] "N/A"  ASDM
 SG_ LLHT_Data_5_payload_164_FL : 71|16@0+ (1,0) [0|65535] "N/A"  ASDM
 SG_ LLHT_Data_5_payload_165_FL : 87|16@0+ (1,0) [0|65535] "N/A"  ASDM
 SG_ LLHT_Data_5_payload_166_FL : 103|16@0+ (1,0) [0|65535] "N/A"  ASDM
 SG_ LLHT_Data_5_payload_167_FL : 119|16@0+ (1,0) [0|65535] "N/A"  ASDM
 SG_ LLHT_Data_5_payload_168_FL : 135|16@0+ (1,0) [0|65535] "N/A"  ASDM
 SG_ LLHT_Data_5_payload_169_FL : 151|16@0+ (1,0) [0|65535] "N/A"  ASDM
 SG_ LLHT_Data_5_payload_170_FL : 167|16@0+ (1,0) [0|65535] "N/A"  ASDM
 SG_ LLHT_Data_5_payload_171_FL : 183|16@0+ (1,0) [0|65535] "N/A"  ASDM
 SG_ LLHT_Data_5_payload_172_FL : 199|16@0+ (1,0) [0|65535] "N/A"  ASDM
 SG_ LLHT_Data_5_payload_173_FL : 215|16@0+ (1,0) [0|65535] "N/A"  ASDM
 SG_ LLHT_Data_5_payload_174_FL : 231|16@0+ (1,0) [0|65535] "N/A"  ASDM
 SG_ LLHT_Data_5_payload_175_FL : 247|16@0+ (1,0) [0|65535] "N/A"  ASDM
 SG_ LLHT_Data_5_payload_176_FL : 263|16@0+ (1,0) [0|65535] "N/A"  ASDM
 SG_ LLHT_Data_5_payload_177_FL : 279|16@0+ (1,0) [0|65535] "N/A"  ASDM
 SG_ LLHT_Data_5_payload_178_FL : 295|16@0+ (1,0) [0|65535] "N/A"  ASDM
 SG_ LLHT_Data_5_payload_179_FL : 311|16@0+ (1,0) [0|65535] "N/A"  ASDM
 SG_ LLHT_Data_5_payload_180_FL : 327|16@0+ (1,0) [0|65535] "N/A"  ASDM
 SG_ LLHT_Data_5_payload_181_FL : 343|16@0+ (1,0) [0|65535] "N/A"  ASDM
 SG_ LLHT_Data_5_payload_182_FL : 359|16@0+ (1,0) [0|65535] "N/A"  ASDM
 SG_ LLHT_Data_5_payload_183_FL : 375|16@0+ (1,0) [0|65535] "N/A"  ASDM
 SG_ LLHT_Data_5_payload_184_FL : 391|16@0+ (1,0) [0|65535] "N/A"  ASDM
 SG_ LLHT_Data_5_payload_185_FL : 407|16@0+ (1,0) [0|65535] "N/A"  ASDM
 SG_ LLHT_Data_5_payload_186_FL : 423|16@0+ (1,0) [0|65535] "N/A"  ASDM
 SG_ LLHT_Data_5_payload_187_FL : 439|16@0+ (1,0) [0|65535] "N/A"  ASDM
 SG_ LLHT_Data_5_payload_188_FL : 455|16@0+ (1,0) [0|65535] "N/A"  ASDM
 SG_ LLHT_Data_5_payload_189_FL : 471|16@0+ (1,0) [0|65535] "N/A"  ASDM
 SG_ LLHT_Data_5_payload_190_FL : 487|16@0+ (1,0) [0|65535] "N/A"  ASDM
 SG_ LLHT_Data_5_payload_191_FL : 503|16@0+ (1,0) [0|65535] "N/A"  ASDM

BO_ 1297 MB79_LLHT_6_FL: 64 FSRL
 SG_ LLHT_Data_6_payload_192_FL : 7|16@0+ (1,0) [0|65535] "N/A"  ASDM
 SG_ LLHT_Data_6_payload_193_FL : 23|16@0+ (1,0) [0|65535] "N/A"  ASDM
 SG_ LLHT_Data_6_payload_194_FL : 39|16@0+ (1,0) [0|65535] "N/A"  ASDM
 SG_ LLHT_Data_6_payload_195_FL : 55|16@0+ (1,0) [0|65535] "N/A"  ASDM
 SG_ LLHT_Data_6_payload_196_FL : 71|16@0+ (1,0) [0|65535] "N/A"  ASDM
 SG_ LLHT_Data_6_payload_197_FL : 87|16@0+ (1,0) [0|65535] "N/A"  ASDM
 SG_ LLHT_Data_6_payload_198_FL : 103|16@0+ (1,0) [0|65535] "N/A"  ASDM
 SG_ LLHT_Data_6_payload_199_FL : 119|16@0+ (1,0) [0|65535] "N/A"  ASDM
 SG_ LLHT_Data_6_payload_200_FL : 135|16@0+ (1,0) [0|65535] "N/A"  ASDM
 SG_ LLHT_Data_6_payload_201_FL : 151|16@0+ (1,0) [0|65535] "N/A"  ASDM
 SG_ LLHT_Data_6_payload_202_FL : 167|16@0+ (1,0) [0|65535] "N/A"  ASDM
 SG_ LLHT_Data_6_payload_203_FL : 183|16@0+ (1,0) [0|65535] "N/A"  ASDM
 SG_ LLHT_Data_6_payload_204_FL : 199|16@0+ (1,0) [0|65535] "N/A"  ASDM
 SG_ LLHT_Data_6_payload_205_FL : 215|16@0+ (1,0) [0|65535] "N/A"  ASDM
 SG_ LLHT_Data_6_payload_206_FL : 231|16@0+ (1,0) [0|65535] "N/A"  ASDM
 SG_ LLHT_Data_6_payload_207_FL : 247|16@0+ (1,0) [0|65535] "N/A"  ASDM
 SG_ LLHT_Data_6_payload_208_FL : 263|16@0+ (1,0) [0|65535] "N/A"  ASDM
 SG_ LLHT_Data_6_payload_209_FL : 279|16@0+ (1,0) [0|65535] "N/A"  ASDM
 SG_ LLHT_Data_6_payload_210_FL : 295|16@0+ (1,0) [0|65535] "N/A"  ASDM
 SG_ LLHT_Data_6_payload_211_FL : 311|16@0+ (1,0) [0|65535] "N/A"  ASDM
 SG_ LLHT_Data_6_payload_212_FL : 327|16@0+ (1,0) [0|65535] "N/A"  ASDM
 SG_ LLHT_Data_6_payload_213_FL : 343|16@0+ (1,0) [0|65535] "N/A"  ASDM
 SG_ LLHT_Data_6_payload_214_FL : 359|16@0+ (1,0) [0|65535] "N/A"  ASDM
 SG_ LLHT_Data_6_payload_215_FL : 375|16@0+ (1,0) [0|65535] "N/A"  ASDM
 SG_ LLHT_Data_6_payload_216_FL : 391|16@0+ (1,0) [0|65535] "N/A"  ASDM
 SG_ LLHT_Data_6_payload_217_FL : 407|16@0+ (1,0) [0|65535] "N/A"  ASDM
 SG_ LLHT_Data_6_payload_218_FL : 423|16@0+ (1,0) [0|65535] "N/A"  ASDM
 SG_ LLHT_Data_6_payload_219_FL : 439|16@0+ (1,0) [0|65535] "N/A"  ASDM
 SG_ LLHT_Data_6_payload_220_FL : 455|16@0+ (1,0) [0|65535] "N/A"  ASDM
 SG_ LLHT_Data_6_payload_221_FL : 471|16@0+ (1,0) [0|65535] "N/A"  ASDM
 SG_ LLHT_Data_6_payload_222_FL : 487|16@0+ (1,0) [0|65535] "N/A"  ASDM
 SG_ LLHT_Data_6_payload_223_FL : 503|16@0+ (1,0) [0|65535] "N/A"  ASDM

BO_ 1298 MB79_LLHT_7_FL: 64 FSRL
 SG_ LLHT_Data_7_payload_224_FL : 7|16@0+ (1,0) [0|65535] "N/A"  ASDM
 SG_ LLHT_Data_7_payload_225_FL : 23|16@0+ (1,0) [0|65535] "N/A"  ASDM
 SG_ LLHT_Data_7_payload_226_FL : 39|16@0+ (1,0) [0|65535] "N/A"  ASDM
 SG_ LLHT_Data_7_payload_227_FL : 55|16@0+ (1,0) [0|65535] "N/A"  ASDM
 SG_ LLHT_Data_7_payload_228_FL : 71|16@0+ (1,0) [0|65535] "N/A"  ASDM
 SG_ LLHT_Data_7_payload_229_FL : 87|16@0+ (1,0) [0|65535] "N/A"  ASDM
 SG_ LLHT_Data_7_payload_230_FL : 103|16@0+ (1,0) [0|65535] "N/A"  ASDM
 SG_ LLHT_Data_7_payload_231_FL : 119|16@0+ (1,0) [0|65535] "N/A"  ASDM
 SG_ LLHT_Data_7_payload_232_FL : 135|16@0+ (1,0) [0|65535] "N/A"  ASDM
 SG_ LLHT_Data_7_payload_233_FL : 151|16@0+ (1,0) [0|65535] "N/A"  ASDM
 SG_ LLHT_Data_7_payload_234_FL : 167|16@0+ (1,0) [0|65535] "N/A"  ASDM
 SG_ LLHT_Data_7_payload_235_FL : 183|16@0+ (1,0) [0|65535] "N/A"  ASDM
 SG_ LLHT_Data_7_payload_236_FL : 199|16@0+ (1,0) [0|65535] "N/A"  ASDM
 SG_ LLHT_Data_7_payload_237_FL : 215|16@0+ (1,0) [0|65535] "N/A"  ASDM
 SG_ LLHT_Data_7_payload_238_FL : 231|16@0+ (1,0) [0|65535] "N/A"  ASDM
 SG_ LLHT_Data_7_payload_239_FL : 247|16@0+ (1,0) [0|65535] "N/A"  ASDM
 SG_ LLHT_Data_7_payload_240_FL : 263|16@0+ (1,0) [0|65535] "N/A"  ASDM
 SG_ LLHT_Data_7_payload_241_FL : 279|16@0+ (1,0) [0|65535] "N/A"  ASDM
 SG_ LLHT_Data_7_payload_242_FL : 295|16@0+ (1,0) [0|65535] "N/A"  ASDM
 SG_ LLHT_Data_7_payload_243_FL : 311|16@0+ (1,0) [0|65535] "N/A"  ASDM
 SG_ LLHT_Data_7_payload_244_FL : 327|16@0+ (1,0) [0|65535] "N/A"  ASDM
 SG_ LLHT_Data_7_payload_245_FL : 343|16@0+ (1,0) [0|65535] "N/A"  ASDM
 SG_ LLHT_Data_7_payload_246_FL : 359|16@0+ (1,0) [0|65535] "N/A"  ASDM
 SG_ LLHT_Data_7_payload_247_FL : 375|16@0+ (1,0) [0|65535] "N/A"  ASDM
 SG_ LLHT_Data_7_payload_248_FL : 391|16@0+ (1,0) [0|65535] "N/A"  ASDM
 SG_ LLHT_Data_7_payload_249_FL : 407|16@0+ (1,0) [0|65535] "N/A"  ASDM
 SG_ LLHT_Data_7_payload_250_FL : 423|16@0+ (1,0) [0|65535] "N/A"  ASDM
 SG_ LLHT_Data_7_payload_251_FL : 439|16@0+ (1,0) [0|65535] "N/A"  ASDM
 SG_ LLHT_Data_7_payload_252_FL : 455|16@0+ (1,0) [0|65535] "N/A"  ASDM
 SG_ LLHT_Data_7_payload_253_FL : 471|16@0+ (1,0) [0|65535] "N/A"  ASDM
 SG_ LLHT_Data_7_payload_254_FL : 487|16@0+ (1,0) [0|65535] "N/A"  ASDM
 SG_ LLHT_Data_7_payload_255_FL : 503|16@0+ (1,0) [0|65535] "N/A"  ASDM

BO_ 1299 MB79_LLHT_8_FL: 64 FSRL
 SG_ LLHT_Data_8_payload_256_FL : 7|16@0+ (1,0) [0|65535] "N/A"  ASDM
 SG_ LLHT_Data_8_payload_257_FL : 23|16@0+ (1,0) [0|65535] "N/A"  ASDM
 SG_ LLHT_Data_8_payload_258_FL : 39|16@0+ (1,0) [0|65535] "N/A"  ASDM
 SG_ LLHT_Data_8_payload_259_FL : 55|16@0+ (1,0) [0|65535] "N/A"  ASDM
 SG_ LLHT_Data_8_payload_260_FL : 71|16@0+ (1,0) [0|65535] "N/A"  ASDM
 SG_ LLHT_Data_8_payload_261_FL : 87|16@0+ (1,0) [0|65535] "N/A"  ASDM
 SG_ LLHT_Data_8_payload_262_FL : 103|16@0+ (1,0) [0|65535] "N/A"  ASDM
 SG_ LLHT_Data_8_payload_263_FL : 119|16@0+ (1,0) [0|65535] "N/A"  ASDM
 SG_ LLHT_Data_8_payload_264_FL : 135|16@0+ (1,0) [0|65535] "N/A"  ASDM
 SG_ LLHT_Data_8_payload_265_FL : 151|16@0+ (1,0) [0|65535] "N/A"  ASDM
 SG_ LLHT_Data_8_payload_266_FL : 167|16@0+ (1,0) [0|65535] "N/A"  ASDM
 SG_ LLHT_Data_8_payload_267_FL : 183|16@0+ (1,0) [0|65535] "N/A"  ASDM
 SG_ LLHT_Data_8_payload_268_FL : 199|16@0+ (1,0) [0|65535] "N/A"  ASDM
 SG_ LLHT_Data_8_payload_269_FL : 215|16@0+ (1,0) [0|65535] "N/A"  ASDM
 SG_ LLHT_Data_8_payload_270_FL : 231|16@0+ (1,0) [0|65535] "N/A"  ASDM
 SG_ LLHT_Data_8_payload_271_FL : 247|16@0+ (1,0) [0|65535] "N/A"  ASDM
 SG_ LLHT_Data_8_payload_272_FL : 263|16@0+ (1,0) [0|65535] "N/A"  ASDM
 SG_ LLHT_Data_8_payload_273_FL : 279|16@0+ (1,0) [0|65535] "N/A"  ASDM
 SG_ LLHT_Data_8_payload_274_FL : 295|16@0+ (1,0) [0|65535] "N/A"  ASDM
 SG_ LLHT_Data_8_payload_275_FL : 311|16@0+ (1,0) [0|65535] "N/A"  ASDM
 SG_ LLHT_Data_8_payload_276_FL : 327|16@0+ (1,0) [0|65535] "N/A"  ASDM
 SG_ LLHT_Data_8_payload_277_FL : 343|16@0+ (1,0) [0|65535] "N/A"  ASDM
 SG_ LLHT_Data_8_payload_278_FL : 359|16@0+ (1,0) [0|65535] "N/A"  ASDM
 SG_ LLHT_Data_8_payload_279_FL : 375|16@0+ (1,0) [0|65535] "N/A"  ASDM
 SG_ LLHT_Data_8_payload_280_FL : 391|16@0+ (1,0) [0|65535] "N/A"  ASDM
 SG_ LLHT_Data_8_payload_281_FL : 407|16@0+ (1,0) [0|65535] "N/A"  ASDM
 SG_ LLHT_Data_8_payload_282_FL : 423|16@0+ (1,0) [0|65535] "N/A"  ASDM
 SG_ LLHT_Data_8_payload_283_FL : 439|16@0+ (1,0) [0|65535] "N/A"  ASDM
 SG_ LLHT_Data_8_payload_284_FL : 455|16@0+ (1,0) [0|65535] "N/A"  ASDM
 SG_ LLHT_Data_8_payload_285_FL : 471|16@0+ (1,0) [0|65535] "N/A"  ASDM
 SG_ LLHT_Data_8_payload_286_FL : 487|16@0+ (1,0) [0|65535] "N/A"  ASDM
 SG_ LLHT_Data_8_payload_287_FL : 503|16@0+ (1,0) [0|65535] "N/A"  ASDM

BO_ 1300 MB79_LLHT_9_FL: 64 FSRL
 SG_ LLHT_Data_9_payload_288_FL : 7|16@0+ (1,0) [0|65535] "N/A"  ASDM
 SG_ LLHT_Data_9_payload_289_FL : 23|16@0+ (1,0) [0|65535] "N/A"  ASDM
 SG_ LLHT_Data_9_payload_290_FL : 39|16@0+ (1,0) [0|65535] "N/A"  ASDM
 SG_ LLHT_Data_9_payload_291_FL : 55|16@0+ (1,0) [0|65535] "N/A"  ASDM
 SG_ LLHT_Data_9_payload_292_FL : 71|16@0+ (1,0) [0|65535] "N/A"  ASDM
 SG_ LLHT_Data_9_payload_293_FL : 87|16@0+ (1,0) [0|65535] "N/A"  ASDM
 SG_ LLHT_Data_9_payload_294_FL : 103|16@0+ (1,0) [0|65535] "N/A"  ASDM
 SG_ LLHT_Data_9_payload_295_FL : 119|16@0+ (1,0) [0|65535] "N/A"  ASDM
 SG_ LLHT_Data_9_payload_296_FL : 135|16@0+ (1,0) [0|65535] "N/A"  ASDM
 SG_ LLHT_Data_9_payload_297_FL : 151|16@0+ (1,0) [0|65535] "N/A"  ASDM
 SG_ LLHT_Data_9_payload_298_FL : 167|16@0+ (1,0) [0|65535] "N/A"  ASDM
 SG_ LLHT_Data_9_payload_299_FL : 183|16@0+ (1,0) [0|65535] "N/A"  ASDM
 SG_ LLHT_Data_9_payload_300_FL : 199|16@0+ (1,0) [0|65535] "N/A"  ASDM
 SG_ LLHT_Data_9_payload_301_FL : 215|16@0+ (1,0) [0|65535] "N/A"  ASDM
 SG_ LLHT_Data_9_payload_302_FL : 231|16@0+ (1,0) [0|65535] "N/A"  ASDM
 SG_ LLHT_Data_9_payload_303_FL : 247|16@0+ (1,0) [0|65535] "N/A"  ASDM
 SG_ LLHT_Data_9_payload_304_FL : 263|16@0+ (1,0) [0|65535] "N/A"  ASDM
 SG_ LLHT_Data_9_payload_305_FL : 279|16@0+ (1,0) [0|65535] "N/A"  ASDM
 SG_ LLHT_Data_9_payload_306_FL : 295|16@0+ (1,0) [0|65535] "N/A"  ASDM
 SG_ LLHT_Data_9_payload_307_FL : 311|16@0+ (1,0) [0|65535] "N/A"  ASDM
 SG_ LLHT_Data_9_payload_308_FL : 327|16@0+ (1,0) [0|65535] "N/A"  ASDM
 SG_ LLHT_Data_9_payload_309_FL : 343|16@0+ (1,0) [0|65535] "N/A"  ASDM
 SG_ LLHT_Data_9_payload_310_FL : 359|16@0+ (1,0) [0|65535] "N/A"  ASDM
 SG_ LLHT_Data_9_payload_311_FL : 375|16@0+ (1,0) [0|65535] "N/A"  ASDM
 SG_ LLHT_Data_9_payload_312_FL : 391|16@0+ (1,0) [0|65535] "N/A"  ASDM
 SG_ LLHT_Data_9_payload_313_FL : 407|16@0+ (1,0) [0|65535] "N/A"  ASDM
 SG_ LLHT_Data_9_payload_314_FL : 423|16@0+ (1,0) [0|65535] "N/A"  ASDM
 SG_ LLHT_Data_9_payload_315_FL : 439|16@0+ (1,0) [0|65535] "N/A"  ASDM
 SG_ LLHT_Data_9_payload_316_FL : 455|16@0+ (1,0) [0|65535] "N/A"  ASDM
 SG_ LLHT_Data_9_payload_317_FL : 471|16@0+ (1,0) [0|65535] "N/A"  ASDM
 SG_ LLHT_Data_9_payload_318_FL : 487|16@0+ (1,0) [0|65535] "N/A"  ASDM
 SG_ LLHT_Data_9_payload_319_FL : 503|16@0+ (1,0) [0|65535] "N/A"  ASDM

BO_ 1301 MB79_LLHT_10_FL: 64 FSRL
 SG_ LLHT_Data_10_payload_320_FL : 7|16@0+ (1,0) [0|65535] "N/A"  ASDM
 SG_ LLHT_Data_10_payload_321_FL : 23|16@0+ (1,0) [0|65535] "N/A"  ASDM
 SG_ LLHT_Data_10_payload_322_FL : 39|16@0+ (1,0) [0|65535] "N/A"  ASDM
 SG_ LLHT_Data_10_payload_323_FL : 55|16@0+ (1,0) [0|65535] "N/A"  ASDM
 SG_ LLHT_Data_10_payload_324_FL : 71|16@0+ (1,0) [0|65535] "N/A"  ASDM
 SG_ LLHT_Data_10_payload_325_FL : 87|16@0+ (1,0) [0|65535] "N/A"  ASDM
 SG_ LLHT_Data_10_payload_326_FL : 103|16@0+ (1,0) [0|65535] "N/A"  ASDM
 SG_ LLHT_Data_10_payload_327_FL : 119|16@0+ (1,0) [0|65535] "N/A"  ASDM
 SG_ LLHT_Data_10_payload_328_FL : 135|16@0+ (1,0) [0|65535] "N/A"  ASDM
 SG_ LLHT_Data_10_payload_329_FL : 151|16@0+ (1,0) [0|65535] "N/A"  ASDM
 SG_ LLHT_Data_10_payload_330_FL : 167|16@0+ (1,0) [0|65535] "N/A"  ASDM
 SG_ LLHT_Data_10_payload_331_FL : 183|16@0+ (1,0) [0|65535] "N/A"  ASDM
 SG_ LLHT_Data_10_payload_332_FL : 199|16@0+ (1,0) [0|65535] "N/A"  ASDM
 SG_ LLHT_Data_10_payload_333_FL : 215|16@0+ (1,0) [0|65535] "N/A"  ASDM
 SG_ LLHT_Data_10_payload_334_FL : 231|16@0+ (1,0) [0|65535] "N/A"  ASDM
 SG_ LLHT_Data_10_payload_335_FL : 247|16@0+ (1,0) [0|65535] "N/A"  ASDM
 SG_ LLHT_Data_10_payload_336_FL : 263|16@0+ (1,0) [0|65535] "N/A"  ASDM
 SG_ LLHT_Data_10_payload_337_FL : 279|16@0+ (1,0) [0|65535] "N/A"  ASDM
 SG_ LLHT_Data_10_payload_338_FL : 295|16@0+ (1,0) [0|65535] "N/A"  ASDM
 SG_ LLHT_Data_10_payload_339_FL : 311|16@0+ (1,0) [0|65535] "N/A"  ASDM
 SG_ LLHT_Data_10_payload_340_FL : 327|16@0+ (1,0) [0|65535] "N/A"  ASDM
 SG_ LLHT_Data_10_payload_341_FL : 343|16@0+ (1,0) [0|65535] "N/A"  ASDM
 SG_ LLHT_Data_10_payload_342_FL : 359|16@0+ (1,0) [0|65535] "N/A"  ASDM
 SG_ LLHT_Data_10_payload_343_FL : 375|16@0+ (1,0) [0|65535] "N/A"  ASDM
 SG_ LLHT_Data_10_payload_344_FL : 391|16@0+ (1,0) [0|65535] "N/A"  ASDM
 SG_ LLHT_Data_10_payload_345_FL : 407|16@0+ (1,0) [0|65535] "N/A"  ASDM
 SG_ LLHT_Data_10_payload_346_FL : 423|16@0+ (1,0) [0|65535] "N/A"  ASDM
 SG_ LLHT_Data_10_payload_347_FL : 439|16@0+ (1,0) [0|65535] "N/A"  ASDM
 SG_ LLHT_Data_10_payload_348_FL : 455|16@0+ (1,0) [0|65535] "N/A"  ASDM
 SG_ LLHT_Data_10_payload_349_FL : 471|16@0+ (1,0) [0|65535] "N/A"  ASDM
 SG_ LLHT_Data_10_payload_350_FL : 487|16@0+ (1,0) [0|65535] "N/A"  ASDM
 SG_ LLHT_Data_10_payload_351_FL : 503|16@0+ (1,0) [0|65535] "N/A"  ASDM

BO_ 1302 MB79_LLHT_11_FL: 64 FSRL
 SG_ LLHT_Data_11_payload_352_FL : 7|16@0+ (1,0) [0|65535] "N/A"  ASDM
 SG_ LLHT_Data_11_payload_353_FL : 23|16@0+ (1,0) [0|65535] "N/A"  ASDM
 SG_ LLHT_Data_11_payload_354_FL : 39|16@0+ (1,0) [0|65535] "N/A"  ASDM
 SG_ LLHT_Data_11_payload_355_FL : 55|16@0+ (1,0) [0|65535] "N/A"  ASDM
 SG_ LLHT_Data_11_payload_356_FL : 71|16@0+ (1,0) [0|65535] "N/A"  ASDM
 SG_ LLHT_Data_11_payload_357_FL : 87|16@0+ (1,0) [0|65535] "N/A"  ASDM
 SG_ LLHT_Data_11_payload_358_FL : 103|16@0+ (1,0) [0|65535] "N/A"  ASDM
 SG_ LLHT_Data_11_payload_359_FL : 119|16@0+ (1,0) [0|65535] "N/A"  ASDM
 SG_ LLHT_Data_11_payload_360_FL : 135|16@0+ (1,0) [0|65535] "N/A"  ASDM
 SG_ LLHT_Data_11_payload_361_FL : 151|16@0+ (1,0) [0|65535] "N/A"  ASDM
 SG_ LLHT_Data_11_payload_362_FL : 167|16@0+ (1,0) [0|65535] "N/A"  ASDM
 SG_ LLHT_Data_11_payload_363_FL : 183|16@0+ (1,0) [0|65535] "N/A"  ASDM
 SG_ LLHT_Data_11_payload_364_FL : 199|16@0+ (1,0) [0|65535] "N/A"  ASDM
 SG_ LLHT_Data_11_payload_365_FL : 215|16@0+ (1,0) [0|65535] "N/A"  ASDM
 SG_ LLHT_Data_11_payload_366_FL : 231|16@0+ (1,0) [0|65535] "N/A"  ASDM
 SG_ LLHT_Data_11_payload_367_FL : 247|16@0+ (1,0) [0|65535] "N/A"  ASDM
 SG_ LLHT_Data_11_payload_368_FL : 263|16@0+ (1,0) [0|65535] "N/A"  ASDM
 SG_ LLHT_Data_11_payload_369_FL : 279|16@0+ (1,0) [0|65535] "N/A"  ASDM
 SG_ LLHT_Data_11_payload_370_FL : 295|16@0+ (1,0) [0|65535] "N/A"  ASDM
 SG_ LLHT_Data_11_payload_371_FL : 311|16@0+ (1,0) [0|65535] "N/A"  ASDM
 SG_ LLHT_Data_11_payload_372_FL : 327|16@0+ (1,0) [0|65535] "N/A"  ASDM
 SG_ LLHT_Data_11_payload_373_FL : 343|16@0+ (1,0) [0|65535] "N/A"  ASDM
 SG_ LLHT_Data_11_payload_374_FL : 359|16@0+ (1,0) [0|65535] "N/A"  ASDM
 SG_ LLHT_Data_11_payload_375_FL : 375|16@0+ (1,0) [0|65535] "N/A"  ASDM
 SG_ LLHT_Data_11_payload_376_FL : 391|16@0+ (1,0) [0|65535] "N/A"  ASDM
 SG_ LLHT_Data_11_payload_377_FL : 407|16@0+ (1,0) [0|65535] "N/A"  ASDM
 SG_ LLHT_Data_11_payload_378_FL : 423|16@0+ (1,0) [0|65535] "N/A"  ASDM
 SG_ LLHT_Data_11_payload_379_FL : 439|16@0+ (1,0) [0|65535] "N/A"  ASDM
 SG_ LLHT_Data_11_payload_380_FL : 455|16@0+ (1,0) [0|65535] "N/A"  ASDM
 SG_ LLHT_Data_11_payload_381_FL : 471|16@0+ (1,0) [0|65535] "N/A"  ASDM
 SG_ LLHT_Data_11_payload_382_FL : 487|16@0+ (1,0) [0|65535] "N/A"  ASDM
 SG_ LLHT_Data_11_payload_383_FL : 503|16@0+ (1,0) [0|65535] "N/A"  ASDM

BO_ 1303 MB79_LLHT_12_FL: 64 FSRL
 SG_ LLHT_Data_12_payload_384_FL : 7|16@0+ (1,0) [0|65535] "N/A"  ASDM
 SG_ LLHT_Data_12_payload_385_FL : 23|16@0+ (1,0) [0|65535] "N/A"  ASDM
 SG_ LLHT_Data_12_payload_386_FL : 39|16@0+ (1,0) [0|65535] "N/A"  ASDM
 SG_ LLHT_Data_12_payload_387_FL : 55|16@0+ (1,0) [0|65535] "N/A"  ASDM
 SG_ LLHT_Data_12_payload_388_FL : 71|16@0+ (1,0) [0|65535] "N/A"  ASDM
 SG_ LLHT_Data_12_payload_389_FL : 87|16@0+ (1,0) [0|65535] "N/A"  ASDM
 SG_ LLHT_Data_12_payload_390_FL : 103|16@0+ (1,0) [0|65535] "N/A"  ASDM
 SG_ LLHT_Data_12_payload_391_FL : 119|16@0+ (1,0) [0|65535] "N/A"  ASDM
 SG_ LLHT_Data_12_payload_392_FL : 135|16@0+ (1,0) [0|65535] "N/A"  ASDM
 SG_ LLHT_Data_12_payload_393_FL : 151|16@0+ (1,0) [0|65535] "N/A"  ASDM
 SG_ LLHT_Data_12_payload_394_FL : 167|16@0+ (1,0) [0|65535] "N/A"  ASDM
 SG_ LLHT_Data_12_payload_395_FL : 183|16@0+ (1,0) [0|65535] "N/A"  ASDM
 SG_ LLHT_Data_12_payload_396_FL : 199|16@0+ (1,0) [0|65535] "N/A"  ASDM
 SG_ LLHT_Data_12_payload_397_FL : 215|16@0+ (1,0) [0|65535] "N/A"  ASDM
 SG_ LLHT_Data_12_payload_398_FL : 231|16@0+ (1,0) [0|65535] "N/A"  ASDM
 SG_ LLHT_Data_12_payload_399_FL : 247|16@0+ (1,0) [0|65535] "N/A"  ASDM
 SG_ LLHT_Data_12_payload_400_FL : 263|16@0+ (1,0) [0|65535] "N/A"  ASDM
 SG_ LLHT_Data_12_payload_401_FL : 279|16@0+ (1,0) [0|65535] "N/A"  ASDM
 SG_ LLHT_Data_12_payload_402_FL : 295|16@0+ (1,0) [0|65535] "N/A"  ASDM
 SG_ LLHT_Data_12_payload_403_FL : 311|16@0+ (1,0) [0|65535] "N/A"  ASDM
 SG_ LLHT_Data_12_payload_404_FL : 327|16@0+ (1,0) [0|65535] "N/A"  ASDM
 SG_ LLHT_Data_12_payload_405_FL : 343|16@0+ (1,0) [0|65535] "N/A"  ASDM
 SG_ LLHT_Data_12_payload_406_FL : 359|16@0+ (1,0) [0|65535] "N/A"  ASDM
 SG_ LLHT_Data_12_payload_407_FL : 375|16@0+ (1,0) [0|65535] "N/A"  ASDM
 SG_ LLHT_Data_12_payload_408_FL : 391|16@0+ (1,0) [0|65535] "N/A"  ASDM
 SG_ LLHT_Data_12_payload_409_FL : 407|16@0+ (1,0) [0|65535] "N/A"  ASDM
 SG_ LLHT_Data_12_payload_410_FL : 423|16@0+ (1,0) [0|65535] "N/A"  ASDM
 SG_ LLHT_Data_12_payload_411_FL : 439|16@0+ (1,0) [0|65535] "N/A"  ASDM
 SG_ LLHT_Data_12_payload_412_FL : 455|16@0+ (1,0) [0|65535] "N/A"  ASDM
 SG_ LLHT_Data_12_payload_413_FL : 471|16@0+ (1,0) [0|65535] "N/A"  ASDM
 SG_ LLHT_Data_12_payload_414_FL : 487|16@0+ (1,0) [0|65535] "N/A"  ASDM
 SG_ LLHT_Data_12_payload_415_FL : 503|16@0+ (1,0) [0|65535] "N/A"  ASDM

BO_ 1304 MB79_LLHT_13_FL: 64 FSRL
 SG_ LLHT_Data_13_payload_416_FL : 7|16@0+ (1,0) [0|65535] "N/A"  ASDM
 SG_ LLHT_Data_13_payload_417_FL : 23|16@0+ (1,0) [0|65535] "N/A"  ASDM
 SG_ LLHT_Data_13_payload_418_FL : 39|16@0+ (1,0) [0|65535] "N/A"  ASDM
 SG_ LLHT_Data_13_payload_419_FL : 55|16@0+ (1,0) [0|65535] "N/A"  ASDM
 SG_ LLHT_Data_13_payload_420_FL : 71|16@0+ (1,0) [0|65535] "N/A"  ASDM
 SG_ LLHT_Data_13_payload_421_FL : 87|16@0+ (1,0) [0|65535] "N/A"  ASDM
 SG_ LLHT_Data_13_payload_422_FL : 103|16@0+ (1,0) [0|65535] "N/A"  ASDM
 SG_ LLHT_Data_13_payload_423_FL : 119|16@0+ (1,0) [0|65535] "N/A"  ASDM
 SG_ LLHT_Data_13_payload_424_FL : 135|16@0+ (1,0) [0|65535] "N/A"  ASDM
 SG_ LLHT_Data_13_payload_425_FL : 151|16@0+ (1,0) [0|65535] "N/A"  ASDM
 SG_ LLHT_Data_13_payload_426_FL : 167|16@0+ (1,0) [0|65535] "N/A"  ASDM
 SG_ LLHT_Data_13_payload_427_FL : 183|16@0+ (1,0) [0|65535] "N/A"  ASDM
 SG_ LLHT_Data_13_payload_428_FL : 199|16@0+ (1,0) [0|65535] "N/A"  ASDM
 SG_ LLHT_Data_13_payload_429_FL : 215|16@0+ (1,0) [0|65535] "N/A"  ASDM
 SG_ LLHT_Data_13_payload_430_FL : 231|16@0+ (1,0) [0|65535] "N/A"  ASDM
 SG_ LLHT_Data_13_payload_431_FL : 247|16@0+ (1,0) [0|65535] "N/A"  ASDM
 SG_ LLHT_Data_13_payload_432_FL : 263|16@0+ (1,0) [0|65535] "N/A"  ASDM
 SG_ LLHT_Data_13_payload_433_FL : 279|16@0+ (1,0) [0|65535] "N/A"  ASDM
 SG_ LLHT_Data_13_payload_434_FL : 295|16@0+ (1,0) [0|65535] "N/A"  ASDM
 SG_ LLHT_Data_13_payload_435_FL : 311|16@0+ (1,0) [0|65535] "N/A"  ASDM
 SG_ LLHT_Data_13_payload_436_FL : 327|16@0+ (1,0) [0|65535] "N/A"  ASDM
 SG_ LLHT_Data_13_payload_437_FL : 343|16@0+ (1,0) [0|65535] "N/A"  ASDM
 SG_ LLHT_Data_13_payload_438_FL : 359|16@0+ (1,0) [0|65535] "N/A"  ASDM
 SG_ LLHT_Data_13_payload_439_FL : 375|16@0+ (1,0) [0|65535] "N/A"  ASDM
 SG_ LLHT_Data_13_payload_440_FL : 391|16@0+ (1,0) [0|65535] "N/A"  ASDM
 SG_ LLHT_Data_13_payload_441_FL : 407|16@0+ (1,0) [0|65535] "N/A"  ASDM
 SG_ LLHT_Data_13_payload_442_FL : 423|16@0+ (1,0) [0|65535] "N/A"  ASDM
 SG_ LLHT_Data_13_payload_443_FL : 439|16@0+ (1,0) [0|65535] "N/A"  ASDM
 SG_ LLHT_Data_13_payload_444_FL : 455|16@0+ (1,0) [0|65535] "N/A"  ASDM
 SG_ LLHT_Data_13_payload_445_FL : 471|16@0+ (1,0) [0|65535] "N/A"  ASDM
 SG_ LLHT_Data_13_payload_446_FL : 487|16@0+ (1,0) [0|65535] "N/A"  ASDM
 SG_ LLHT_Data_13_payload_447_FL : 503|16@0+ (1,0) [0|65535] "N/A"  ASDM

BO_ 1305 MB79_LLHT_14_FL: 64 FSRL
 SG_ LLHT_Data_14_payload_448_FL : 7|16@0+ (1,0) [0|65535] "N/A"  ASDM
 SG_ LLHT_Data_14_payload_449_FL : 23|16@0+ (1,0) [0|65535] "N/A"  ASDM
 SG_ LLHT_Data_14_payload_450_FL : 39|16@0+ (1,0) [0|65535] "N/A"  ASDM
 SG_ LLHT_Data_14_payload_451_FL : 55|16@0+ (1,0) [0|65535] "N/A"  ASDM
 SG_ LLHT_Data_14_payload_452_FL : 71|16@0+ (1,0) [0|65535] "N/A"  ASDM
 SG_ LLHT_Data_14_payload_453_FL : 87|16@0+ (1,0) [0|65535] "N/A"  ASDM
 SG_ LLHT_Data_14_payload_454_FL : 103|16@0+ (1,0) [0|65535] "N/A"  ASDM
 SG_ LLHT_Data_14_payload_455_FL : 119|16@0+ (1,0) [0|65535] "N/A"  ASDM
 SG_ LLHT_Data_14_payload_456_FL : 135|16@0+ (1,0) [0|65535] "N/A"  ASDM
 SG_ LLHT_Data_14_payload_457_FL : 151|16@0+ (1,0) [0|65535] "N/A"  ASDM
 SG_ LLHT_Data_14_payload_458_FL : 167|16@0+ (1,0) [0|65535] "N/A"  ASDM
 SG_ LLHT_Data_14_payload_459_FL : 183|16@0+ (1,0) [0|65535] "N/A"  ASDM
 SG_ LLHT_Data_14_payload_460_FL : 199|16@0+ (1,0) [0|65535] "N/A"  ASDM
 SG_ LLHT_Data_14_payload_461_FL : 215|16@0+ (1,0) [0|65535] "N/A"  ASDM
 SG_ LLHT_Data_14_payload_462_FL : 231|16@0+ (1,0) [0|65535] "N/A"  ASDM
 SG_ LLHT_Data_14_payload_463_FL : 247|16@0+ (1,0) [0|65535] "N/A"  ASDM
 SG_ LLHT_Data_14_payload_464_FL : 263|16@0+ (1,0) [0|65535] "N/A"  ASDM
 SG_ LLHT_Data_14_payload_465_FL : 279|16@0+ (1,0) [0|65535] "N/A"  ASDM
 SG_ LLHT_Data_14_payload_466_FL : 295|16@0+ (1,0) [0|65535] "N/A"  ASDM
 SG_ LLHT_Data_14_payload_467_FL : 311|16@0+ (1,0) [0|65535] "N/A"  ASDM
 SG_ LLHT_Data_14_payload_468_FL : 327|16@0+ (1,0) [0|65535] "N/A"  ASDM
 SG_ LLHT_Data_14_payload_469_FL : 343|16@0+ (1,0) [0|65535] "N/A"  ASDM
 SG_ LLHT_Data_14_payload_470_FL : 359|16@0+ (1,0) [0|65535] "N/A"  ASDM
 SG_ LLHT_Data_14_payload_471_FL : 375|16@0+ (1,0) [0|65535] "N/A"  ASDM
 SG_ LLHT_Data_14_payload_472_FL : 391|16@0+ (1,0) [0|65535] "N/A"  ASDM
 SG_ LLHT_Data_14_payload_473_FL : 407|16@0+ (1,0) [0|65535] "N/A"  ASDM
 SG_ LLHT_Data_14_payload_474_FL : 423|16@0+ (1,0) [0|65535] "N/A"  ASDM
 SG_ LLHT_Data_14_payload_475_FL : 439|16@0+ (1,0) [0|65535] "N/A"  ASDM
 SG_ LLHT_Data_14_payload_476_FL : 455|16@0+ (1,0) [0|65535] "N/A"  ASDM
 SG_ LLHT_Data_14_payload_477_FL : 471|16@0+ (1,0) [0|65535] "N/A"  ASDM
 SG_ LLHT_Data_14_payload_478_FL : 487|16@0+ (1,0) [0|65535] "N/A"  ASDM
 SG_ LLHT_Data_14_payload_479_FL : 503|16@0+ (1,0) [0|65535] "N/A"  ASDM

BO_ 1306 MB79_LLHT_15_FL: 64 FSRL
 SG_ LLHT_Data_15_payload_480_FL : 7|16@0+ (1,0) [0|65535] "N/A"  ASDM
 SG_ LLHT_Data_15_payload_481_FL : 23|16@0+ (1,0) [0|65535] "N/A"  ASDM
 SG_ LLHT_Data_15_payload_482_FL : 39|16@0+ (1,0) [0|65535] "N/A"  ASDM
 SG_ LLHT_Data_15_payload_483_FL : 55|16@0+ (1,0) [0|65535] "N/A"  ASDM
 SG_ LLHT_Data_15_payload_484_FL : 71|16@0+ (1,0) [0|65535] "N/A"  ASDM
 SG_ LLHT_Data_15_payload_485_FL : 87|16@0+ (1,0) [0|65535] "N/A"  ASDM
 SG_ LLHT_Data_15_payload_486_FL : 103|16@0+ (1,0) [0|65535] "N/A"  ASDM
 SG_ LLHT_Data_15_payload_487_FL : 119|16@0+ (1,0) [0|65535] "N/A"  ASDM
 SG_ LLHT_Data_15_payload_488_FL : 135|16@0+ (1,0) [0|65535] "N/A"  ASDM
 SG_ LLHT_Data_15_payload_489_FL : 151|16@0+ (1,0) [0|65535] "N/A"  ASDM
 SG_ LLHT_Data_15_payload_490_FL : 167|16@0+ (1,0) [0|65535] "N/A"  ASDM
 SG_ LLHT_Data_15_payload_491_FL : 183|16@0+ (1,0) [0|65535] "N/A"  ASDM
 SG_ LLHT_Data_15_payload_492_FL : 199|16@0+ (1,0) [0|65535] "N/A"  ASDM
 SG_ LLHT_Data_15_payload_493_FL : 215|16@0+ (1,0) [0|65535] "N/A"  ASDM
 SG_ LLHT_Data_15_payload_494_FL : 231|16@0+ (1,0) [0|65535] "N/A"  ASDM
 SG_ LLHT_Data_15_payload_495_FL : 247|16@0+ (1,0) [0|65535] "N/A"  ASDM
 SG_ LLHT_Data_15_payload_496_FL : 263|16@0+ (1,0) [0|65535] "N/A"  ASDM
 SG_ LLHT_Data_15_payload_497_FL : 279|16@0+ (1,0) [0|65535] "N/A"  ASDM
 SG_ LLHT_Data_15_payload_498_FL : 295|16@0+ (1,0) [0|65535] "N/A"  ASDM
 SG_ LLHT_Data_15_payload_499_FL : 311|16@0+ (1,0) [0|65535] "N/A"  ASDM
 SG_ LLHT_Data_15_payload_500_FL : 327|16@0+ (1,0) [0|65535] "N/A"  ASDM
 SG_ LLHT_Data_15_payload_501_FL : 343|16@0+ (1,0) [0|65535] "N/A"  ASDM
 SG_ LLHT_Data_15_payload_502_FL : 359|16@0+ (1,0) [0|65535] "N/A"  ASDM
 SG_ LLHT_Data_15_payload_503_FL : 375|16@0+ (1,0) [0|65535] "N/A"  ASDM
 SG_ LLHT_Data_15_payload_504_FL : 391|16@0+ (1,0) [0|65535] "N/A"  ASDM
 SG_ LLHT_Data_15_payload_505_FL : 407|16@0+ (1,0) [0|65535] "N/A"  ASDM
 SG_ LLHT_Data_15_payload_506_FL : 423|16@0+ (1,0) [0|65535] "N/A"  ASDM
 SG_ LLHT_Data_15_payload_507_FL : 439|16@0+ (1,0) [0|65535] "N/A"  ASDM
 SG_ LLHT_Data_15_payload_508_FL : 455|16@0+ (1,0) [0|65535] "N/A"  ASDM
 SG_ LLHT_Data_15_payload_509_FL : 471|16@0+ (1,0) [0|65535] "N/A"  ASDM
 SG_ LLHT_Data_15_payload_510_FL : 487|16@0+ (1,0) [0|65535] "N/A"  ASDM
 SG_ LLHT_Data_15_payload_511_FL : 503|16@0+ (1,0) [0|65535] "N/A"  ASDM

BO_ 1307 MB79_ASC_CORRECTION_0_FL: 64 FSRL
 SG_ ASC_Azimuth_Correction_0_FL : 0|16@1- (0.01,0) [-20|20] "degree"  ASDM
 SG_ ASC_Azimuth_Correction_1_FL : 16|16@1- (0.01,0) [-20|20] "degree"  ASDM
 SG_ ASC_Azimuth_Correction_2_FL : 32|16@1- (0.01,0) [-20|20] "degree"  ASDM
 SG_ ASC_Azimuth_Correction_3_FL : 48|16@1- (0.01,0) [-20|20] "degree"  ASDM
 SG_ ASC_Azimuth_Correction_4_FL : 64|16@1- (0.01,0) [-20|20] "degree"  ASDM
 SG_ ASC_Azimuth_Correction_5_FL : 80|16@1- (0.01,0) [-20|20] "degree"  ASDM
 SG_ ASC_Azimuth_Correction_6_FL : 96|16@1- (0.01,0) [-20|20] "degree"  ASDM
 SG_ ASC_Azimuth_Correction_7_FL : 112|16@1- (0.01,0) [-20|20] "degree"  ASDM
 SG_ ASC_Azimuth_Correction_8_FL : 128|16@1- (0.01,0) [-20|20] "degree"  ASDM
 SG_ ASC_Azimuth_Correction_9_FL : 144|16@1- (0.01,0) [-20|20] "degree"  ASDM
 SG_ ASC_Azimuth_Correction_10_FL : 160|16@1- (0.01,0) [-20|20] "degree"  ASDM
 SG_ ASC_Azimuth_Correction_11_FL : 176|16@1- (0.01,0) [-20|20] "degree"  ASDM
 SG_ ASC_Azimuth_Correction_12_FL : 192|16@1- (0.01,0) [-20|20] "degree"  ASDM
 SG_ ASC_Azimuth_Correction_13_FL : 208|16@1- (0.01,0) [-20|20] "degree"  ASDM
 SG_ ASC_Azimuth_Correction_14_FL : 224|16@1- (0.01,0) [-20|20] "degree"  ASDM
 SG_ ASC_Azimuth_Correction_15_FL : 240|16@1- (0.01,0) [-20|20] "degree"  ASDM
 SG_ ASC_Azimuth_Correction_16_FL : 256|16@1- (0.01,0) [-20|20] "degree"  ASDM
 SG_ ASC_Azimuth_Correction_17_FL : 272|16@1- (0.01,0) [-20|20] "degree"  ASDM
 SG_ ASC_Azimuth_Correction_18_FL : 288|16@1- (0.01,0) [-20|20] "degree"  ASDM
 SG_ ASC_Azimuth_Correction_19_FL : 304|16@1- (0.01,0) [-20|20] "degree"  ASDM
 SG_ ASC_Azimuth_Correction_20_FL : 320|16@1- (0.01,0) [-20|20] "degree"  ASDM
 SG_ ASC_Azimuth_Correction_21_FL : 336|16@1- (0.01,0) [-20|20] "degree"  ASDM
 SG_ ASC_Azimuth_Correction_22_FL : 352|16@1- (0.01,0) [-20|20] "degree"  ASDM
 SG_ ASC_Azimuth_Correction_23_FL : 368|16@1- (0.01,0) [-20|20] "degree"  ASDM
 SG_ ASC_Azimuth_Correction_24_FL : 384|16@1- (0.01,0) [-20|20] "degree"  ASDM
 SG_ ASC_Azimuth_Correction_25_FL : 400|16@1- (0.01,0) [-20|20] "degree"  ASDM
 SG_ ASC_Azimuth_Correction_26_FL : 416|16@1- (0.01,0) [-20|20] "degree"  ASDM
 SG_ ASC_Azimuth_Correction_27_FL : 432|16@1- (0.01,0) [-20|20] "degree"  ASDM
 SG_ ASC_Azimuth_Correction_28_FL : 448|16@1- (0.01,0) [-20|20] "degree"  ASDM
 SG_ ASC_Azimuth_Correction_29_FL : 464|16@1- (0.01,0) [-20|20] "degree"  ASDM
 SG_ ASC_Azimuth_Correction_30_FL : 480|16@1- (0.01,0) [-20|20] "degree"  ASDM
 SG_ ASC_Azimuth_Correction_31_FL : 496|16@1- (0.01,0) [-20|20] "degree"  ASDM

BO_ 1308 MB79_ASC_CORRECTION_1_FL: 64 FSRL
 SG_ ASC_Azimuth_Correction_32_FL : 0|16@1- (0.01,0) [-20|20] "degree"  ASDM
 SG_ ASC_Azimuth_Correction_33_FL : 16|16@1- (0.01,0) [-20|20] "degree"  ASDM
 SG_ ASC_Azimuth_Correction_34_FL : 32|16@1- (0.01,0) [-20|20] "degree"  ASDM
 SG_ ASC_Azimuth_Correction_35_FL : 48|16@1- (0.01,0) [-20|20] "degree"  ASDM
 SG_ ASC_Azimuth_Correction_36_FL : 64|16@1- (0.01,0) [-20|20] "degree"  ASDM
 SG_ ASC_Azimuth_Correction_37_FL : 80|16@1- (0.01,0) [-20|20] "degree"  ASDM
 SG_ ASC_Azimuth_Correction_38_FL : 96|16@1- (0.01,0) [-20|20] "degree"  ASDM
 SG_ ASC_Azimuth_Correction_39_FL : 112|16@1- (0.01,0) [-20|20] "degree"  ASDM
 SG_ ASC_Azimuth_Correction_40_FL : 128|16@1- (0.01,0) [-20|20] "degree"  ASDM
 SG_ ASC_Azimuth_Correction_41_FL : 144|16@1- (0.01,0) [-20|20] "degree"  ASDM
 SG_ ASC_Azimuth_Correction_42_FL : 160|16@1- (0.01,0) [-20|20] "degree"  ASDM
 SG_ ASC_Azimuth_Correction_43_FL : 176|16@1- (0.01,0) [-20|20] "degree"  ASDM
 SG_ ASC_Azimuth_Correction_44_FL : 192|16@1- (0.01,0) [-20|20] "degree"  ASDM
 SG_ ASC_Azimuth_Correction_45_FL : 208|16@1- (0.01,0) [-20|20] "degree"  ASDM
 SG_ ASC_Azimuth_Correction_46_FL : 224|16@1- (0.01,0) [-20|20] "degree"  ASDM
 SG_ ASC_Azimuth_Correction_47_FL : 240|16@1- (0.01,0) [-20|20] "degree"  ASDM
 SG_ ASC_Azimuth_Correction_48_FL : 256|16@1- (0.01,0) [-20|20] "degree"  ASDM
 SG_ ASC_Azimuth_Correction_49_FL : 272|16@1- (0.01,0) [-20|20] "degree"  ASDM
 SG_ ASC_Azimuth_Correction_50_FL : 288|16@1- (0.01,0) [-20|20] "degree"  ASDM
 SG_ ASC_Azimuth_Correction_51_FL : 304|16@1- (0.01,0) [-20|20] "degree"  ASDM
 SG_ ASC_Azimuth_Correction_52_FL : 320|16@1- (0.01,0) [-20|20] "degree"  ASDM
 SG_ ASC_Azimuth_Correction_53_FL : 336|16@1- (0.01,0) [-20|20] "degree"  ASDM
 SG_ ASC_Azimuth_Correction_54_FL : 352|16@1- (0.01,0) [-20|20] "degree"  ASDM
 SG_ ASC_Azimuth_Correction_55_FL : 368|16@1- (0.01,0) [-20|20] "degree"  ASDM
 SG_ ASC_Azimuth_Correction_56_FL : 384|16@1- (0.01,0) [-20|20] "degree"  ASDM
 SG_ ASC_Azimuth_Correction_57_FL : 400|16@1- (0.01,0) [-20|20] "degree"  ASDM
 SG_ ASC_Azimuth_Correction_58_FL : 416|16@1- (0.01,0) [-20|20] "degree"  ASDM
 SG_ ASC_Azimuth_Correction_59_FL : 432|16@1- (0.01,0) [-20|20] "degree"  ASDM
 SG_ ASC_Azimuth_Correction_60_FL : 448|16@1- (0.01,0) [-20|20] "degree"  ASDM
 SG_ ASC_Azimuth_Correction_61_FL : 464|16@1- (0.01,0) [-20|20] "degree"  ASDM
 SG_ ASC_Azimuth_Correction_62_FL : 480|16@1- (0.01,0) [-20|20] "degree"  ASDM
 SG_ ASC_Azimuth_Correction_63_FL : 496|16@1- (0.01,0) [-20|20] "degree"  ASDM

BO_ 1309 MB79_ASC_CORRECTION_2_FL: 64 FSRL
 SG_ ASC_Azimuth_Correction_64_FL : 0|16@1- (0.01,0) [-20|20] "degree"  ASDM
 SG_ ASC_Azimuth_Correction_65_FL : 16|16@1- (0.01,0) [-20|20] "degree"  ASDM
 SG_ ASC_Azimuth_Correction_66_FL : 32|16@1- (0.01,0) [-20|20] "degree"  ASDM
 SG_ ASC_Azimuth_Correction_67_FL : 48|16@1- (0.01,0) [-20|20] "degree"  ASDM
 SG_ ASC_Azimuth_Correction_68_FL : 64|16@1- (0.01,0) [-20|20] "degree"  ASDM
 SG_ ASC_Azimuth_Correction_69_FL : 80|16@1- (0.01,0) [-20|20] "degree"  ASDM
 SG_ ASC_Azimuth_Correction_70_FL : 96|16@1- (0.01,0) [-20|20] "degree"  ASDM
 SG_ ASC_Azimuth_Correction_71_FL : 112|16@1- (0.01,0) [-20|20] "degree"  ASDM
 SG_ ASC_Azimuth_Correction_72_FL : 128|16@1- (0.01,0) [-20|20] "degree"  ASDM
 SG_ ASC_Azimuth_Correction_73_FL : 144|16@1- (0.01,0) [-20|20] "degree"  ASDM
 SG_ ASC_Azimuth_Correction_74_FL : 160|16@1- (0.01,0) [-20|20] "degree"  ASDM
 SG_ ASC_Azimuth_Correction_75_FL : 176|16@1- (0.01,0) [-20|20] "degree"  ASDM
 SG_ ASC_Azimuth_Correction_76_FL : 192|16@1- (0.01,0) [-20|20] "degree"  ASDM
 SG_ ASC_Azimuth_Correction_77_FL : 208|16@1- (0.01,0) [-20|20] "degree"  ASDM
 SG_ ASC_Azimuth_Correction_78_FL : 224|16@1- (0.01,0) [-20|20] "degree"  ASDM
 SG_ ASC_Azimuth_Correction_79_FL : 240|16@1- (0.01,0) [-20|20] "degree"  ASDM
 SG_ ASC_Azimuth_Correction_80_FL : 256|16@1- (0.01,0) [-20|20] "degree"  ASDM
 SG_ ASC_Azimuth_Correction_81_FL : 272|16@1- (0.01,0) [-20|20] "degree"  ASDM
 SG_ ASC_Azimuth_Correction_82_FL : 288|16@1- (0.01,0) [-20|20] "degree"  ASDM
 SG_ ASC_Azimuth_Correction_83_FL : 304|16@1- (0.01,0) [-20|20] "degree"  ASDM
 SG_ ASC_Azimuth_Correction_84_FL : 320|16@1- (0.01,0) [-20|20] "degree"  ASDM
 SG_ ASC_Azimuth_Correction_85_FL : 336|16@1- (0.01,0) [-20|20] "degree"  ASDM
 SG_ ASC_Azimuth_Correction_86_FL : 352|16@1- (0.01,0) [-20|20] "degree"  ASDM
 SG_ ASC_Azimuth_Correction_87_FL : 368|16@1- (0.01,0) [-20|20] "degree"  ASDM
 SG_ ASC_Azimuth_Correction_88_FL : 384|16@1- (0.01,0) [-20|20] "degree"  ASDM
 SG_ ASC_Azimuth_Correction_89_FL : 400|16@1- (0.01,0) [-20|20] "degree"  ASDM
 SG_ ASC_Azimuth_Correction_90_FL : 416|16@1- (0.01,0) [-20|20] "degree"  ASDM
 SG_ ASC_Azimuth_Correction_91_FL : 432|16@1- (0.01,0) [-20|20] "degree"  ASDM
 SG_ ASC_Azimuth_Correction_92_FL : 448|16@1- (0.01,0) [-20|20] "degree"  ASDM
 SG_ ASC_Azimuth_Correction_93_FL : 464|16@1- (0.01,0) [-20|20] "degree"  ASDM
 SG_ ASC_Azimuth_Correction_94_FL : 480|16@1- (0.01,0) [-20|20] "degree"  ASDM
 SG_ ASC_Azimuth_Correction_95_FL : 496|16@1- (0.01,0) [-20|20] "degree"  ASDM

BO_ 1310 MB79_ASC_CORRECTION_3_FL: 64 FSRL
 SG_ ASC_Azimuth_Correction_96_FL : 0|16@1- (0.01,0) [-20|20] "degree"  ASDM
 SG_ ASC_Azimuth_Correction_97_FL : 16|16@1- (0.01,0) [-20|20] "degree"  ASDM
 SG_ ASC_Azimuth_Correction_98_FL : 32|16@1- (0.01,0) [-20|20] "degree"  ASDM
 SG_ ASC_Azimuth_Correction_99_FL : 48|16@1- (0.01,0) [-20|20] "degree"  ASDM
 SG_ ASC_Azimuth_Correction_100_FL : 64|16@1- (0.01,0) [-20|20] "degree"  ASDM
 SG_ ASC_Azimuth_Correction_101_FL : 80|16@1- (0.01,0) [-20|20] "degree"  ASDM
 SG_ ASC_Azimuth_Correction_102_FL : 96|16@1- (0.01,0) [-20|20] "degree"  ASDM
 SG_ ASC_Azimuth_Correction_103_FL : 112|16@1- (0.01,0) [-20|20] "degree"  ASDM
 SG_ ASC_Azimuth_Correction_104_FL : 128|16@1- (0.01,0) [-20|20] "degree"  ASDM
 SG_ ASC_Azimuth_Correction_105_FL : 144|16@1- (0.01,0) [-20|20] "degree"  ASDM
 SG_ ASC_Azimuth_Correction_106_FL : 160|16@1- (0.01,0) [-20|20] "degree"  ASDM
 SG_ ASC_Azimuth_Correction_107_FL : 176|16@1- (0.01,0) [-20|20] "degree"  ASDM
 SG_ ASC_Azimuth_Correction_108_FL : 192|16@1- (0.01,0) [-20|20] "degree"  ASDM
 SG_ ASC_Azimuth_Correction_109_FL : 208|16@1- (0.01,0) [-20|20] "degree"  ASDM
 SG_ ASC_Azimuth_Correction_110_FL : 224|16@1- (0.01,0) [-20|20] "degree"  ASDM
 SG_ ASC_Azimuth_Correction_111_FL : 240|16@1- (0.01,0) [-20|20] "degree"  ASDM
 SG_ ASC_Azimuth_Correction_112_FL : 256|16@1- (0.01,0) [-20|20] "degree"  ASDM
 SG_ ASC_Azimuth_Correction_113_FL : 272|16@1- (0.01,0) [-20|20] "degree"  ASDM
 SG_ ASC_Azimuth_Correction_114_FL : 288|16@1- (0.01,0) [-20|20] "degree"  ASDM
 SG_ ASC_Azimuth_Correction_115_FL : 304|16@1- (0.01,0) [-20|20] "degree"  ASDM
 SG_ ASC_Azimuth_Correction_116_FL : 320|16@1- (0.01,0) [-20|20] "degree"  ASDM
 SG_ ASC_Azimuth_Correction_117_FL : 336|16@1- (0.01,0) [-20|20] "degree"  ASDM
 SG_ ASC_Azimuth_Correction_118_FL : 352|16@1- (0.01,0) [-20|20] "degree"  ASDM
 SG_ ASC_Azimuth_Correction_119_FL : 368|16@1- (0.01,0) [-20|20] "degree"  ASDM
 SG_ ASC_Azimuth_Correction_120_FL : 384|16@1- (0.01,0) [-20|20] "degree"  ASDM
 SG_ ASC_Azimuth_Correction_121_FL : 400|16@1- (0.01,0) [-20|20] "degree"  ASDM
 SG_ ASC_Azimuth_Correction_122_FL : 416|16@1- (0.01,0) [-20|20] "degree"  ASDM
 SG_ ASC_Azimuth_Correction_123_FL : 432|16@1- (0.01,0) [-20|20] "degree"  ASDM
 SG_ ASC_Azimuth_Correction_124_FL : 448|16@1- (0.01,0) [-20|20] "degree"  ASDM
 SG_ ASC_Azimuth_Correction_125_FL : 464|16@1- (0.01,0) [-20|20] "degree"  ASDM
 SG_ ASC_Azimuth_Correction_126_FL : 480|16@1- (0.01,0) [-20|20] "degree"  ASDM
 SG_ ASC_Azimuth_Correction_127_FL : 496|16@1- (0.01,0) [-20|20] "degree"  ASDM

CM_ BO_ 416 "used for network Management";
CM_ SG_ 416 NM_Sig_0_ASDM "Network Manegement Signal";
CM_ SG_ 416 NM_Sig_1_ASDM "Network Manegement Signal";
CM_ SG_ 416 NM_Sig_2_ASDM "Network Manegement Signal";
CM_ SG_ 416 NM_Sig_3_ASDM "Network Manegement Signal";
CM_ SG_ 416 NM_Sig_4_ASDM "Network Manegement Signal";
CM_ SG_ 416 NM_Sig_5_ASDM "Network Manegement Signal";
CM_ SG_ 416 NM_Sig_6_ASDM "Network Manegement Signal";
CM_ SG_ 416 NM_Sig_7_ASDM "Network Manegement Signal";
CM_ BO_ 1024 "This MSG is Received by sensor for XCP calibration";
CM_ SG_ 1024 XCP_Master_0_ASDM_FL "This signal is received by sensor for XCP calibration";
CM_ SG_ 1024 XCP_Master_1_ASDM_FL "This signal is received by sensor for XCP calibration";
CM_ SG_ 1024 XCP_Master_2_ASDM_FL "This signal is received by sensor for XCP calibration";
CM_ SG_ 1024 XCP_Master_3_ASDM_FL "This signal is received by sensor for XCP calibration";
CM_ SG_ 1024 XCP_Master_4_ASDM_FL "This signal is received by sensor for XCP calibration";
CM_ SG_ 1024 XCP_Master_5_ASDM_FL "This signal is received by sensor for XCP calibration";
CM_ SG_ 1024 XCP_Master_6_ASDM_FL "This signal is received by sensor for XCP calibration";
CM_ SG_ 1024 XCP_Master_7_ASDM_FL "This signal is received by sensor for XCP calibration";
CM_ BO_ 1025 "This MSG is Sent by sensor for XCP calibration";
CM_ SG_ 1025 XCP_Slave_0_FL "This signal is sent by sensor for XCP calibration";
CM_ SG_ 1025 XCP_Slave_1_FL "This signal is sent by sensor for XCP calibration";
CM_ SG_ 1025 XCP_Slave_2_FL "This signal is sent by sensor for XCP calibration";
CM_ SG_ 1025 XCP_Slave_3_FL "This signal is sent by sensor for XCP calibration";
CM_ SG_ 1025 XCP_Slave_4_FL "This signal is sent by sensor for XCP calibration";
CM_ SG_ 1025 XCP_Slave_5_FL "This signal is sent by sensor for XCP calibration";
CM_ SG_ 1025 XCP_Slave_6_FL "This signal is sent by sensor for XCP calibration";
CM_ SG_ 1025 XCP_Slave_7_FL "This signal is sent by sensor for XCP calibration";
CM_ BO_ 1026 "This MSG is Received by sensor for XCP calibration";
CM_ SG_ 1026 XCP_Master_0_ASDM_FR "This signal is received by sensor for XCP calibration";
CM_ SG_ 1026 XCP_Master_1_ASDM_FR "This signal is received by sensor for XCP calibration";
CM_ SG_ 1026 XCP_Master_2_ASDM_FR "This signal is received by sensor for XCP calibration";
CM_ SG_ 1026 XCP_Master_3_ASDM_FR "This signal is received by sensor for XCP calibration";
CM_ SG_ 1026 XCP_Master_4_ASDM_FR "This signal is received by sensor for XCP calibration";
CM_ SG_ 1026 XCP_Master_5_ASDM_FR "This signal is received by sensor for XCP calibration";
CM_ SG_ 1026 XCP_Master_6_ASDM_FR "This signal is received by sensor for XCP calibration";
CM_ SG_ 1026 XCP_Master_7_ASDM_FR "This signal is received by sensor for XCP calibration";
CM_ BO_ 1027 "This MSG is Sent by sensor for XCP calibration";
CM_ SG_ 1027 XCP_Slave_0_FR "This signal is sent by sensor for XCP calibration";
CM_ SG_ 1027 XCP_Slave_1_FR "This signal is sent by sensor for XCP calibration";
CM_ SG_ 1027 XCP_Slave_2_FR "This signal is sent by sensor for XCP calibration";
CM_ SG_ 1027 XCP_Slave_3_FR "This signal is sent by sensor for XCP calibration";
CM_ SG_ 1027 XCP_Slave_4_FR "This signal is sent by sensor for XCP calibration";
CM_ SG_ 1027 XCP_Slave_5_FR "This signal is sent by sensor for XCP calibration";
CM_ SG_ 1027 XCP_Slave_6_FR "This signal is sent by sensor for XCP calibration";
CM_ SG_ 1027 XCP_Slave_7_FR "This signal is sent by sensor for XCP calibration";
CM_ BO_ 3 "Time Sync Message used by CanTSync for Syncing FR with DSF";
CM_ BO_ 257 "Detection Header Message";
CM_ SG_ 257 CycleNumber_FL "AliveCounter/MCC";
CM_ BO_ 304 "DetectionList";
CM_ BO_ 305 "DetectionList";
CM_ BO_ 306 "DetectionList";
CM_ BO_ 307 "DetectionList";
CM_ BO_ 308 "DetectionList";
CM_ BO_ 309 "DetectionList";
CM_ BO_ 310 "DetectionList";
CM_ BO_ 311 "DetectionList";
CM_ BO_ 312 "DetectionList";
CM_ BO_ 313 "DetectionList";
CM_ BO_ 314 "DetectionList";
CM_ BO_ 315 "DetectionList";
CM_ BO_ 316 "DetectionList";
CM_ BO_ 317 "DetectionList";
CM_ BO_ 318 "DetectionList";
CM_ BO_ 319 "DetectionList";
CM_ BO_ 320 "DetectionList";
CM_ BO_ 321 "DetectionList";
CM_ BO_ 322 "DetectionList";
CM_ BO_ 323 "DetectionList";
CM_ BO_ 324 "DetectionList";
CM_ BO_ 325 "DetectionList";
CM_ BO_ 326 "DetectionList";
CM_ BO_ 327 "DetectionList";
CM_ BO_ 328 "DetectionList";
CM_ BO_ 329 "DetectionList";
CM_ BO_ 330 "DetectionList";
CM_ BO_ 331 "DetectionList";
CM_ BO_ 332 "DetectionList";
CM_ BO_ 333 "DetectionList";
CM_ BO_ 334 "DetectionList";
CM_ BO_ 335 "DetectionList";
CM_ BO_ 336 "DetectionList";
CM_ BO_ 337 "DetectionList";
CM_ BO_ 338 "DetectionList";
CM_ BO_ 339 "DetectionList";
CM_ BO_ 340 "DetectionList";
CM_ BO_ 341 "DetectionList";
CM_ BO_ 342 "DetectionList";
CM_ BO_ 343 "DetectionList";
CM_ BO_ 344 "DetectionList";
CM_ BO_ 345 "DetectionList";
CM_ BO_ 346 "DetectionList";
CM_ BO_ 347 "DetectionList";
CM_ BO_ 348 "DetectionList";
CM_ BO_ 349 "DetectionList";
CM_ BO_ 350 "DetectionList";
CM_ BO_ 351 "DetectionList";
CM_ BO_ 352 "DetectionList";
CM_ BO_ 353 "DetectionList";
CM_ BO_ 354 "DetectionList";
CM_ BO_ 355 "DetectionList";
CM_ BO_ 356 "DetectionList";
CM_ BO_ 357 "DetectionList";
CM_ BO_ 358 "DetectionList";
CM_ BO_ 359 "DetectionList";
CM_ BO_ 769 "Vehicle Data Message used by comh to recieve the Vehicle Data";
CM_ SG_ 769 HostGear_ASDM "Host gear shift";
CM_ BO_ 784 "Processing Profil Message used by app to send Profiling Data To PC when available";
CM_ BO_ 785 "AASC Result";
CM_ BO_ 786 "Send the Voltage state to PC";
CM_ BO_ 787 "Send Eagle and MCU Tempreture to PC";
CM_ BO_ 788 "Versions Message used by comh to send SW versions";
CM_ SG_ 788 LCP2_Data_Ver_Major_FL "LCP2 version";
CM_ SG_ 788 LCP2_Data_Ver_Minor_FL "LCP2 version";
CM_ SG_ 788 LCP2_Design_Ver_Major_FL "LCP2 version";
CM_ SG_ 788 LCP2_Design_Ver_Minor_FL "LCP2 version";
CM_ SG_ 788 LCP3_SR_Ver_Major_FL "LCP3 Version Major - Parking mode (Short Range)";
CM_ SG_ 788 LCP3_SR_Ver_Minor_FL "LCP3 Version Minor - Parking mode (Short Range)";
CM_ SG_ 788 LCP3_SR_Ver_Build_FL "LCP3 Version Build - Parking mode (Short Range)";
CM_ SG_ 788 LCP3_LR_Ver_Major_FL "LCP3 Version Major - Driving mode (Long Range)";
CM_ SG_ 788 LCP3_LR_Ver_Minor_FL "LCP3 Version Minor - Driving mode (Long Range)";
CM_ SG_ 788 LCP3_LR_Ver_Build_FL "LCP3 Version Build - Driving mode (Long Range)";
CM_ BO_ 1290 "LLST Response";
CM_ BO_ 1291 "LLST Response";
CM_ BO_ 1292 "LLST Response";
CM_ BO_ 1293 "LLST Response";
CM_ BO_ 1294 "LLST Response";
CM_ BO_ 1295 "LLST Response";
CM_ BO_ 1296 "LLST Response";
CM_ BO_ 1297 "LLST Response";
CM_ BO_ 1298 "LLST Response";
CM_ BO_ 1299 "LLST Response";
CM_ BO_ 1300 "LLST Response";
CM_ BO_ 1301 "LLST Response";
CM_ BO_ 1302 "LLST Response";
CM_ BO_ 1303 "LLST Response";
CM_ BO_ 1304 "LLST Response";
CM_ BO_ 1305 "LLST Response";
CM_ BO_ 1306 "LLST Response";
CM_ BO_ 1307 "Azimuth Corections from AASC";
CM_ BO_ 1308 "Azimuth Corections from AASC";
CM_ BO_ 1309 "Azimuth Corections from AASC";
CM_ BO_ 1310 "Azimuth Corections from AASC";

// Attribute definitions
BA_DEF_  "BaudRateCANFD" FLOAT 1000 10000000; // [bps]
BA_DEF_  "Baudrate" INT 1000 1000000; // [bps]
BA_DEF_  "BusType" STRING;
BA_DEF_  "DBName" STRING;
BA_DEF_  "ProtocolType" STRING;
BA_DEF_ BO_ "CANFD_BRS" ENUM "0","1";
BA_DEF_ BO_ "GenMsgCycleTime" INT 0 65536; // [ms]
BA_DEF_ BO_ "GenMsgDelayTime" INT 0 65536; // [ms]
BA_DEF_ BO_ "GenMsgSendType" ENUM "cyclic", "spontaneous", "not-used", "not-used", "not-used", "cyclicAndSpontaneous", "not-used", "cyclicIfActive", "NoMsgSendType"; // [us]
BA_DEF_ BO_ "VFrameFormat" ENUM "StandardCAN","ExtendedCAN","reserved","J1939PG","reserved","reserved","reserved","reserved","reserved","reserved","reserved","reserved","reserved","reserved","StandardCAN_FD","ExtendedCAN_FD";
BA_DEF_ SG_ "GenSigSendType" ENUM "Cyclic","OnWrite","OnWriteWithRepetition","OnChange","OnChangeWithRepetition","IfActive","IfActiveWithRepetition","NoSigSendType";
BA_DEF_ SG_ "SystemSignalLongSymbol" STRING ;
BA_DEF_ BO_ "GenMsgILSupport" ENUM "No","Yes";
BA_DEF_ BO_ "NmAsrMessage" ENUM "No","Yes";
BA_DEF_  "NmAsrBaseAddress" HEX 0 536870911;
BA_DEF_  "NmAsrMessageCount" INT 0 255;
BA_DEF_ BU_ "NodeLayerModules" STRING;
BA_DEF_ BU_ "ILused" ENUM "No","Yes";
BA_DEF_ SG_ "GenSigFuncType" ENUM "NoFun","n","n","n","n","n","n","n","n","n","n","n","n","n","n","CHK","CNT","n","n","n","CNT1","CRC1B","CRC1A","CRC1L","CRC1N","CNT4","CRC4A","CNT5","CRC5","n","n","n","n","CNT2","CRC2","CNT11","CRC11B","n","n","CRC11N";
BA_DEF_ SG_  "GenSigStartValue" FLOAT -1.79769313486232E+019 1.84467440737096E+019;

BA_DEF_DEF_ "BusType" "";
BA_DEF_DEF_ "DBName" "";
BA_DEF_DEF_ "ProtocolType" "";
BA_DEF_DEF_ "CANFD_BRS" "1";
BA_DEF_DEF_ "GenSigStartValue" 0;
BA_DEF_DEF_ "VFrameFormat" "J1939PG";
BA_DEF_DEF_ "GenSigSendType" "NoSigSendType";
BA_DEF_DEF_ "GenMsgCycleTime" 0;
BA_DEF_DEF_ "GenMsgDelayTime" 0;
BA_DEF_DEF_  "GenMsgSendType" "Spontaneous";
BA_DEF_DEF_ "GenMsgILSupport" "Yes";
BA_DEF_DEF_ "NmAsrMessage" "No";
BA_DEF_DEF_ "NmAsrBaseAddress" 1280;
BA_DEF_DEF_ "NmAsrMessageCount" 64;
BA_DEF_DEF_ "NodeLayerModules" "CANoeILNLVector.dll";
BA_DEF_DEF_ "ILused" "Yes";
BA_DEF_DEF_ "GenSigFuncType" "NoFun";
BA_DEF_DEF_  "SystemSignalLongSymbol" "";

BA_ "BaudRateCANFD" 2500000;
BA_ "Baudrate" 830000;
BA_ "BusType" "CAN FD";
BA_ "DBName" "ASDM2CANFD";
BA_ "ProtocolType" "CAN";
// Network
// ECU: ASDM
BA_ "ILused" BU_ ASDM 0;
// ECU: FSRL
BA_ "ILused" BU_ FSRL 0;
// ECU: FSRR
BA_ "ILused" BU_ FSRR 0;
// Frame: AsdmToAllFuncAsdm2CanDiagReqFrame
BA_ "GenMsgDelayTime" BO_ 2047 5.000;
BA_ "GenMsgSendType" BO_ 2047 1;
BA_ "VFrameFormat" BO_ 2047 14;
// Frame: AsdmToFsrlAsdm2CanDiagReqFrame
BA_ "GenMsgDelayTime" BO_ 1937 5.000;
BA_ "GenMsgSendType" BO_ 1937 1;
BA_ "VFrameFormat" BO_ 1937 14;
// Frame: AsdmToFsrrAsdm2CanDiagReqFrame
BA_ "GenMsgDelayTime" BO_ 1938 5.000;
BA_ "GenMsgSendType" BO_ 1938 1;
BA_ "VFrameFormat" BO_ 1938 14;
// Frame: FsrlToAsdmAsdm2CanDiagResFrame
BA_ "GenMsgDelayTime" BO_ 1681 5.000;
BA_ "GenMsgSendType" BO_ 1681 1;
BA_ "VFrameFormat" BO_ 1681 14;
// Frame: FsrrToAsdmAsdm2CanDiagResFrame
BA_ "GenMsgDelayTime" BO_ 1682 5.000;
BA_ "GenMsgSendType" BO_ 1682 1;
BA_ "VFrameFormat" BO_ 1682 14;

BA_ "GenMsgSendType" BO_ 134 1;
BA_ "VFrameFormat" BO_ 134 14;
BA_ "GenMsgSendType" BO_ 6 1;
BA_ "VFrameFormat" BO_ 6 14;
BA_ "GenMsgSendType" BO_ 917 0;
BA_ "GenMsgCycleTime" BO_ 917 1000;
BA_ "VFrameFormat" BO_ 917 14;
BA_ "GenMsgSendType" BO_ 789 0;
BA_ "GenMsgCycleTime" BO_ 789 1000;
BA_ "VFrameFormat" BO_ 789 14;
BA_ "GenMsgSendType" BO_ 898 0;
BA_ "GenMsgCycleTime" BO_ 898 50;
BA_ "VFrameFormat" BO_ 898 14;
BA_ "GenMsgSendType" BO_ 770 0;
BA_ "GenMsgCycleTime" BO_ 770 50;
BA_ "VFrameFormat" BO_ 770 14;
BA_ "GenMsgSendType" BO_ 918 1;
BA_ "VFrameFormat" BO_ 918 14;
BA_ "GenMsgSendType" BO_ 790 1;
BA_ "VFrameFormat" BO_ 790 14;
BA_ "GenMsgSendType" BO_ 416 1;
BA_ "VFrameFormat" BO_ 416 14;
BA_ "GenMsgSendType" BO_ 288 0;
BA_ "GenMsgCycleTime" BO_ 288 25;
BA_ "VFrameFormat" BO_ 288 14;
BA_ "GenMsgSendType" BO_ 1024 1;
BA_ "GenMsgILSupport" BO_ 1024 0;
BA_ "VFrameFormat" BO_ 1024 14;
BA_ "GenMsgSendType" BO_ 1025 1;
BA_ "GenMsgILSupport" BO_ 1025 0;
BA_ "VFrameFormat" BO_ 1025 14;
BA_ "GenMsgILSupport" BO_ 1026 0;
BA_ "GenMsgSendType" BO_ 1026 1;
BA_ "VFrameFormat" BO_ 1026 14;
BA_ "GenMsgILSupport" BO_ 1027 0;
BA_ "GenMsgSendType" BO_ 1027 1;
BA_ "VFrameFormat" BO_ 1027 14;
BA_ "GenMsgSendType" BO_ 3 1;
BA_ "VFrameFormat" BO_ 3 14;
BA_ "GenMsgSendType" BO_ 257 1;
BA_ "VFrameFormat" BO_ 257 14;
BA_ "GenMsgSendType" BO_ 304 1;
BA_ "VFrameFormat" BO_ 304 14;
BA_ "GenMsgSendType" BO_ 305 1;
BA_ "VFrameFormat" BO_ 305 14;
BA_ "GenMsgSendType" BO_ 306 1;
BA_ "VFrameFormat" BO_ 306 14;
BA_ "GenMsgSendType" BO_ 307 1;
BA_ "VFrameFormat" BO_ 307 14;
BA_ "GenMsgSendType" BO_ 308 1;
BA_ "VFrameFormat" BO_ 308 14;
BA_ "GenMsgSendType" BO_ 309 1;
BA_ "VFrameFormat" BO_ 309 14;
BA_ "GenMsgSendType" BO_ 310 1;
BA_ "VFrameFormat" BO_ 310 14;
BA_ "GenMsgSendType" BO_ 311 1;
BA_ "VFrameFormat" BO_ 311 14;
BA_ "GenMsgSendType" BO_ 312 1;
BA_ "VFrameFormat" BO_ 312 14;
BA_ "GenMsgSendType" BO_ 313 1;
BA_ "VFrameFormat" BO_ 313 14;
BA_ "GenMsgSendType" BO_ 314 1;
BA_ "VFrameFormat" BO_ 314 14;
BA_ "GenMsgSendType" BO_ 315 1;
BA_ "VFrameFormat" BO_ 315 14;
BA_ "GenMsgSendType" BO_ 316 1;
BA_ "VFrameFormat" BO_ 316 14;
BA_ "GenMsgSendType" BO_ 317 1;
BA_ "VFrameFormat" BO_ 317 14;
BA_ "GenMsgSendType" BO_ 318 1;
BA_ "VFrameFormat" BO_ 318 14;
BA_ "GenMsgSendType" BO_ 319 1;
BA_ "VFrameFormat" BO_ 319 14;
BA_ "GenMsgSendType" BO_ 320 1;
BA_ "VFrameFormat" BO_ 320 14;
BA_ "GenMsgSendType" BO_ 321 1;
BA_ "VFrameFormat" BO_ 321 14;
BA_ "GenMsgSendType" BO_ 322 1;
BA_ "VFrameFormat" BO_ 322 14;
BA_ "GenMsgSendType" BO_ 323 1;
BA_ "VFrameFormat" BO_ 323 14;
BA_ "GenMsgSendType" BO_ 324 1;
BA_ "VFrameFormat" BO_ 324 14;
BA_ "GenMsgSendType" BO_ 325 1;
BA_ "VFrameFormat" BO_ 325 14;
BA_ "GenMsgSendType" BO_ 326 1;
BA_ "VFrameFormat" BO_ 326 14;
BA_ "GenMsgSendType" BO_ 327 1;
BA_ "VFrameFormat" BO_ 327 14;
BA_ "GenMsgSendType" BO_ 328 1;
BA_ "VFrameFormat" BO_ 328 14;
BA_ "GenMsgSendType" BO_ 329 1;
BA_ "VFrameFormat" BO_ 329 14;
BA_ "GenMsgSendType" BO_ 330 1;
BA_ "VFrameFormat" BO_ 330 14;
BA_ "GenMsgSendType" BO_ 331 1;
BA_ "VFrameFormat" BO_ 331 14;
BA_ "GenMsgSendType" BO_ 332 1;
BA_ "VFrameFormat" BO_ 332 14;
BA_ "GenMsgSendType" BO_ 333 1;
BA_ "VFrameFormat" BO_ 333 14;
BA_ "GenMsgSendType" BO_ 334 1;
BA_ "VFrameFormat" BO_ 334 14;
BA_ "GenMsgSendType" BO_ 335 1;
BA_ "VFrameFormat" BO_ 335 14;
BA_ "GenMsgSendType" BO_ 336 1;
BA_ "VFrameFormat" BO_ 336 14;
BA_ "GenMsgSendType" BO_ 337 1;
BA_ "VFrameFormat" BO_ 337 14;
BA_ "GenMsgSendType" BO_ 338 1;
BA_ "VFrameFormat" BO_ 338 14;
BA_ "GenMsgSendType" BO_ 339 1;
BA_ "VFrameFormat" BO_ 339 14;
BA_ "GenMsgSendType" BO_ 340 1;
BA_ "VFrameFormat" BO_ 340 14;
BA_ "GenMsgSendType" BO_ 341 1;
BA_ "VFrameFormat" BO_ 341 14;
BA_ "GenMsgSendType" BO_ 342 1;
BA_ "VFrameFormat" BO_ 342 14;
BA_ "GenMsgSendType" BO_ 343 1;
BA_ "VFrameFormat" BO_ 343 14;
BA_ "GenMsgSendType" BO_ 344 1;
BA_ "VFrameFormat" BO_ 344 14;
BA_ "GenMsgSendType" BO_ 345 1;
BA_ "VFrameFormat" BO_ 345 14;
BA_ "GenMsgSendType" BO_ 346 1;
BA_ "VFrameFormat" BO_ 346 14;
BA_ "GenMsgSendType" BO_ 347 1;
BA_ "VFrameFormat" BO_ 347 14;
BA_ "GenMsgSendType" BO_ 348 1;
BA_ "VFrameFormat" BO_ 348 14;
BA_ "GenMsgSendType" BO_ 349 1;
BA_ "VFrameFormat" BO_ 349 14;
BA_ "GenMsgSendType" BO_ 350 1;
BA_ "VFrameFormat" BO_ 350 14;
BA_ "GenMsgSendType" BO_ 351 1;
BA_ "VFrameFormat" BO_ 351 14;
BA_ "GenMsgSendType" BO_ 352 1;
BA_ "VFrameFormat" BO_ 352 14;
BA_ "GenMsgSendType" BO_ 353 1;
BA_ "VFrameFormat" BO_ 353 14;
BA_ "GenMsgSendType" BO_ 354 1;
BA_ "VFrameFormat" BO_ 354 14;
BA_ "GenMsgSendType" BO_ 355 1;
BA_ "VFrameFormat" BO_ 355 14;
BA_ "GenMsgSendType" BO_ 356 1;
BA_ "VFrameFormat" BO_ 356 14;
BA_ "GenMsgSendType" BO_ 357 1;
BA_ "VFrameFormat" BO_ 357 14;
BA_ "GenMsgSendType" BO_ 358 1;
BA_ "VFrameFormat" BO_ 358 14;
BA_ "GenMsgSendType" BO_ 359 1;
BA_ "VFrameFormat" BO_ 359 14;
BA_ "GenMsgCycleTime" BO_ 769 25;
BA_ "GenMsgSendType" BO_ 769 0;
BA_ "VFrameFormat" BO_ 769 14;
BA_ "GenMsgSendType" BO_ 784 1;
BA_ "VFrameFormat" BO_ 784 14;
BA_ "GenMsgCycleTime" BO_ 785 50;
BA_ "GenMsgSendType" BO_ 785 0;
BA_ "VFrameFormat" BO_ 785 14;
BA_ "GenMsgCycleTime" BO_ 786 50;
BA_ "GenMsgSendType" BO_ 786 0;
BA_ "VFrameFormat" BO_ 786 14;
BA_ "GenMsgCycleTime" BO_ 787 50;
BA_ "GenMsgSendType" BO_ 787 0;
BA_ "VFrameFormat" BO_ 787 14;
BA_ "GenMsgSendType" BO_ 788 1;
BA_ "VFrameFormat" BO_ 788 14;
BA_ "GenMsgSendType" BO_ 1280 1;
BA_ "VFrameFormat" BO_ 1280 14;
BA_ "GenMsgSendType" BO_ 1290 1;
BA_ "VFrameFormat" BO_ 1290 14;
BA_ "GenMsgSendType" BO_ 1291 1;
BA_ "VFrameFormat" BO_ 1291 14;
BA_ "GenMsgSendType" BO_ 1292 1;
BA_ "VFrameFormat" BO_ 1292 14;
BA_ "GenMsgSendType" BO_ 1293 1;
BA_ "VFrameFormat" BO_ 1293 14;
BA_ "GenMsgSendType" BO_ 1294 1;
BA_ "VFrameFormat" BO_ 1294 14;
BA_ "GenMsgSendType" BO_ 1295 1;
BA_ "VFrameFormat" BO_ 1295 14;
BA_ "GenMsgSendType" BO_ 1296 1;
BA_ "VFrameFormat" BO_ 1296 14;
BA_ "GenMsgSendType" BO_ 1297 1;
BA_ "VFrameFormat" BO_ 1297 14;
BA_ "GenMsgSendType" BO_ 1298 1;
BA_ "VFrameFormat" BO_ 1298 14;
BA_ "GenMsgSendType" BO_ 1299 1;
BA_ "VFrameFormat" BO_ 1299 14;
BA_ "GenMsgSendType" BO_ 1300 1;
BA_ "VFrameFormat" BO_ 1300 14;
BA_ "GenMsgSendType" BO_ 1301 1;
BA_ "VFrameFormat" BO_ 1301 14;
BA_ "GenMsgSendType" BO_ 1302 1;
BA_ "VFrameFormat" BO_ 1302 14;
BA_ "GenMsgSendType" BO_ 1303 1;
BA_ "VFrameFormat" BO_ 1303 14;
BA_ "GenMsgSendType" BO_ 1304 1;
BA_ "VFrameFormat" BO_ 1304 14;
BA_ "GenMsgSendType" BO_ 1305 1;
BA_ "VFrameFormat" BO_ 1305 14;
BA_ "GenMsgSendType" BO_ 1306 1;
BA_ "VFrameFormat" BO_ 1306 14;
BA_ "GenMsgSendType" BO_ 1307 1;
BA_ "VFrameFormat" BO_ 1307 14;
BA_ "GenMsgSendType" BO_ 1308 1;
BA_ "VFrameFormat" BO_ 1308 14;
BA_ "GenMsgSendType" BO_ 1309 1;
BA_ "VFrameFormat" BO_ 1309 14;
BA_ "GenMsgSendType" BO_ 1310 1;
BA_ "VFrameFormat" BO_ 1310 14;
BA_ "SystemSignalLongSymbol" SG_ 898 Sensor_Error_Synchronization_Err "Sensor_Error_Synchronization_Error_FR";
BA_ "SystemSignalLongSymbol" SG_ 898 Sensor_Error_Software_Incompatib "Sensor_Error_Software_Incompatible_FR";
BA_ "SystemSignalLongSymbol" SG_ 898 Sensor_Error_Calibration_Error_F "Sensor_Error_Calibration_Error_FR";
BA_ "SystemSignalLongSymbol" SG_ 770 Sensor_Error_Synchronizatio_0000 "Sensor_Error_Synchronization_Error_FL";
BA_ "SystemSignalLongSymbol" SG_ 770 Sensor_Error_Software_Incom_0000 "Sensor_Error_Software_Incompatible_FL";
BA_ "SystemSignalLongSymbol" SG_ 770 Sensor_Error_Calibration_Er_0000 "Sensor_Error_Calibration_Error_FL";
BA_ "GenSigStartValue" SG_ 769 HostGear_ASDM 1;
VAL_ 898 Sensor_Operation_Mode_FR 0 "Undefined" 1 "Startup" 2 "Normal_Run" 3 "Faulty" 5 "Shutdown" 7 "Testing" 15 "Transaction_Mode" ;
VAL_ 770 Sensor_Operation_Mode_FL 0 "Undefined" 1 "Startup" 2 "Normal_Run" 3 "Faulty" 5 "Shutdown" 7 "Testing" 15 "Transaction_Mode" ;
VAL_ 288 CarModSts1 0 "CarModSts1_CarModNorm" 1 "CarModSts1_CarModTrnsp" 2 "CarModSts1_CarModFcy" 3 "CarModSts1_CarModCrash" 4 "CarModSts1_CarModDyno" ;
VAL_ 3 Type_EXT_ASDM 16 "CANTSYN_SYNC_NOT_CRC_SECURED" 32 "CANTSYN_SYNC_CRC_SECURED" 24 "CANTSYN_FUP_NOT_CRC_SECURED" 40 "CANTSYN_FUP_CRC_SECURED" 48 "CANTSYN_OFS_NOT_CRC_SECURED" 64 "CANTSYN_OFS_CRC_SECURED" 56 "CANTSYN_OFNS_NOT_CRC_SECURED" 72 "CANTSYN_OFNS_CRC_SECURED" ;
VAL_ 257 UnambiguousVelMeas1_FL 0 "TPRI_69us" 1 "TPRI_82.8us" 2 "TPRI_96.6us" ;
VAL_ 257 Radar_Sensor_type_FL 0 "Gen1.1" 1 "Gen1.2" 2 "MB79_A6" 3 "MCR2" 4 "MFR1" 5 "MFR1_2" 6 "MCR1_2_E" 7 "MFR1_2_E" ;
VAL_ 257 Sensor_Position_ID_FL 0 "FL" 1 "FR" 2 "RL" 3 "RR" 4 "MFR" 5 "Reserved" 6 "Reserved" 7 "Reserved" ;
VAL_ 257 interferenceDetected_FL 0 "False" 1 "True" ;
VAL_ 257 Blockage_Status_FL 0 "Unblocked" 1 "Blocked" 2 "Partial_Low" 3 "Partial_Medium" 4 "Partial_High" ;

VAL_ 257 AutoAlignment_Status_FL 0 "Reserved" 1 "Reserved" 2 "Reserved" 3 "Online Validation" 4 "Online DBAA (or Coarse Alignment)" 5 "Online ASC (or Fine Alignment)" 6 "Aligned" 7 "MisAligned" 14 "Manual" 15 "Inactive" ;
VAL_ 257 Testing_Mode_FL 0 "No_Test_Mode_Active" 1 "END_OF_LINE_TEST" 2 "HILT" 3 "LLHT_beam_pattern" 4 "LLHT_video" 5 "LLHT_FFT2D" 6 "LLHT_FFT3D_CMPLX" 7 "EIRP" 8 "LLHT_FFT3D_SPEC" 9 "Z7_CORES_IDLE" 10 "OSM_MODE" 11 "EMC" ;
VAL_ 257 Detection_Data_Mode_FL 1 "Parking mode data" 0 "Driving mode data" ;
VAL_ 257 Sensor_Topology_FL 0 "Master" 1 "Slave" ;
VAL_ 257 AASC_Calibration_flag_FL 1 "Calibration complete" 0 "Calibration Not complete" ;
VAL_ 257 selected_chirp_config_FL 0 "64" 1 "128" 2 "256" 3 "512" 4 "1024" 5 "2048" ;
VAL_ 257 ElevAlignment_Status_FL 2 "MBASC_ELEV_MISALIGNED" 1 "MBASC_ELEV_ALIGNED" 0 "MBASC_ELEV_CALIBRATING" ;
VAL_ 769 VehiclePower_Gear_ASDM 15 "Invalid" 8 "Start" 4 "Run" 3 "ON" 2 "ACC" 1 "OFF" 0 "Uknown" ;
VAL_ 769 HostTrailerAttached_ASDM 0 "not_connected" 1 "connected" ;
VAL_ 769 HostDrivingForward_ASDM 0 "False" 1 "True" ;
VAL_ 769 HostGear_ASDM 0 "Gear_P" 1 "Gear_1" 2 "Gear_2" 3 "Gear_3" 4 "Gear_4" 5 "Gear_5" 6 "Gear_6" 7 "Gear_7" 8 "Gear_R" 9 "Gear_N" 11 "Gear_8" 12 "Gear_9" 14 "Gear_not_defined" 15 "Error" ;
VAL_ 784 Function_ID_0_FL 0 "Empty_FUNC_ID" 1 "ICCM_DSS_FUNC_HWA1D_RUN" 2 "ICCM_DSS_FUNC_HWA2D_CONFIG" 3 "ICCM_DSS_FUNC_HWA2D_RUN" 4 "ICCM_DSS_FUNC_C1SA_RUN" 5 "ICCM_DSS_FUNC_C1CG_RUN" 6 "ICCM_DSS_FUNC_NRLC" 7 "ICCM_DSS_FUNC_SPEC" 8 "ICCM_DSS_FUNC_CFAR" 9 "ICCM_DSS_FUNC_DETC" 10 "ICCM_DSS_FUNC_DOAE" 11 "ICCM_DSS_FUNC_FECL" 12 "ICCM_DSS_FUNC_HPRM" 13 "ICCM_DSS_FUNC_AASC" 14 "ICCM_DSS_FUNC_INFC" 15 "ICCM_DSS_FUNC_RVVP" 16 "ICCM_DSS_FUNC_PRPC" 17 "ICCM_DSS_FUNC_PRPC_HWA_CONFIG" 18 "ICCM_DSS_FUNC_PRPC_RECONFIG" 19 "ICCM_DSS_FUNC_PRPC_AASC_MSG" 20 "ICCM_DSS_FUNC_PRPC_LAST_MSG" 255 "STACK_USAGE" ;
VAL_ 784 Function_ID_1_FL 0 "Empty_FUNC_ID" 1 "ICCM_DSS_FUNC_HWA1D_RUN" 2 "ICCM_DSS_FUNC_HWA2D_CONFIG" 3 "ICCM_DSS_FUNC_HWA2D_RUN" 4 "ICCM_DSS_FUNC_C1SA_RUN" 5 "ICCM_DSS_FUNC_C1CG_RUN" 6 "ICCM_DSS_FUNC_NRLC" 7 "ICCM_DSS_FUNC_SPEC" 8 "ICCM_DSS_FUNC_CFAR" 9 "ICCM_DSS_FUNC_DETC" 10 "ICCM_DSS_FUNC_DOAE" 11 "ICCM_DSS_FUNC_FECL" 12 "ICCM_DSS_FUNC_HPRM" 13 "ICCM_DSS_FUNC_AASC" 14 "ICCM_DSS_FUNC_INFC" 15 "ICCM_DSS_FUNC_RVVP" 16 "ICCM_DSS_FUNC_PRPC" 17 "ICCM_DSS_FUNC_PRPC_HWA_CONFIG" 18 "ICCM_DSS_FUNC_PRPC_RECONFIG" 19 "ICCM_DSS_FUNC_PRPC_AASC_MSG" 20 "ICCM_DSS_FUNC_PRPC_LAST_MSG" 255 "STACK_USAGE" ;
VAL_ 784 Function_ID_2_FL 0 "Empty_FUNC_ID" 1 "ICCM_DSS_FUNC_HWA1D_RUN" 2 "ICCM_DSS_FUNC_HWA2D_CONFIG" 3 "ICCM_DSS_FUNC_HWA2D_RUN" 4 "ICCM_DSS_FUNC_C1SA_RUN" 5 "ICCM_DSS_FUNC_C1CG_RUN" 6 "ICCM_DSS_FUNC_NRLC" 7 "ICCM_DSS_FUNC_SPEC" 8 "ICCM_DSS_FUNC_CFAR" 9 "ICCM_DSS_FUNC_DETC" 10 "ICCM_DSS_FUNC_DOAE" 11 "ICCM_DSS_FUNC_FECL" 12 "ICCM_DSS_FUNC_HPRM" 13 "ICCM_DSS_FUNC_AASC" 14 "ICCM_DSS_FUNC_INFC" 15 "ICCM_DSS_FUNC_RVVP" 16 "ICCM_DSS_FUNC_PRPC" 17 "ICCM_DSS_FUNC_PRPC_HWA_CONFIG" 18 "ICCM_DSS_FUNC_PRPC_RECONFIG" 19 "ICCM_DSS_FUNC_PRPC_AASC_MSG" 20 "ICCM_DSS_FUNC_PRPC_LAST_MSG" 255 "STACK_USAGE" ;
VAL_ 784 Function_ID_3_FL 0 "Empty_FUNC_ID" 1 "ICCM_DSS_FUNC_HWA1D_RUN" 2 "ICCM_DSS_FUNC_HWA2D_CONFIG" 3 "ICCM_DSS_FUNC_HWA2D_RUN" 4 "ICCM_DSS_FUNC_C1SA_RUN" 5 "ICCM_DSS_FUNC_C1CG_RUN" 6 "ICCM_DSS_FUNC_NRLC" 7 "ICCM_DSS_FUNC_SPEC" 8 "ICCM_DSS_FUNC_CFAR" 9 "ICCM_DSS_FUNC_DETC" 10 "ICCM_DSS_FUNC_DOAE" 11 "ICCM_DSS_FUNC_FECL" 12 "ICCM_DSS_FUNC_HPRM" 13 "ICCM_DSS_FUNC_AASC" 14 "ICCM_DSS_FUNC_INFC" 15 "ICCM_DSS_FUNC_RVVP" 16 "ICCM_DSS_FUNC_PRPC" 17 "ICCM_DSS_FUNC_PRPC_HWA_CONFIG" 18 "ICCM_DSS_FUNC_PRPC_RECONFIG" 19 "ICCM_DSS_FUNC_PRPC_AASC_MSG" 20 "ICCM_DSS_FUNC_PRPC_LAST_MSG" 255 "STACK_USAGE" ;
VAL_ 785 AutoAlignment_ErrorType_FL 0 "OV - not enough detections (upon timeout)" 1 "OV - error too big" 2 "DBAA - estimated MAO too large" 3 "DBAA - too many bins empty" 4 "DBAA - repeatedly too many bins empty" 5 "ASC - too many bins empty" 6 "Unused" 7 "Unused" ;
VAL_ 785 AutoCalib_Status_FL 0 "Calib Not Started" 1 "Calib InProgress" 2 "Calib Successful" 3 "Not Enough Detections" 4 "Calib Not Precise Enough" 5 "Misaligned to the Left" 6 "Misaligned to the Right" 7 "MisAligned Upward" 8 "MisAligned Downward" 9 "Unused" 15 "Unused" ;
VAL_ 787 MCU_Temp_Status_FL 11 "OverThreshold" 10 "Normal" 14 "UnderThreshold" ;
VAL_ 1290 LLHT_Data_Header_Mode_ID_FL 1 "Video Mode" 2 "FFT2D Mode" 3 "FFT3D CMPLX Mode" 4 "FFT3D SPEC Mode" 5 "Beam Pattern Mode" 6 "EIRP Mode" 7 "Eagle BB" 8 "Eagle Tx" ;
SIG_GROUP_ 1024 XCP_MASTER_FL 1 : XCP_Master_0_ASDM_FL XCP_Master_1_ASDM_FL XCP_Master_2_ASDM_FL XCP_Master_3_ASDM_FL XCP_Master_4_ASDM_FL XCP_Master_5_ASDM_FL XCP_Master_6_ASDM_FL XCP_Master_7_ASDM_FL;
SIG_GROUP_ 1025 XCP_SLAVE_FL 1 : XCP_Slave_0_FL XCP_Slave_1_FL XCP_Slave_2_FL XCP_Slave_3_FL XCP_Slave_4_FL XCP_Slave_5_FL XCP_Slave_6_FL XCP_Slave_7_FL;
SIG_GROUP_ 1026 XCP_MASTER_FR 1 : XCP_Master_0_ASDM_FR XCP_Master_1_ASDM_FR XCP_Master_2_ASDM_FR XCP_Master_3_ASDM_FR XCP_Master_4_ASDM_FR XCP_Master_5_ASDM_FR XCP_Master_6_ASDM_FR XCP_Master_7_ASDM_FR;
SIG_GROUP_ 1027 XCP_SLAVE_FR 1 : XCP_Slave_0_FR XCP_Slave_1_FR XCP_Slave_2_FR XCP_Slave_3_FR XCP_Slave_4_FR XCP_Slave_5_FR XCP_Slave_6_FR XCP_Slave_7_FR;
SIG_GROUP_ 785 AUTOALIGN_RESULT_FL_SG_311 1 : AutoCalib_Status_FL AutoAlignment_ErrorType_FL;
